VERSION ""

NS_ :

BS_:

BU_: FUSION IVI HMI Meter DataCenter WCM

BO_ 969 ZONE_FR_Version: 48 FUSION
 SG_ ZONE_FR_SW_Var1 : 135|8@0+ (1,0) [0|255] "" IVI
 SG_ ZONE_FR_SW_Country2 : 127|8@0+ (1,0) [0|255] "" IVI
 SG_ ZONE_FR_SW_Country1 : 119|8@0+ (1,0) [0|255] "" IVI
 SG_ ZONE_FR_SW_Patch2 : 111|8@0+ (1,0) [0|255] "" IVI
 SG_ ZONE_FR_SW_Patch1 : 103|8@0+ (1,0) [0|255] "" IVI
 SG_ ZONE_FR_SW_Minor2 : 95|8@0+ (1,0) [0|255] "" IVI
 SG_ ZONE_FR_SW_Minor1 : 87|8@0+ (1,0) [0|255] "" IVI
 SG_ ZONE_FR_SW_Major2 : 79|8@0+ (1,0) [0|255] "" IVI
 SG_ ZONE_FR_SW_Major1 : 71|8@0+ (1,0) [0|255] "" IVI
 SG_ ZONE_FR_SW_Controller2 : 63|8@0+ (1,0) [0|255] "" IVI
 SG_ ZONE_FR_SW_Controller1 : 55|8@0+ (1,0) [0|255] "" IVI
 SG_ ZONE_FR_SW_CarModel3 : 47|8@0+ (1,0) [0|255] "" IVI
 SG_ ZONE_FR_SW_CarModel2 : 39|8@0+ (1,0) [0|255] "" IVI
 SG_ ZONE_FR_SW_CarModel1 : 31|8@0+ (1,0) [0|255] "" IVI
 SG_ ZONE_FR_HW_Ver3 : 23|8@0+ (1,0) [0|255] "" IVI
 SG_ ZONE_FR_HW_Ver2 : 15|8@0+ (1,0) [0|255] "" IVI
 SG_ ZONE_FR_HW_Ver1 : 7|8@0+ (1,0) [0|255] "" IVI
 SG_ ZONE_FR_SW_dash1 : 191|8@0+ (1,0) [0|255] "" IVI
 SG_ ZONE_FR_SW_change1 : 199|8@0+ (1,0) [0|255] "" IVI
 SG_ ZONE_FR_SW_change2 : 207|8@0+ (1,0) [0|255] "" IVI
 SG_ ZONE_FR_SW_dash2 : 215|8@0+ (1,0) [0|255] "" IVI
 SG_ ZONE_FR_SW_SHA1 : 223|8@0+ (1,0) [0|255] "" IVI
 SG_ ZONE_FR_SW_SHA2 : 231|8@0+ (1,0) [0|255] "" IVI
 SG_ ZONE_FR_SW_SHA3 : 239|8@0+ (1,0) [0|255] "" IVI
 SG_ ZONE_FR_SW_SHA4 : 247|8@0+ (1,0) [0|255] "" IVI
 SG_ ZONE_FR_SW_SHA5 : 255|8@0+ (1,0) [0|255] "" IVI
 SG_ ZONE_FR_SW_SHA6 : 263|8@0+ (1,0) [0|255] "" IVI
 SG_ ZONE_FR_SW_SHA7 : 271|8@0+ (1,0) [0|255] "" IVI
 SG_ ZONE_FR_SW_SHA8 : 279|8@0+ (1,0) [0|255] "" IVI
 SG_ ZONE_FR_SW_ECUGen2 : 151|8@0+ (1,0) [0|255] "" IVI
 SG_ ZONE_FR_SW_ECUGen1 : 143|8@0+ (1,0) [0|255] "" IVI
 SG_ ZONE_FR_SW_Var5 : 183|8@0+ (1,0) [0|255] "" IVI
 SG_ ZONE_FR_SW_Var4 : 175|8@0+ (1,0) [0|255] "" IVI
 SG_ ZONE_FR_SW_Var3 : 167|8@0+ (1,0) [0|255] "" IVI
 SG_ ZONE_FR_SW_Var2 : 159|8@0+ (1,0) [0|255] "" IVI

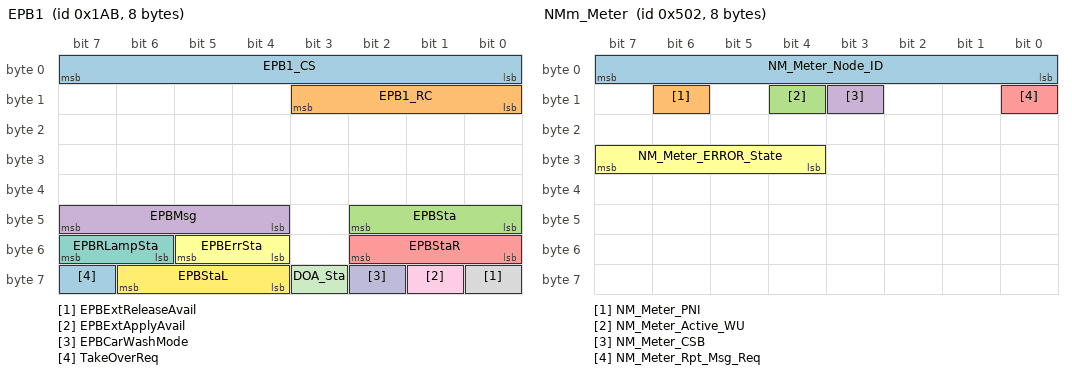
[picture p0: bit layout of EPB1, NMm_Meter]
BO_ 427 EPB1: 8 FUSION
 SG_ EPB1_CS : 7|8@0+ (1,0) [0|255] "" Vector__XXX
 SG_ EPB1_RC : 11|4@0+ (1,0) [0|14] "" Vector__XXX
 SG_ EPBSta : 42|3@0+ (1,0) [0|4] "" IVI
 SG_ EPBMsg : 47|4@0+ (1,0) [0|12] "" IVI
 SG_ EPBStaR : 50|3@0+ (1,0) [0|7] "" IVI
 SG_ EPBErrSta : 53|2@0+ (1,0) [0|2] "" IVI,Meter
 SG_ EPBRLampSta : 55|2@0+ (1,0) [0|2] "" IVI
 SG_ EPBExtReleaseAvail : 56|1@0+ (1,0) [0|1] "" Vector__XXX
 SG_ EPBExtApplyAvail : 57|1@0+ (1,0) [0|1] "" Vector__XXX
 SG_ EPBCarWashMode : 58|1@0+ (1,0) [0|1] "" IVI
 SG_ DOA_Sta : 59|1@0+ (1,0) [0|1] "" IVI
 SG_ EPBStaL : 62|3@0+ (1,0) [0|7] "" IVI
 SG_ TakeOverReq : 63|1@0+ (1,0) [0|1] "" Vector__XXX

BO_ 602 METER1: 24 IVI
 SG_ METER_KPH_Calcu : 15|8@0+ (1,0) [0|254] "km/h" FUSION
 SG_ METER_MPH_Calcu : 23|8@0+ (1,0) [0|160] "mph" FUSION
 SG_ METER_KPH_Real : 31|12@0+ (0.125,0) [0|255.875] "km/h" FUSION
 SG_ METER_MPH_Real : 35|12@0+ (0.077675,0) [0|160.0105] "mph" FUSION
 SG_ Averaged_vehspeed : 49|10@0+ (1,0) [0|300] "km/h" FUSION
 SG_ AVGPwrConsumption : 71|16@0+ (0.1,-999.9) [-999.9|999.9] "Wh/km" FUSION
 SG_ APCforDTE : 87|16@0+ (0.1,-999.9) [-999.9|999.9] "Wh/km" FUSION
 SG_ AvailableTrip : 103|16@0+ (0.1,0) [0|999.9] "KM" FUSION
 SG_ Spd_Crl_Mode : 118|3@0+ (1,0) [0|7] "" FUSION
 SG_ Spd_Crl_Sta : 115|1@0+ (1,0) [0|1] "" FUSION
 SG_ LEDlitWarnReq : 114|1@0+ (1,0) [0|1] "" FUSION
 SG_ Charge : 113|1@0+ (1,0) [0|1] "" FUSION
 SG_ ParkBrake : 112|1@0+ (1,0) [0|1] "" FUSION
 SG_ Trip_B : 127|24@0+ (0.1,0) [0|99999.9] "KM" FUSION
 SG_ Trip_A : 151|24@0+ (0.1,0) [0|99999.9] "KM" FUSION
 SG_ ODOMETER : 175|24@0+ (0.1,0) [0|999999.9] "KM" FUSION

BO_ 1168 IVI1: 20 IVI
 SG_ VehACModReq : 23|3@0+ (1,0) [0|7] "" FUSION
 SG_ FCP_FrEvt_BtnACMaxReq : 20|1@0+ (1,0) [0|1] "" FUSION
 SG_ FCP_FrEvt_BtnACReq : 19|1@0+ (1,0) [0|1] "" FUSION
 SG_ FCP_FrEvt_BtnAutoReq : 18|1@0+ (1,0) [0|1] "" FUSION
 SG_ FCP_MidEvt_BtnAutoReq : 17|1@0+ (1,0) [0|1] "" FUSION
 SG_ FCP_FrEvt_BtnSyncReq : 16|1@0+ (1,0) [0|1] "" FUSION
 SG_ OTA_DL_Req : 31|1@0+ (1,0) [0|1] "" FUSION
 SG_ OTA_SuspendDL_Req : 30|1@0+ (1,0) [0|1] "" FUSION
 SG_ OTA_UpdStart_Req : 29|1@0+ (1,0) [0|1] "" FUSION
 SG_ IVI_OTA_Upd_Sta : 28|2@0+ (1,0) [0|3] "" FUSION
 SG_ OTA_CancelDL_Req : 26|1@0+ (1,0) [0|1] "" FUSION
 SG_ SmartEco_Mode_SW : 25|1@0+ (1,0) [0|1] "" FUSION
 SG_ LINKtoDrive : 24|1@0+ (1,0) [0|1] "" FUSION
 SG_ Upd_Countdown_Skip : 39|1@0+ (1,0) [0|1] "" FUSION
 SG_ Upd_Countdown_Cancel : 38|1@0+ (1,0) [0|1] "" FUSION
 SG_ AmbLightColorSet : 46|7@0+ (1,0) [0|127] "" FUSION
 SG_ Sched_OTA_wake : 47|1@0+ (1,0) [0|1] "" FUSION
 SG_ UserSet : 71|3@0+ (1,0) [0|7] "" FUSION
 SG_ AmbLightBrightnessSet : 54|7@0+ (1,0) [0|127] "" FUSION
 SG_ Sched_Chg_Day_Set : 62|1@0+ (1,0) [0|1] "" FUSION
 SG_ Re_Radio_Sta : 63|1@0+ (1,0) [0|1] "" FUSION
 SG_ Sched_Chg_St_Time_Min : 61|6@0+ (1,0) [0|59] "MINUTE" FUSION
 SG_ A2B_Node_sta : 55|1@0+ (1,0) [0|1] "" FUSION
 SG_ Sched_Chg_St_Time_HR : 68|5@0+ (1,0) [0|23] "HOUR" FUSION
 SG_ IVI_Located_STA : 79|2@0+ (1,0) [0|3] "" FUSION
 SG_ Sched_Chg_End_Time_Min : 77|6@0+ (1,0) [0|59] "MINUTE" FUSION
 SG_ OTA_CompNTFY_Pres : 86|1@0+ (1,0) [0|1] "" FUSION
 SG_ BrkAbn_GoReady_SW : 85|1@0+ (1,0) [0|1] "" FUSION
 SG_ Sched_Chg_End_Time_HR : 84|5@0+ (1,0) [0|23] "HOUR" FUSION
 SG_ IVI_Time_Check : 95|8@0+ (1,0) [0|255] "" FUSION
 SG_ PW_CONTINUE_USE : 103|1@0+ (1,0) [0|1] "" FUSION
 SG_ PW_CLOSE_IMD : 102|1@0+ (1,0) [0|1] "" FUSION
 SG_ IVI_Time_Second : 101|6@0+ (1,0) [0|63] "SECOND" FUSION
 SG_ IVI_Time_Minute : 109|6@0+ (1,0) [0|63] "MINUTE" FUSION
 SG_ IVI_Time_Day : 116|5@0+ (1,0) [0|31] "DAY" FUSION
 SG_ IVI_Time_Hour : 124|5@0+ (1,0) [0|31] "HOUR" FUSION
 SG_ IVI_Time_Month : 131|4@0+ (1,0) [0|12] "MONTH" FUSION
 SG_ IVI_Time_Year : 142|7@0+ (1,2000) [2000|2127] "YEAR" FUSION
 SG_ mFRD_link_Sta : 87|1@0+ (1,0) [0|1] "" FUSION
 SG_ AmbLight_SW : 36|1@0+ (1,0) [0|1] "" FUSION
 SG_ AmbLight_DimInDark_SW : 35|1@0+ (1,0) [0|1] "" FUSION
 SG_ AmbLight_WlcmLight_SW : 34|1@0+ (1,0) [0|1] "" FUSION
 SG_ AmbLigh_LowBatAlert_SW : 33|1@0+ (1,0) [0|1] "" FUSION
 SG_ AmbLigh_SafetyAlert_SW : 32|1@0+ (1,0) [0|1] "" FUSION
 SG_ OpenDrOpenWdo_SW : 37|1@0+ (1,0) [0|1] "" FUSION
 SG_ IVI_LinkKey_Sta : 135|4@0+ (1,0) [0|15] "" FUSION
 SG_ IVI_CreateAccReq_Sta : 127|3@0+ (1,0) [0|7] "" FUSION
 SG_ IVI_DelAccReq_Sta : 119|3@0+ (1,0) [0|7] "" FUSION
 SG_ IVI_LinkAcc_Sta : 146|3@0+ (1,0) [0|7] "" FUSION
 SG_ IVI_LinkAccReq_Sta : 143|1@0+ (1,0) [0|1] "" FUSION
 SG_ IVI_FrTrunk_UnlockReq_Sta : 147|1@0+ (1,0) [0|1] "" FUSION
 SG_ IVI_CLWin_LockDoorSW_Sta : 148|1@0+ (1,0) [0|1] "" FUSION
 SG_ IVI_Lock_SoundSW_Sta : 149|1@0+ (1,0) [0|1] "" FUSION
 SG_ IVI_SWC_VibMode_Sta : 111|2@0+ (1,0) [0|3] "" FUSION
 SG_ IVI_DMS_SW_Sta : 150|1@0+ (1,0) [0|1] "" FUSION
 SG_ IVI_AirRefresh_ByDMS_Sta : 151|1@0+ (1,0) [0|1] "" FUSION
 SG_ IVI_QuickRefresh_Sta : 159|1@0+ (1,0) [0|1] "" FUSION
 SG_ IVI_HMI_Undefined_Sta : 158|3@0+ (1,0) [0|7] "" FUSION
 SG_ IVI_AutoTheme_But_Sta : 154|1@0+ (1,0) [0|1] "" FUSION
 SG_ IVI_NAVI_Foreground_Sta : 155|1@0+ (1,0) [0|1] "" FUSION
 SG_ IVI_sigScreenReq_Sta : 152|1@0+ (1,0) [0|1] "" FUSION
 SG_ IVI_DSEAT_anti_set_Sta : 153|1@0+ (1,0) [0|1] "" FUSION
 SG_ IVI_MirrorFolded_SW_Sta : 7|1@0+ (1,0) [0|1] "" FUSION
 SG_ IVI_WPTC_SW_Sta : 6|1@0+ (1,0) [0|1] "" FUSION
 SG_ IVI_Driving_Lock_SW_Sta : 5|1@0+ (1,0) [0|1] "" FUSION
 SG_ IVI_Stopping_Unlock_SW_Sta : 4|1@0+ (1,0) [0|1] "" FUSION
 SG_ IVI_SilentChrg_Alert_Sta : 3|1@0+ (1,0) [0|1] "" FUSION
 SG_ IVI_WirelessCharge_Cmd : 2|1@0+ (1,0) [0|1] "" FUSION
 SG_ IVI_Theme_Sta : 1|2@0+ (1,0) [0|3] "" FUSION
 SG_ IVI_EPS_Force_Cmd : 15|2@0+ (1,0) [0|3] "" FUSION
 SG_ IVI_DSEAT_StopKeepMove_Sta : 13|2@0+ (1,0) [0|3] "" FUSION
 SG_ IVI_AutoWipHSpdSW_Cmd : 11|1@0+ (1,0) [0|1] "" FUSION
 SG_ IVI_DSEAT_entryfun_set_Sta : 10|1@0+ (1,0) [0|1] "" FUSION

BO_ 1173 IVI2: 64 IVI
 SG_ SOC_V2LLimit : 7|4@0+ (1,0) [0|15] "%" FUSION
 SG_ Perd_V2L : 3|4@0+ (1,0) [0|15] "" FUSION
 SG_ IVI_Req_V2L : 17|2@0+ (1,0) [0|2] "" FUSION
 SG_ IVI_PTG_Open_Height : 14|3@0+ (1,0) [0|7] "" FUSION
 SG_ IVI_CreepSW_Req : 11|1@0+ (1,0) [0|1] "" FUSION
 SG_ FalseNPrevent_SW : 10|1@0+ (1,0) [0|1] "" FUSION
 SG_ Approach_Unlock_SW : 9|1@0+ (1,0) [0|1] "" FUSION
 SG_ Walkaway_Lock_SW : 8|1@0+ (1,0) [0|1] "" FUSION
 SG_ Sched_Chg_limit : 84|5@0+ (2,50) [50|100] "%" FUSION
 SG_ Sched_Chg_Stop : 95|1@0+ (1,0) [0|1] "" FUSION
 SG_ Sched_Chg_butt : 94|1@0+ (1,0) [0|1] "" FUSION
 SG_ Sched_Chg_wake : 93|1@0+ (1,0) [0|1] "" FUSION
 SG_ Sched_Chg_Start : 92|1@0+ (1,0) [0|1] "" FUSION
 SG_ sigFaceReq : 91|1@0+ (1,0) [0|1] "" FUSION
 SG_ sigFootReq : 90|1@0+ (1,0) [0|1] "" FUSION
 SG_ METER_Malfunc_Sta : 89|2@0+ (1,0) [0|2] "" FUSION
 SG_ IVI_Start_Chg_req : 103|1@0+ (1,0) [0|1] "" FUSION
 SG_ L_RRD_ControlCommand : 102|7@0+ (1,0) [0|127] "%" FUSION
 SG_ IVI_Stop_Chg_req : 111|1@0+ (1,0) [0|1] "" FUSION
 SG_ L_RLD_ControlCommand : 110|7@0+ (1,0) [0|127] "%" FUSION
 SG_ IVI_Unlock_Chg_req : 119|1@0+ (1,0) [0|1] "" FUSION
 SG_ L_Pas_ControlCommand : 118|7@0+ (1,0) [0|127] "%" FUSION
 SG_ TPMS_Cali_Butt : 127|1@0+ (1,0) [0|1] "" FUSION
 SG_ L_Drv_ControlCommand : 126|7@0+ (1,0) [0|127] "%" FUSION
 SG_ GPS_LONG : 135|32@0+ (1,0) [0|4.294967295E9] "" FUSION
 SG_ GPS_LAT : 167|32@0+ (1,0) [0|4.294967295E9] "SECOND" FUSION
 SG_ sigDfrstReq : 199|1@0+ (1,0) [0|1] "" FUSION
 SG_ sigHvacFrontReq : 198|1@0+ (1,0) [0|1] "" FUSION
 SG_ sigSetTempZon1Req : 197|6@0+ (0.5,17) [17|32] "Deg^C" FUSION
 SG_ sigHvacReq : 207|1@0+ (1,0) [0|1] "" FUSION
 SG_ sigRecircReq : 206|1@0+ (1,0) [0|1] "" FUSION
 SG_ sigSetTempZon2Req : 205|6@0+ (0.5,17) [17|32] "Deg^C" FUSION
 SG_ sigSetTempZon3Req : 215|6@0+ (0.5,17) [17|32] "Deg^C" FUSION
 SG_ AEB_BUTT : 209|2@0+ (1,0) [0|3] "" FUSION
 SG_ sigAirIntenZon1Req : 223|4@0+ (1,0) [0|15] "" FUSION
 SG_ sigAirIntenZon3Req : 219|4@0+ (1,0) [0|15] "" FUSION
 SG_ sigWindDirZon3Req : 228|3@0+ (1,0) [0|7] "" FUSION
 SG_ BSDMute_BUTT : 225|2@0+ (1,0) [0|3] "" FUSION
 SG_ LDWMute_BUTT : 239|2@0+ (1,0) [0|3] "" FUSION
 SG_ ODAMute_BUTT : 237|2@0+ (1,0) [0|3] "" FUSION
 SG_ LKA_BUTT : 235|2@0+ (1,0) [0|3] "" FUSION
 SG_ FCWMute_BUTT : 233|2@0+ (1,0) [0|3] "" FUSION
 SG_ sigHvacRearReq : 247|1@0+ (1,0) [0|1] "" FUSION
 SG_ IVI_Panel_Act : 246|1@0+ (1,0) [0|1] "" FUSION
 SG_ ESC_SW_Cmd : 245|2@0+ (1,0) [0|3] "" FUSION
 SG_ Distance_unit : 243|1@0+ (1,0) [0|1] "" FUSION
 SG_ Temperature_unit : 242|1@0+ (1,0) [0|1] "" FUSION
 SG_ NAVI_Speed_Limit_A : 241|2@0+ (1,0) [0|3] "" FUSION
 SG_ Time_system : 255|8@0+ (1,0) [0|255] "" FUSION
 SG_ Pressure_unit : 263|8@0+ (1,0) [0|255] "" FUSION
 SG_ TurnSwTimeSet : 271|2@0+ (1,0) [0|3] "" FUSION
 SG_ IVI_Screen : 269|6@0+ (1,0) [0|62] "" FUSION
 SG_ NAVI_Direction_STA : 279|8@0+ (1,0) [0|255] "" FUSION
 SG_ Wifi_Reset : 287|1@0+ (1,0) [0|1] "" FUSION
 SG_ CameraWrn : 286|1@0+ (1,0) [0|1] "" FUSION
 SG_ User_p_upload : 285|1@0+ (1,0) [0|1] "" FUSION
 SG_ IVI_PW_Mode_Req : 284|2@0+ (1,0) [0|3] "" FUSION
 SG_ OFF_AC_MODE : 282|3@0+ (1,0) [0|7] "" FUSION
 SG_ NAVI_Cam_Dist_info : 295|8@0+ (1,0) [0|255] "m" FUSION
 SG_ IVI_Panel_X_Coor : 303|12@0+ (1,0) [0|4095] "" FUSION
 SG_ IVI_Panel_Y_Coor : 307|12@0+ (1,0) [0|4095] "" FUSION
 SG_ Wifi_Sta_IVI_TBOX : 327|4@0+ (1,0) [0|15] "" FUSION
 SG_ NAVI_State : 323|2@0+ (1,0) [0|3] "" FUSION
 SG_ HeadLampSW : 321|2@0+ (1,0) [0|3] "" FUSION
 SG_ User_p_download : 335|1@0+ (1,0) [0|1] "" FUSION
 SG_ MFRD_N_Bright_Req : 334|7@0+ (1,0) [0|100] "%" FUSION
 SG_ RFogLampSW : 343|1@0+ (1,0) [0|1] "" FUSION
 SG_ DSEAT_vent_req : 342|3@0+ (1,0) [0|7] "" FUSION
 SG_ FFogLampSW : 339|1@0+ (1,0) [0|1] "" FUSION
 SG_ PSEAT_vent_req : 338|3@0+ (1,0) [0|7] "" FUSION
 SG_ FS_Off_Sw : 351|2@0+ (1,0) [0|3] "" FUSION
 SG_ SLG_Sw : 349|2@0+ (1,0) [0|3] "" FUSION
 SG_ IVI_PTG_Sta_SW : 347|2@0+ (1,0) [0|3] "" FUSION
 SG_ IVI_PTG_Mode_SW : 345|2@0+ (1,0) [0|3] "" FUSION
 SG_ SetUnlockSingle : 359|1@0+ (1,0) [0|1] "" FUSION
 SG_ FollowMeSW : 358|1@0+ (1,0) [0|1] "" FUSION
 SG_ TPMS_Res_Butt : 357|1@0+ (1,0) [0|1] "" FUSION
 SG_ DSEAT_anti_set : 355|1@0+ (1,0) [0|1] "" FUSION
 SG_ DSEAT_entryfun_set : 354|1@0+ (1,0) [0|1] "" FUSION
 SG_ CAAS_Sw : 353|2@0+ (1,0) [0|3] "" FUSION
 SG_ LVDAMute_BUTT : 367|2@0+ (1,0) [0|3] "" FUSION
 SG_ IVI_Status : 365|1@0+ (1,0) [0|1] "" FUSION
 SG_ IVI_Night_Mode_Sta : 364|1@0+ (1,0) [0|1] "" FUSION
 SG_ IVI_RR_Def_Req : 363|1@0+ (1,0) [0|1] "" FUSION
 SG_ IVI_WI_MAIN_SW : 362|1@0+ (1,0) [0|1] "" FUSION
 SG_ IVI_PTG_USSta_SW : 361|1@0+ (1,0) [0|1] "" FUSION
 SG_ IVI_Mute_Sta : 360|1@0+ (1,0) [0|1] "" FUSION
 SG_ NAVI_Distance_info : 375|24@0+ (1,0) [0|1.6777215E7] "m" FUSION
 SG_ AVM_Err_STA : 399|1@0+ (1,0) [0|1] "" FUSION
 SG_ IVI_Trigger_req : 398|1@0+ (1,0) [0|1] "" FUSION
 SG_ IVI_Pwroff_req : 397|1@0+ (1,0) [0|1] "" FUSION
 SG_ RCTA_BUTT : 396|2@0+ (1,0) [0|3] "" FUSION
 SG_ Hood_Latch_SW : 393|2@0+ (1,0) [0|3] "" FUSION
 SG_ AVM_Parking_mode : 407|4@0+ (1,0) [0|15] "" FUSION
 SG_ SenstivityPosition : 403|4@0+ (1,0) [0|15] "" FUSION
 SG_ NAVI_ForwardLinkLevel : 415|4@0+ (1,0) [0|15] "" FUSION
 SG_ NAVI_Tunnel : 411|12@0+ (1,0) [0|2000] "m" FUSION
 SG_ NAVI_LinkClass : 431|4@0+ (1,0) [0|15] "" FUSION
 SG_ NAVI_Tollgate : 427|12@0+ (1,0) [0|2000] "m" FUSION
 SG_ NAVI_RoadClass : 447|3@0+ (1,0) [0|7] "" FUSION
 SG_ NAVI_SpeedLimit : 444|5@0+ (1,0) [0|31] "km/h" FUSION
 SG_ RoomLampMode : 455|1@0+ (1,0) [0|1] "" FUSION
 SG_ IVI_ISA_OffsetSpd : 451|4@0+ (1,0) [0|14] "" FUSION
 SG_ AC_Chg_Cur_Set : 462|7@0+ (1,5) [5|132] "A" FUSION
 SG_ SOC_ADJ_BUTT : 471|1@0+ (1,0) [0|1] "" FUSION
 SG_ CDL_Unlock_Butt : 470|1@0+ (1,0) [0|1] "" FUSION
 SG_ CDL_Lock_Butt : 469|1@0+ (1,0) [0|1] "" FUSION
 SG_ SOC_Limit_Set : 468|5@0+ (2,50) [50|100] "%" FUSION
 SG_ Roll_Eng_Mode : 478|1@0+ (1,0) [0|1] "" FUSION
 SG_ SLIF_BUTT : 477|2@0+ (1,0) [0|2] "" FUSION
 SG_ TCS_SW_Cmd : 475|2@0+ (1,0) [0|3] "" FUSION
 SG_ Roll_Mode_SW_Cmd : 473|2@0+ (1,0) [0|3] "" FUSION
 SG_ IVI_ActvDmpDisabSW : 503|2@0+ (1,0) [0|3] "" FUSION
 SG_ IVI_CoastDwSW : 501|2@0+ (1,0) [0|3] "" FUSION
 SG_ IVI_PwrLockSW : 499|2@0+ (1,0) [0|3] "" FUSION
 SG_ IVI_LVChrgFuncSW : 497|2@0+ (1,0) [0|3] "" FUSION
 SG_ IVI_AGSCloseSW : 511|2@0+ (1,0) [0|3] "" FUSION
 SG_ AVM_OFF_Rec_Butt : 508|1@0+ (1,0) [0|1] "" FUSION
 SG_ AVM_parking_excute : 507|2@0+ (1,0) [0|3] "" FUSION
 SG_ AVM_parking_cancel : 505|2@0+ (1,0) [0|3] "" FUSION
 SG_ IVI_DSEATHeater_Cmd : 23|3@0+ (1,0) [0|7] "" FUSION
 SG_ IVI_PSEATHeater_Cmd : 20|3@0+ (1,0) [0|7] "" FUSION
 SG_ WlcmLight_Mode : 31|2@0+ (1,0) [0|3] "" FUSION
 SG_ IVI_CfmTo_Rdy : 15|1@0+ (1,0) [0|1] "" FUSION
 SG_ Light_ShowStart_Req : 29|1@0+ (1,0) [0|1] "" FUSION
 SG_ Light_ShowStop_Req : 28|1@0+ (1,0) [0|1] "" FUSION
 SG_ IVI_TrailerCheckReq_Sta : 356|1@0+ (1,0) [0|1] "" FUSION
 SG_ IVI_TrailerModeSW_Sta : 394|1@0+ (1,0) [0|1] "" FUSION
 SG_ IVI_FGSAirInt_Cmd : 87|3@0+ (1,0) [0|7] "" FUSION
 SG_ IVI_FGSCh_Cmd : 231|2@0+ (1,0) [0|3] "" FUSION
 SG_ IVI_IONSW_Cmd : 229|1@0+ (1,0) [0|1] "" FUSION
 SG_ IVI_SWC_ACCMode_Sta : 463|1@0+ (1,0) [0|1] "" FUSION
 SG_ IVI_SWC_LUndefined_Sta : 75|4@0+ (1,0) [0|15] "" FUSION
 SG_ IVI_SWC_RUndefined_Sta : 79|4@0+ (1,0) [0|15] "" FUSION
 SG_ IVI_ACC_Adaptive_Sta : 454|1@0+ (1,0) [0|1] "" FUSION
 SG_ IVI_SLIF_Warning_Sta : 453|2@0+ (1,0) [0|3] "" FUSION
 SG_ IVI_SetTempZon1_Sta : 39|5@0+ (1,0) [0|31] "" FUSION
 SG_ IVI_SetTempZon2_Sta : 47|5@0+ (1,0) [0|31] "" FUSION
 SG_ IVI_AirIntZ3_Cmd : 34|3@0+ (1,0) [0|7] "" FUSION
 SG_ IVI_DSEAT_Slide_Cmd : 25|2@0+ (1,0) [0|3] "" FUSION
 SG_ IVI_DSEAT_Recline_Cmd : 55|2@0+ (1,0) [0|3] "" FUSION
 SG_ IVI_DSEAT_Height_Cmd : 53|2@0+ (1,0) [0|3] "" FUSION
 SG_ IVI_DSEAT_FroEdge_Height_Cmd : 51|2@0+ (1,0) [0|3] "" FUSION
 SG_ IVI_PSEAT_Slide_Cmd : 49|2@0+ (1,0) [0|3] "" FUSION
 SG_ IVI_PSEAT_Recline_Cmd : 41|2@0+ (1,0) [0|3] "" FUSION
 SG_ IVI_ChargePortSW_Sta : 479|1@0+ (1,0) [0|1] "" FUSION
 SG_ IVI_DSEAT_Memory1_Sta : 27|1@0+ (1,0) [0|1] "" FUSION
 SG_ IVI_DSEAT_Memory2_Sta : 26|1@0+ (1,0) [0|1] "" FUSION
 SG_ IVI_DSEAT_Memory_OPTCLS_Sta : 42|1@0+ (1,0) [0|1] "" FUSION
 SG_ DMS_Status : 61|2@0+ (1,0) [0|3] "" FUSION
 SG_ DMS_Warning_Distraction : 59|2@0+ (1,0) [0|3] "" FUSION
 SG_ DMS_Warning_Fatigue : 57|2@0+ (1,0) [0|3] "" FUSION
 SG_ DMS_Warning_Unresponsive : 62|1@0+ (1,0) [0|1] "" FUSION
 SG_ IVI_FWipIntTSet_Cmd : 71|3@0+ (1,0) [0|7] "" FUSION
 SG_ IVI_CarWash_Mode_Cmd : 63|1@0+ (1,0) [0|1] "" FUSION
 SG_ IVI_Backlight_Sta : 509|1@0+ (1,0) [0|1] "" FUSION
 SG_ IVI_GPS_Long_Dir_Sta : 67|2@0+ (1,0) [0|3] "" FUSION
 SG_ IVI_GPS_Lat_Dir_Sta : 65|2@0+ (1,0) [0|3] "" FUSION
 SG_ IVI_IC_Brightness_Sta : 486|7@0+ (1,0) [0|100] "" FUSION
 SG_ IVI_Off_Road_Mode_Sta : 68|1@0+ (1,0) [0|1] "" FUSION
 SG_ IVI_DMS_NoDriverDetected_Sta : 491|2@0+ (1,0) [0|3] "" FUSION
 SG_ IVI_DMS_Faceblocked_Sta : 489|2@0+ (1,0) [0|3] "" FUSION

BO_ 1282 NMm_Meter: 8 Meter
 SG_ NM_Meter_Node_ID : 7|8@0+ (1,0) [0|127] "" FUSION
 SG_ NM_Meter_PNI : 14|1@0+ (1,0) [0|1] "" FUSION
 SG_ NM_Meter_Active_WU : 12|1@0+ (1,0) [0|1] "" FUSION
 SG_ NM_Meter_CSB : 11|1@0+ (1,0) [0|1] "" FUSION
 SG_ NM_Meter_Rpt_Msg_Req : 8|1@0+ (1,0) [0|1] "" FUSION
 SG_ NM_Meter_ERROR_State : 31|4@0+ (1,0) [0|8] "" FUSION

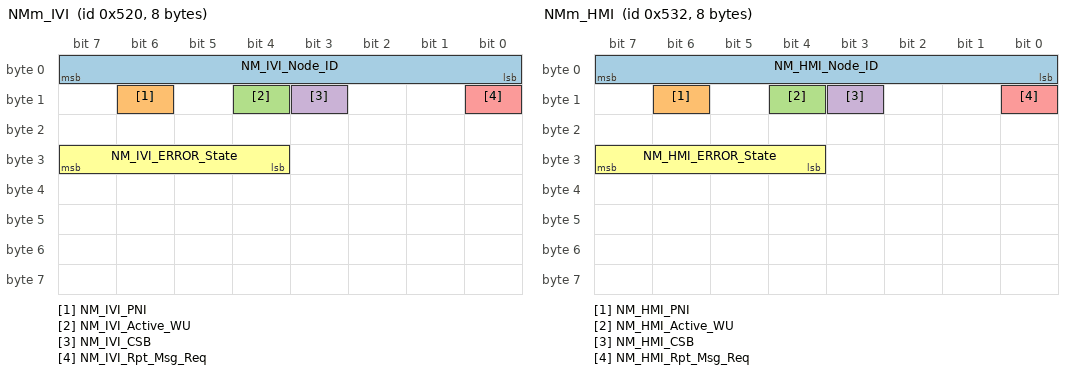
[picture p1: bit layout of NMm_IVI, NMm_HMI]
BO_ 1312 NMm_IVI: 8 IVI
 SG_ NM_IVI_Node_ID : 7|8@0+ (1,0) [0|127] "" FUSION
 SG_ NM_IVI_PNI : 14|1@0+ (1,0) [0|1] "" FUSION
 SG_ NM_IVI_Active_WU : 12|1@0+ (1,0) [0|1] "" FUSION
 SG_ NM_IVI_CSB : 11|1@0+ (1,0) [0|1] "" FUSION
 SG_ NM_IVI_Rpt_Msg_Req : 8|1@0+ (1,0) [0|1] "" FUSION
 SG_ NM_IVI_ERROR_State : 31|4@0+ (1,0) [0|8] "" FUSION

BO_ 1330 NMm_HMI: 8 HMI
 SG_ NM_HMI_Node_ID : 7|8@0+ (1,0) [0|127] "" FUSION
 SG_ NM_HMI_PNI : 14|1@0+ (1,0) [0|1] "" FUSION
 SG_ NM_HMI_Active_WU : 12|1@0+ (1,0) [0|1] "" FUSION
 SG_ NM_HMI_CSB : 11|1@0+ (1,0) [0|1] "" FUSION
 SG_ NM_HMI_Rpt_Msg_Req : 8|1@0+ (1,0) [0|1] "" FUSION
 SG_ NM_HMI_ERROR_State : 31|4@0+ (1,0) [0|8] "" FUSION

BO_ 1538 DiagRespFromMeter: 8 Meter
 SG_ DiagRespFromMeter : 7|64@0+ (1,0) [0|0] "" FUSION

BO_ 1568 DiagRespFromIVI: 8 IVI
 SG_ DiagRespFromIVI : 7|64@0+ (1,0) [0|0] "" FUSION

BO_ 1586 DiagRespFromHMI: 64 HMI
 SG_ DiagRespFromHMI : 7|64@0+ (1,0) [0|0] "" FUSION

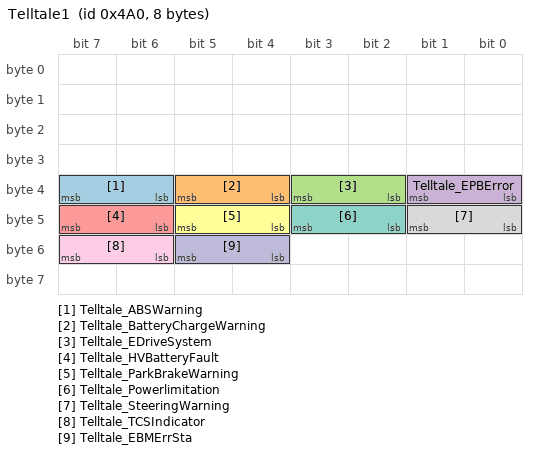
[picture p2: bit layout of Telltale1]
BO_ 1184 Telltale1: 8 Meter
 SG_ Telltale_ABSWarning : 39|2@0+ (1,0) [0|2] "" FUSION
 SG_ Telltale_BatteryChargeWarning : 37|2@0+ (1,0) [0|2] "" FUSION
 SG_ Telltale_EDriveSystem : 35|2@0+ (1,0) [0|2] "" FUSION
 SG_ Telltale_EPBError : 33|2@0+ (1,0) [0|2] "" FUSION
 SG_ Telltale_HVBatteryFault : 47|2@0+ (1,0) [0|2] "" FUSION
 SG_ Telltale_ParkBrakeWarning : 45|2@0+ (1,0) [0|2] "" FUSION
 SG_ Telltale_Powerlimitation : 43|2@0+ (1,0) [0|2] "" FUSION
 SG_ Telltale_SteeringWarning : 41|2@0+ (1,0) [0|2] "" FUSION
 SG_ Telltale_TCSIndicator : 55|2@0+ (1,0) [0|2] "" FUSION
 SG_ Telltale_EBMErrSta : 53|2@0+ (1,0) [0|3] "" FUSION

BO_ 857 GW2_CE100_2: 32 FUSION
 SG_ DSEAT_heater_sta : 66|3@0+ (1,0) [0|4] "" IVI
 SG_ DSEAT_Mode : 82|3@0+ (1,0) [0|7] "" IVI
 SG_ DSEAT_Vent_Sta : 74|3@0+ (1,0) [0|4] "" IVI
 SG_ PSEAT_heater_sta : 70|3@0+ (1,0) [0|4] "" IVI
 SG_ PSEAT_Mode : 86|3@0+ (1,0) [0|7] "" IVI
 SG_ PSEAT_Vent_Sta : 78|3@0+ (1,0) [0|4] "" IVI
 SG_ DSEAT_Anti_Sta : 75|1@0+ (1,0) [0|1] "" IVI
 SG_ DSEAT_EntryFun_Sta : 79|1@0+ (1,0) [0|1] "" IVI
 SG_ DSEAT_Error_Sta : 83|1@0+ (1,0) [0|1] "" IVI
 SG_ PSEAT_Error_Sta : 87|1@0+ (1,0) [0|1] "" IVI
 SG_ PTG_Active_Sta : 90|3@0+ (1,0) [0|7] "" IVI
 SG_ PTG_Sys_Sta : 93|2@0+ (1,0) [0|3] "" IVI
 SG_ PTG_AutoStaus : 95|1@0+ (1,0) [0|1] "" IVI
 SG_ PTG_Exist : 91|1@0+ (1,0) [0|1] "" IVI
 SG_ PTG_Is_Set_Height : 94|1@0+ (1,0) [0|1] "" IVI
 SG_ Rr_TMSpd_Nidec : 167|16@0+ (1,-17000) [-17000|17000] "RPM" IVI
 SG_ Fr_TMSpd_Nidec : 247|16@0+ (1,-17000) [-17000|17000] "RPM" IVI
 SG_ Fr_EDURealTMTq_Nidec : 227|12@0+ (1,-1022) [-1022|1022] "Nm" IVI
 SG_ Fr_MotorAvailTq_Nidec : 211|12@0+ (1,0) [0|1022] "Nm" IVI
 SG_ Rr_EDURealTMTq_Nidec : 147|12@0+ (1,-1022) [-1022|1022] "Nm" IVI
 SG_ Rr_MotorAvailTq_Nidec : 131|12@0+ (1,0) [0|1022] "Nm" IVI
 SG_ Fr_MCUTemp_Nidec : 176|9@0+ (1,-40) [-40|254] "Deg^C" IVI
 SG_ Fr_TMTemp_Nidec : 192|9@0+ (1,-40) [-40|254] "Deg^C" IVI
 SG_ Rr_MCUTemp_Nidec : 96|9@0+ (1,-40) [-40|254] "Deg^C" IVI
 SG_ Rr_TMTemp_Nidec : 112|9@0+ (1,-40) [-40|254] "Deg^C" IVI
 SG_ Fr_MCUTempWarn_Nidec : 231|2@0+ (1,0) [0|3] "" IVI
 SG_ Fr_TMTempWarn_Nidec : 229|2@0+ (1,0) [0|3] "" IVI
 SG_ Rr_MCUTempWarn_Nidec : 151|2@0+ (1,0) [0|3] "" IVI
 SG_ Rr_TMTempWarn_Nidec : 149|2@0+ (1,0) [0|3] "" IVI
 SG_ Fr_EDUDrtSta_Nidec : 193|1@0+ (1,0) [0|1] "" IVI
 SG_ Rr_EDUDrtSta_Nidec : 113|1@0+ (1,0) [0|1] "" IVI
 SG_ L_Drv_Val_Wdw_Opened : 38|7@0+ (1,0) [0|100] "%" IVI
 SG_ L_Pas_Val_Wdw_Opened : 46|7@0+ (1,0) [0|100] "%" IVI
 SG_ L_RLD_Val_Wdw_Opened : 54|7@0+ (1,0) [0|100] "%" IVI
 SG_ L_RRD_Val_Wdw_Opened : 62|7@0+ (1,0) [0|100] "%" IVI
 SG_ FAPWL_01_LIN_Response_Error : 71|1@0+ (1,0) [0|1] "" IVI
 SG_ L_Drv_Motor_Relay_Error : 27|1@0+ (1,0) [0|1] "" IVI
 SG_ L_Drv_Motor_Ripple_Error : 39|1@0+ (1,0) [0|1] "" IVI
 SG_ L_Pas_Motor_Relay_Error : 26|1@0+ (1,0) [0|1] "" IVI
 SG_ L_Pas_Motor_Ripple_Error : 47|1@0+ (1,0) [0|1] "" IVI
 SG_ L_RLD_Motor_Relay_Error : 25|1@0+ (1,0) [0|1] "" IVI
 SG_ L_RLD_Motor_Ripple_Error : 55|1@0+ (1,0) [0|1] "" IVI
 SG_ L_RRD_Motor_Relay_Error : 24|1@0+ (1,0) [0|1] "" IVI
 SG_ L_RRD_Motor_Ripple_Error : 63|1@0+ (1,0) [0|1] "" IVI
 SG_ RAPWL_01_LIN_Response_Error : 67|1@0+ (1,0) [0|1] "" IVI

BO_ 855 GW2_CE100_1: 32 FUSION
 SG_ Rr_TMSpd : 167|16@0+ (1,-18000) [-18000|18000] "RPM" IVI
 SG_ Fr_TMSpd : 247|16@0+ (1,-18000) [-18000|18000] "RPM" IVI
 SG_ Fr_EDURealTMTq : 231|16@0+ (0.1,-1022) [-1022|5531.5] "Nm" IVI
 SG_ Fr_MotorAvailTq : 211|12@0+ (1,0) [0|1022] "Nm" IVI
 SG_ Rr_EDURealTMTq : 151|16@0+ (0.1,-1022) [-1022|5531.5] "Nm" IVI
 SG_ Rr_MotorAvailTq : 131|12@0+ (1,0) [0|1022] "Nm" IVI
 SG_ Fr_MCUTemp : 176|9@0+ (1,-40) [-40|254] "Deg^C" IVI
 SG_ Fr_TMTemp : 192|9@0+ (1,-40) [-40|254] "Deg^C" IVI
 SG_ Rr_MCUTemp : 96|9@0+ (1,-40) [-40|254] "Deg^C" IVI
 SG_ Rr_TMTemp : 112|9@0+ (1,-40) [-40|254] "Deg^C" IVI
 SG_ BD_DSEAT_Mode_Sta : 82|3@0+ (1,0) [0|7] "" IVI
 SG_ BD_DSEAT_Vent_Sta : 74|3@0+ (1,0) [0|4] "" IVI
 SG_ BP_PTG_Active_Sta : 90|3@0+ (1,0) [0|7] "" IVI
 SG_ BP_PSEAT_Mode_Sta : 86|3@0+ (1,0) [0|7] "" IVI
 SG_ BP_PSEAT_Vent_Sta : 78|3@0+ (1,0) [0|4] "" IVI
 SG_ Fr_MCUTempWarn : 215|2@0+ (1,0) [0|3] "" IVI
 SG_ Fr_TMTempWarn : 195|2@0+ (1,0) [0|3] "" IVI
 SG_ Rr_MCUTempWarn : 135|2@0+ (1,0) [0|3] "" IVI
 SG_ Rr_TMTempWarn : 115|2@0+ (1,0) [0|3] "" IVI
 SG_ BP_PTG_Sys_Sta : 93|2@0+ (1,0) [0|3] "" IVI
 SG_ Fr_EDUDrtSta : 193|1@0+ (1,0) [0|1] "" IVI
 SG_ Rr_EDUDrtSta : 113|1@0+ (1,0) [0|1] "" IVI
 SG_ BD_DSEAT_Anti_Sta : 75|1@0+ (1,0) [0|1] "" IVI
 SG_ BD_DSEAT_EntryFun_Sta : 79|1@0+ (1,0) [0|1] "" IVI
 SG_ BD_DSEAT_Error_Sta : 83|1@0+ (1,0) [0|1] "" IVI
 SG_ BP_PTG_Exist_Sta : 91|1@0+ (1,0) [0|1] "" IVI
 SG_ BP_PTG_IsSetHeight_Sta : 94|1@0+ (1,0) [0|1] "" IVI
 SG_ BP_PSEAT_Error_Sta : 87|1@0+ (1,0) [0|1] "" IVI
 SG_ BD_DSEAT_heater_Sta : 66|3@0+ (1,0) [0|4] "" IVI
 SG_ BP_PSEAT_heater_Sta : 70|3@0+ (1,0) [0|4] "" IVI
 SG_ MCU_B_R_LLCTempWarn_Sta : 133|2@0+ (1,0) [0|3] "" IVI
 SG_ MCU_B_F_LLCTempWarn_Sta : 213|2@0+ (1,0) [0|3] "" IVI
 SG_ SWC2_L_DriveMode_Sta : 71|1@0+ (1,0) [0|1] "" IVI
 SG_ SWC2_L_Home_Sta : 67|1@0+ (1,0) [0|1] "" IVI
 SG_ SWC2_R_Customize_Sta : 47|1@0+ (1,0) [0|1] "" IVI
 SG_ SWC2_R_Left_Sta : 23|1@0+ (1,0) [0|1] "" IVI
 SG_ SWC2_R_PageSwitch_Sta : 55|1@0+ (1,0) [0|1] "" IVI
 SG_ SWC2_R_Right_Sta : 22|1@0+ (1,0) [0|1] "" IVI
 SG_ SWC2_R_ScrollDown_Sta : 30|1@0+ (1,0) [0|1] "" IVI
 SG_ SWC2_R_ScrollPress_Sta : 39|1@0+ (1,0) [0|1] "" IVI
 SG_ SWC2_R_ScrollUp_Sta : 31|1@0+ (1,0) [0|1] "" IVI
 SG_ SWC2_R_VR_Sta : 63|1@0+ (1,0) [0|1] "" IVI
 SG_ BP_SEAT_MLVent_Sta : 29|3@0+ (1,0) [0|7] "" IVI
 SG_ BP_SEAT_MRVent_Sta : 26|3@0+ (1,0) [0|7] "" IVI
 SG_ BP_SEAT_LVent_Sta : 21|3@0+ (1,0) [0|7] "" IVI
 SG_ BP_SEAT_RVent_Sta : 18|3@0+ (1,0) [0|7] "" IVI
 SG_ BD_DSEAT_MemSet_Sta : 15|2@0+ (1,0) [0|3] "" IVI
 SG_ BD_DSEAT_StopKeepMove_Sta : 13|2@0+ (1,0) [0|3] "" IVI
 SG_ FDC_BCM_WinLFOpened_Sta : 38|7@0+ (1,0) [0|127] "%" IVI
 SG_ FDC_BCM_WinLROpened_Sta : 54|7@0+ (1,0) [0|127] "%" IVI
 SG_ FDC_BCM_WinRFOpened_Sta : 46|7@0+ (1,0) [0|127] "%" IVI
 SG_ FDC_BCM_WinRROpened_Sta : 62|7@0+ (1,0) [0|127] "%" IVI
 SG_ BD_Door_FHandleClose_Sta : 199|1@0+ (1,0) [0|1] "" IVI
 SG_ BD_Door_RHandleClose_Sta : 198|1@0+ (1,0) [0|1] "" IVI
 SG_ BP_Door_FHandleClose_Sta : 197|1@0+ (1,0) [0|1] "" IVI
 SG_ BP_Door_RHandleClose_Sta : 196|1@0+ (1,0) [0|1] "" IVI

BO_ 552 zGW_LINFr1: 32 FUSION
 SG_ AGS_Actual_Position : 7|8@0+ (1,0) [0|240] "" IVI
 SG_ AGS_Low_Voltage_Error : 15|1@0+ (1,0) [0|1] "" Vector__XXX
 SG_ AGS_Temperature_Error : 14|1@0+ (1,0) [0|1] "" Vector__XXX
 SG_ AGS_Sensor_Error : 13|1@0+ (1,0) [0|1] "" Vector__XXX
 SG_ AGS_Electrical_Error : 12|1@0+ (1,0) [0|1] "" Vector__XXX
 SG_ AGS_Calibration_Indicated : 11|1@0+ (1,0) [0|1] "" Vector__XXX
 SG_ AGS_Calibration_Active : 10|1@0+ (1,0) [0|1] "" Vector__XXX
 SG_ AGS_Actuator_Fault : 8|1@0+ (1,0) [0|1] "" Vector__XXX
 SG_ AGS_Actuator_Blocked : 9|1@0+ (1,0) [0|1] "" Vector__XXX
 SG_ AGS_LINResponse_Error : 23|1@0+ (1,0) [0|1] "" Vector__XXX
 SG_ ION_IONErr_Sta : 81|2@0+ (1,0) [0|3] "" IVI
 SG_ ION_IONRespErr_Sta : 83|1@0+ (1,0) [0|1] "" IVI
 SG_ ION_ION_Sta : 82|1@0+ (1,0) [0|1] "" IVI
 SG_ FGS_LifeHole3_Sta : 64|9@0+ (1,0) [0|360] "hr" IVI
 SG_ FGS_LifeHole2_Sta : 48|9@0+ (1,0) [0|360] "hr" IVI
 SG_ FGS_LifeHole1_Sta : 32|9@0+ (1,0) [0|360] "hr" IVI
 SG_ FGS_Channel3TypeRsp_Sta : 71|4@0+ (1,0) [0|15] "" IVI
 SG_ FGS_Channel2TypeRsp_Sta : 55|4@0+ (1,0) [0|15] "" IVI
 SG_ FGS_Channel1TypeRsp_Sta : 39|4@0+ (1,0) [0|15] "" IVI
 SG_ FGS_BlowerErr_Sta : 33|1@0+ (1,0) [0|1] "" IVI
 SG_ FGS_IntenRsp_Sta : 19|4@0+ (1,0) [0|15] "" IVI
 SG_ FGS_MotorErr_Sta : 49|1@0+ (1,0) [0|1] "" IVI
 SG_ FGS_TypRsp_Sta : 22|3@0+ (1,0) [0|7] "" IVI
 SG_ FGS_LINResponseErr_Sta : 87|1@0+ (1,0) [0|1] "" IVI
 SG_ FGS_StsRsp_Sta : 86|1@0+ (1,0) [0|1] "" IVI
 SG_ FGS_Channel_Type_Sta : 31|6@0+ (1,0) [0|63] "" IVI
 SG_ FGS_Channel_Index_Sta : 25|2@0+ (1,0) [0|3] "" IVI

BO_ 1169 HMI1: 8 HMI
 SG_ HMI_ACBtn_Cmd : 23|1@0+ (1,0) [0|1] "" FUSION
 SG_ HMI_ACAutoBtn_Cmd : 22|1@0+ (1,0) [0|1] "" FUSION
 SG_ HMI_ACRecycleBtn_Cmd : 21|1@0+ (1,0) [0|1] "" FUSION
 SG_ HMI_ACFrDefogBtn_Cmd : 20|1@0+ (1,0) [0|1] "" FUSION
 SG_ HMI_ZLSetTP_Cmd : 19|1@0+ (1,0) [0|1] "" FUSION
 SG_ HMI_ZLSetTM_Cmd : 18|1@0+ (1,0) [0|1] "" FUSION
 SG_ HMI_ZRSetTP_Cmd : 17|1@0+ (1,0) [0|1] "" FUSION
 SG_ HMI_ZRSetTM_Cmd : 16|1@0+ (1,0) [0|1] "" FUSION
 SG_ HMI_ACWindDirP_Cmd : 31|1@0+ (1,0) [0|1] "" FUSION
 SG_ HMI_ACWindDirM_Cmd : 30|1@0+ (1,0) [0|1] "" FUSION
 SG_ HMI_ACAirIntP_Cmd : 29|1@0+ (1,0) [0|1] "" FUSION
 SG_ HMI_ACAirIntM_Cmd : 28|1@0+ (1,0) [0|1] "" FUSION
 SG_ HMI_BCMPostDefogBtn_Cmd : 27|1@0+ (1,0) [0|1] "" FUSION
 SG_ HMI_AutoInterLight_Cmd : 26|1@0+ (1,0) [0|1] "" FUSION
 SG_ HMI_PSEAT_LevelDown_Cmd : 32|1@0+ (1,0) [0|1] "" FUSION
 SG_ HMI_PSEAT_LevelUp_Cmd : 33|1@0+ (1,0) [0|1] "" FUSION
 SG_ HMI_DSEAT_LevelDown_Cmd : 34|1@0+ (1,0) [0|1] "" FUSION
 SG_ HMI_DSEAT_LevelUp_Cmd : 35|1@0+ (1,0) [0|1] "" FUSION
 SG_ HMI_Function6_LevelDown_Cmd : 47|1@0+ (1,0) [0|1] "" FUSION
 SG_ HMI_Function5_LevelDown_Cmd : 46|1@0+ (1,0) [0|1] "" FUSION
 SG_ HMI_Function4_LevelDown_Cmd : 45|1@0+ (1,0) [0|1] "" FUSION
 SG_ HMI_Function3_LevelDown_Cmd : 44|1@0+ (1,0) [0|1] "" FUSION
 SG_ HMI_Function2_LevelDown_Cmd : 43|1@0+ (1,0) [0|1] "" FUSION
 SG_ HMI_Function1_LevelDown_Cmd : 42|1@0+ (1,0) [0|1] "" FUSION
 SG_ HMI_Function6_LevelUp_Cmd : 55|1@0+ (1,0) [0|1] "" FUSION
 SG_ HMI_Function5_LevelUp_Cmd : 54|1@0+ (1,0) [0|1] "" FUSION
 SG_ HMI_Function4_LevelUp_Cmd : 53|1@0+ (1,0) [0|1] "" FUSION
 SG_ HMI_Function3_LevelUp_Cmd : 52|1@0+ (1,0) [0|1] "" FUSION
 SG_ HMI_Function2_LevelUp_Cmd : 51|1@0+ (1,0) [0|1] "" FUSION
 SG_ HMI_Function1_LevelUp_Cmd : 50|1@0+ (1,0) [0|1] "" FUSION

BO_ 1175 IVI3: 32 IVI
 SG_ IVI_CLBlower_Y_Sta : 38|7@0+ (1,0) [0|127] "%" FUSION
 SG_ IVI_CLBlower_Z_Sta : 46|7@0+ (1,0) [0|127] "%" FUSION
 SG_ IVI_CRBlower_Y_Sta : 54|7@0+ (1,0) [0|127] "%" FUSION
 SG_ IVI_CRBlower_Z_Sta : 62|7@0+ (1,0) [0|127] "%" FUSION
 SG_ IVI_LBlower_Y_Sta : 6|7@0+ (1,0) [0|127] "%" FUSION
 SG_ IVI_LBlower_Z_Sta : 14|7@0+ (1,0) [0|127] "%" FUSION
 SG_ IVI_RBlower_Y_Sta : 22|7@0+ (1,0) [0|127] "%" FUSION
 SG_ IVI_RBlower_Z_Sta : 30|7@0+ (1,0) [0|127] "%" FUSION
 SG_ IVI_LSEATvent_Cmd : 101|3@0+ (1,0) [0|7] "" FUSION
 SG_ IVI_MLSEATvent_Cmd : 93|3@0+ (1,0) [0|7] "" FUSION
 SG_ IVI_MRSEATvent_Cmd : 90|3@0+ (1,0) [0|7] "" FUSION
 SG_ IVI_RSEATvent_Cmd : 98|3@0+ (1,0) [0|7] "" FUSION
 SG_ IVI_LBlower_Mode_Sta : 71|2@0+ (1,0) [0|3] "" FUSION
 SG_ IVI_MLFootLift_Cmd : 75|2@0+ (1,0) [0|3] "" FUSION
 SG_ IVI_MLRecliner_Cmd : 79|2@0+ (1,0) [0|3] "" FUSION
 SG_ IVI_MLSeatLift_Cmd : 73|2@0+ (1,0) [0|3] "" FUSION
 SG_ IVI_MLSlider_Cmd : 77|2@0+ (1,0) [0|3] "" FUSION
 SG_ IVI_MRFootLift_Cmd : 83|2@0+ (1,0) [0|3] "" FUSION
 SG_ IVI_MRRecliner_Cmd : 87|2@0+ (1,0) [0|3] "" FUSION
 SG_ IVI_MRSeatLift_Cmd : 81|2@0+ (1,0) [0|3] "" FUSION
 SG_ IVI_MRSlider_Cmd : 85|2@0+ (1,0) [0|3] "" FUSION
 SG_ IVI_RBlower_Mode_Sta : 69|2@0+ (1,0) [0|3] "" FUSION
 SG_ IVI_MLFMost_Cmd : 31|1@0+ (1,0) [0|1] "" FUSION
 SG_ IVI_MLNapMode_Cmd : 23|1@0+ (1,0) [0|1] "" FUSION
 SG_ IVI_MLRestore_Cmd : 15|1@0+ (1,0) [0|1] "" FUSION
 SG_ IVI_MLSldRestore_Cmd : 7|1@0+ (1,0) [0|1] "" FUSION
 SG_ IVI_MLZeroGravity_Cmd : 39|1@0+ (1,0) [0|1] "" FUSION
 SG_ IVI_MRFMost_Cmd : 94|1@0+ (1,0) [0|1] "" FUSION
 SG_ IVI_MRNapMode_Cmd : 63|1@0+ (1,0) [0|1] "" FUSION
 SG_ IVI_MRRestore_Cmd : 55|1@0+ (1,0) [0|1] "" FUSION
 SG_ IVI_MRSldRestore_Cmd : 47|1@0+ (1,0) [0|1] "" FUSION
 SG_ IVI_MRZeroGravity_Cmd : 95|1@0+ (1,0) [0|1] "" FUSION
 SG_ IVI_HMI_CustmiKEY_Sta : 67|4@0+ (1,0) [0|15] "" FUSION
 SG_ IVI_HMI_CustmiFun_Sta : 111|4@0+ (1,0) [0|15] "" FUSION
 SG_ IVI_SOS_Call_Sta : 103|2@0+ (1,0) [0|3] "" FUSION
 SG_ IVI_XWDMode_Cmd : 107|2@0+ (1,0) [0|3] "" FUSION
 SG_ IVI_RollMod_atCarWash_Sta : 105|1@0+ (1,0) [0|1] "" FUSION
 SG_ IVI_SnowMode_Cmd : 104|1@0+ (1,0) [0|1] "" FUSION
 SG_ IVI_UserTakeOver_APS_Sta : 119|1@0+ (1,0) [0|1] "" FUSION
 SG_ IVI_Zon1WindDirSWReq_Sta : 118|1@0+ (1,0) [0|1] "" FUSION
 SG_ IVI_PSDManualPower_Sta : 117|1@0+ (1,0) [0|1] "" FUSION
 SG_ IVI_RightPSDOpenClose_Cmd : 116|1@0+ (1,0) [0|1] "" FUSION
 SG_ IVI_LeftPSDOpenClose_Cmd : 115|1@0+ (1,0) [0|1] "" FUSION

BO_ 1687 DiagPhysReqToWCM: 64 FUSION
 SG_ DiagPhysReqToWCM : 7|64@0+ (1,0) [0|0] "" WCM

BO_ 1559 DiagRespFromWCM: 64 WCM
 SG_ DiagRespFromWCM : 7|64@0+ (1,0) [0|0] "" FUSION

BO_ 2015 DiagFuncReqOBD: 8 FUSION
 SG_ DiagFuncReqOBD : 7|64@0+ (1,0) [0|0] "" Vector__XXX

CM_ BO_ 857 "Nidec MCU/APM ECU/SEAT ECU/PTG ECU";
CM_ BO_ 855 "Bosch MCU/Zone APM/Zone SEAT/Zone PTG/SWC gen2";
CM_ BO_ 552 "Routing from LIN_FR1";
CM_ SG_ 969 ZONE_FR_SW_Var1 "software version car model variation 1";
CM_ SG_ 969 ZONE_FR_SW_Country2 "software version country of target market character 2";
CM_ SG_ 969 ZONE_FR_SW_Country1 "software version country of target market character 1";
CM_ SG_ 969 ZONE_FR_SW_Patch2 "software version patch character 2";
CM_ SG_ 969 ZONE_FR_SW_Patch1 "software version patch character 1";
CM_ SG_ 969 ZONE_FR_SW_Minor2 "software version minor character 2";
CM_ SG_ 969 ZONE_FR_SW_Minor1 "software version minor character 1";
CM_ SG_ 969 ZONE_FR_SW_Major2 "software version major character 2";
CM_ SG_ 969 ZONE_FR_SW_Major1 "software version major character 1";
CM_ SG_ 969 ZONE_FR_SW_Controller2 "software version controller character 2";
CM_ SG_ 969 ZONE_FR_SW_Controller1 "software version controller character 1";
CM_ SG_ 969 ZONE_FR_SW_CarModel3 "software version car model character 3";
CM_ SG_ 969 ZONE_FR_SW_CarModel2 "software version car model character 2";
CM_ SG_ 969 ZONE_FR_SW_CarModel1 "software version car model character 1";
CM_ SG_ 969 ZONE_FR_HW_Ver3 "ZONE_FR hardware version character 3";
CM_ SG_ 969 ZONE_FR_HW_Ver2 "ZONE_FR hardware version character 2";
CM_ SG_ 969 ZONE_FR_HW_Ver1 "ZONE_FR hardware version character 1";
CM_ SG_ 969 ZONE_FR_SW_dash1 "software version dash character 1";
CM_ SG_ 969 ZONE_FR_SW_change1 "software version number of change 1";
CM_ SG_ 969 ZONE_FR_SW_change2 "software version number of change 2";
CM_ SG_ 969 ZONE_FR_SW_dash2 "software version dash character 2";
CM_ SG_ 969 ZONE_FR_SW_SHA1 "software version SHA character 1";
CM_ SG_ 969 ZONE_FR_SW_SHA2 "software version SHA character 2";
CM_ SG_ 969 ZONE_FR_SW_SHA3 "software version SHA character 3";
CM_ SG_ 969 ZONE_FR_SW_SHA4 "software version SHA character 4";
CM_ SG_ 969 ZONE_FR_SW_SHA5 "software version SHA character 5";
CM_ SG_ 969 ZONE_FR_SW_SHA6 "software version SHA character 6";
CM_ SG_ 969 ZONE_FR_SW_SHA7 "software version SHA character 7";
CM_ SG_ 969 ZONE_FR_SW_SHA8 "software version SHA character 8";
CM_ SG_ 969 ZONE_FR_SW_ECUGen2 "ECU generation 2";
CM_ SG_ 969 ZONE_FR_SW_ECUGen1 "ECU generation 1";
CM_ SG_ 969 ZONE_FR_SW_Var5 "software version car model variation 5";
CM_ SG_ 969 ZONE_FR_SW_Var4 "software version car model variation 4";
CM_ SG_ 969 ZONE_FR_SW_Var3 "software version car model variation 3";
CM_ SG_ 969 ZONE_FR_SW_Var2 "software version car model variation 2";
CM_ SG_ 427 EPB1_CS "Checksum of EPB1(AUTOSAR E2E profile 1)

Polynomial 0x1D (x^8+x^4+x^3+x^2+1) Both start value and XOR value are 0x00.";
CM_ SG_ 427 EPB1_RC "EPB1 4-bit rolling counter
It starts counting from 0, ends at 14 and returns to zero (0~14).";
CM_ SG_ 427 EPBSta "Electric Parking Brake Status";
CM_ SG_ 427 EPBMsg "EPB Message";
CM_ SG_ 427 EPBStaR "Electric Parking Brake Status Right";
CM_ SG_ 427 EPBErrSta "EPB Error Status";
CM_ SG_ 427 EPBRLampSta "EPB Red Lamp Status";
CM_ SG_ 427 EPBExtReleaseAvail "EPB External Release Availability";
CM_ SG_ 427 EPBExtApplyAvail "EPB External Control Availability";
CM_ SG_ 427 EPBCarWashMode "EPB Car Wash Mode";
CM_ SG_ 427 DOA_Sta "Door Open Apply Status";
CM_ SG_ 427 EPBStaL "Electric Parking Brake Status Left";
CM_ SG_ 427 TakeOverReq "Backup EPB Take Over Request";
CM_ SG_ 602 METER_KPH_Calcu "METER Calculated Speed(KPH)";
CM_ SG_ 602 METER_MPH_Calcu "METER Calculated Speed(MPH)";
CM_ SG_ 602 METER_KPH_Real "METER Real Speed(KPH)";
CM_ SG_ 602 METER_MPH_Real "METER Real Speed(MPH)";
CM_ SG_ 602 Averaged_vehspeed "Averaged_vehspeed";
CM_ SG_ 602 AVGPwrConsumption "average power consumption";
CM_ SG_ 602 AvailableTrip "Distance to Empty";
CM_ SG_ 602 Spd_Crl_Mode "Speed Control Function Mode";
CM_ SG_ 602 Spd_Crl_Sta "Speed Control Function Status";
CM_ SG_ 602 LEDlitWarnReq "LED lit Warning Request";
CM_ SG_ 602 Charge "Charge";
CM_ SG_ 602 ParkBrake "Park Brake";
CM_ SG_ 602 Trip_B "TripB";
CM_ SG_ 602 Trip_A "TripA";
CM_ SG_ 602 ODOMETER "Odometer";
CM_ SG_ 1168 VehACModReq "Vehicle Air Conition mode
0x2~0x5:Reserved
0x2~0x5:Reserved";
CM_ SG_ 1168 FCP_FrEvt_BtnACMaxReq "AC Max Button Press max cooling";
CM_ SG_ 1168 FCP_FrEvt_BtnACReq "AC Max Button Press max cooling";
CM_ SG_ 1168 FCP_FrEvt_BtnAutoReq "Front Auto Button Press";
CM_ SG_ 1168 FCP_MidEvt_BtnAutoReq "Middle Auto Button Press";
CM_ SG_ 1168 FCP_FrEvt_BtnSyncReq "Sync Button Press";
CM_ SG_ 1168 OTA_DL_Req "OTA Download Request";
CM_ SG_ 1168 OTA_SuspendDL_Req "OTA Suspend Download Request";
CM_ SG_ 1168 OTA_UpdStart_Req "OTA Update Start Request";
CM_ SG_ 1168 IVI_OTA_Upd_Sta "IVI OTA Update Status";
CM_ SG_ 1168 OTA_CancelDL_Req "OTA Cancel Download Request";
CM_ SG_ 1168 SmartEco_Mode_SW "Smart ECO Mode Switch";
CM_ SG_ 1168 LINKtoDrive "LINK to Drive";
CM_ SG_ 1168 Upd_Countdown_Skip "Update Countdown Skip";
CM_ SG_ 1168 Upd_Countdown_Cancel "Update Countdown Cancel";
CM_ SG_ 1168 AmbLightColorSet "AmbLight Color Set";
CM_ SG_ 1168 Sched_OTA_wake "Scheduled OTA wake up";
CM_ SG_ 1168 UserSet "UserSet";
CM_ SG_ 1168 AmbLightBrightnessSet "Ambient Light Brightness Set";
CM_ SG_ 1168 Sched_Chg_Day_Set "Scheduled Charging Daily setting";
CM_ SG_ 1168 Re_Radio_Sta "Re-active Radio Status";
CM_ SG_ 1168 Sched_Chg_St_Time_Min "Scheduled Charging Start Time Minute Setting";
CM_ SG_ 1168 A2B_Node_sta "A2B node status";
CM_ SG_ 1168 Sched_Chg_St_Time_HR "Scheduled Charging Start Time Hour Setting";
CM_ SG_ 1168 IVI_Located_STA "IVI_GPS Satellite Located status";
CM_ SG_ 1168 Sched_Chg_End_Time_Min "Scheduled Charging End Time Minute Setting";
CM_ SG_ 1168 OTA_CompNTFY_Pres "OTA Complete notify presented";
CM_ SG_ 1168 BrkAbn_GoReady_SW "Brake Abnormal Go Ready";
CM_ SG_ 1168 Sched_Chg_End_Time_HR "Scheduled Charging End Time Hour Setting";
CM_ SG_ 1168 IVI_Time_Check "IVI_GPS Satellite Time_Check Sum";
CM_ SG_ 1168 PW_CONTINUE_USE "Power Continue Use";
CM_ SG_ 1168 PW_CLOSE_IMD "Power Close Immediately";
CM_ SG_ 1168 IVI_Time_Second "IVI_GPS Satellite Time_Second";
CM_ SG_ 1168 IVI_Time_Minute "IVI_GPS Satellite Time_Minute";
CM_ SG_ 1168 IVI_Time_Day "IVI_GPS Satellite Time_Day";
CM_ SG_ 1168 IVI_Time_Hour "IVI_GPS Satellite Time_Hour";
CM_ SG_ 1168 IVI_Time_Month "IVI_GPS Satellite Time_Month";
CM_ SG_ 1168 IVI_Time_Year "IVI_GPS Satellite Time_Year";
CM_ SG_ 1168 mFRD_link_Sta "Meter FRD Link status";
CM_ SG_ 1168 AmbLight_SW "AmbLight Switch";
CM_ SG_ 1168 AmbLight_DimInDark_SW "AmbLight Dimmed In Dark Switch";
CM_ SG_ 1168 AmbLight_WlcmLight_SW "AmbLight Welcome light Switch";
CM_ SG_ 1168 AmbLigh_LowBatAlert_SW "AmbLight Low battery alert Switch";
CM_ SG_ 1168 AmbLigh_SafetyAlert_SW "AmbLight Safety alert Switch";
CM_ SG_ 1168 OpenDrOpenWdo_SW "Open Door Link Open Window Switch";
CM_ SG_ 1168 IVI_LinkKey_Sta "Target key of link key function";
CM_ SG_ 1168 IVI_CreateAccReq_Sta "IVI Create account request";
CM_ SG_ 1168 IVI_DelAccReq_Sta "IVI Delete account request";
CM_ SG_ 1168 IVI_LinkAcc_Sta "Target user of link key function (0x6 is default user, is not linkable)";
CM_ SG_ 1168 IVI_LinkAccReq_Sta "IVI link target key to target user request";
CM_ SG_ 1168 IVI_FrTrunk_UnlockReq_Sta "IVI Front Trunk Unlock Request";
CM_ SG_ 1168 IVI_CLWin_LockDoorSW_Sta "Close window when lock door";
CM_ SG_ 1168 IVI_Lock_SoundSW_Sta "IVI_Lock_SoundSW_Sta";
CM_ SG_ 1168 IVI_SWC_VibMode_Sta "IVI Steering Wheel  Vibration Mode";
CM_ SG_ 1168 IVI_DMS_SW_Sta "IVI Driver Monitoring System Switch";
CM_ SG_ 1168 IVI_AirRefresh_ByDMS_Sta "IVI Air Refresh Detect by DMS switch";
CM_ SG_ 1168 IVI_QuickRefresh_Sta "IVI Quick Refresh Switch";
CM_ SG_ 1168 IVI_HMI_Undefined_Sta "IVI HMI Undefined button Mode ";
CM_ SG_ 1168 IVI_AutoTheme_But_Sta "IVI Auto Light/Dark Theme Button Status";
CM_ SG_ 1168 IVI_NAVI_Foreground_Sta "IVI Navigation Foreground Status";
CM_ SG_ 1168 IVI_sigScreenReq_Sta "IVI SCREEN BLOWER REQUEST ";
CM_ SG_ 1168 IVI_DSEAT_anti_set_Sta "Driver Seat Antitheft on/off request";
CM_ SG_ 1168 IVI_MirrorFolded_SW_Sta "IVI Outside Mirror Folded Switch";
CM_ SG_ 1168 IVI_WPTC_SW_Sta "IVI Water PTC Switch";
CM_ SG_ 1168 IVI_Driving_Lock_SW_Sta "Lock when driving switch";
CM_ SG_ 1168 IVI_Stopping_Unlock_SW_Sta "Unlock when stopping switch";
CM_ SG_ 1168 IVI_SilentChrg_Alert_Sta "IVI Silent Charge Alert Popup Status";
CM_ SG_ 1168 IVI_WirelessCharge_Cmd "IVI_WirelessCharge_Cmd";
CM_ SG_ 1168 IVI_Theme_Sta "IVI_Theme_Sta";
CM_ SG_ 1168 IVI_EPS_Force_Cmd "IVI_EPS_Force_Cmd";
CM_ SG_ 1168 IVI_DSEAT_StopKeepMove_Sta "IVI_DSEAT_StopKeepMove_Sta";
CM_ SG_ 1168 IVI_AutoWipHSpdSW_Cmd "IVI_AutoWipHSpdSW_Cmd";
CM_ SG_ 1168 IVI_DSEAT_entryfun_set_Sta "IVI_DSEAT_entryfun_set_Sta";
CM_ SG_ 1173 SOC_V2LLimit "SOC V2LLimitation";
CM_ SG_ 1173 Perd_V2L "V2L Period Setting";
CM_ SG_ 1173 IVI_Req_V2L "Driver trigs V2L function via IVI";
CM_ SG_ 1173 IVI_PTG_Open_Height "IVI 'PTG Open Height' Menu Status";
CM_ SG_ 1173 IVI_CreepSW_Req "IVI Creep On/Off Switch Request";
CM_ SG_ 1173 FalseNPrevent_SW "Prevent FALSE turn GEAR into N";
CM_ SG_ 1173 Approach_Unlock_SW "Unlock when approaching Switch";
CM_ SG_ 1173 Walkaway_Lock_SW "Lock when walking away";
CM_ SG_ 1173 Sched_Chg_limit "Scheduled Charging charging limit";
CM_ SG_ 1173 Sched_Chg_Stop "Scheduled Charging stop";
CM_ SG_ 1173 Sched_Chg_butt "Scheduled Charging Button";
CM_ SG_ 1173 Sched_Chg_wake "Scheduled Charging wake up";
CM_ SG_ 1173 Sched_Chg_Start "Scheduled Charging Start";
CM_ SG_ 1173 sigFaceReq "FACE BLOWER REQUEST";
CM_ SG_ 1173 sigFootReq "FOOT BLOWER REQUEST";
CM_ SG_ 1173 METER_Malfunc_Sta "Meter Malfunction Status";
CM_ SG_ 1173 IVI_Start_Chg_req "IVI Start Charging Request";
CM_ SG_ 1173 L_RRD_ControlCommand "Rear Right  window control command";
CM_ SG_ 1173 IVI_Stop_Chg_req "IVI Stop Charging Request";
CM_ SG_ 1173 L_RLD_ControlCommand "Rear Left window control command";
CM_ SG_ 1173 IVI_Unlock_Chg_req "IVI unlock Charging port Request";
CM_ SG_ 1173 L_Pas_ControlCommand "Passenger window control command";
CM_ SG_ 1173 TPMS_Cali_Butt "TPMS tire calibrate button";
CM_ SG_ 1173 L_Drv_ControlCommand "Driver window control command";
CM_ SG_ 1173 GPS_LONG "GPS Location_Longitude";
CM_ SG_ 1173 GPS_LAT "GPS Location_Latitude";
CM_ SG_ 1173 sigDfrstReq "Defrost request for the HVAC (ON / AUTO)";
CM_ SG_ 1173 sigHvacFrontReq "Request for operation for the front HVAC (ON / OFF)";
CM_ SG_ 1173 sigSetTempZon1Req "Temperature setpoint  for HVAC Zone 1";
CM_ SG_ 1173 sigHvacReq "Request for operation for the HVAC (ON / OFF)";
CM_ SG_ 1173 sigRecircReq "Recirculation request for the HVAC (ON / AUTO)";
CM_ SG_ 1173 sigSetTempZon2Req "Temperature setpoint  for HVAC Zone 2";
CM_ SG_ 1173 sigSetTempZon3Req "Temperature setpoint  for HVAC Zone 3";
CM_ SG_ 1173 AEB_BUTT "AEB  ON/OFF Buttom";
CM_ SG_ 1173 sigAirIntenZon1Req "Request to HVAC FAN Level/Air Intensirty: 0-Max or Auto for zone 1
0xb~0xE:Reserved
0xb~0xE:Reserved
0xb~0xE:Reserved";
CM_ SG_ 1173 sigAirIntenZon3Req "Request to HVAC FAN Level/Air Intensirty: 0-Max or Auto for zone 3
0xb~0xE:Reserved
0xb~0xE:Reserved
0xb~0xE:Reserved";
CM_ SG_ 1173 sigWindDirZon3Req "Request to HVAC Wind Direction Zone 3. 
Feed, Body and/or Auto";
CM_ SG_ 1173 BSDMute_BUTT "BSD Mute Buttom";
CM_ SG_ 1173 LDWMute_BUTT "LDW Mute Buttom";
CM_ SG_ 1173 ODAMute_BUTT "ODA Mute Buttom";
CM_ SG_ 1173 LKA_BUTT "LKA  ON/OFF Buttom";
CM_ SG_ 1173 FCWMute_BUTT "FCW Mute Buttom";
CM_ SG_ 1173 sigHvacRearReq "Request for operation for the rear HVAC (ON / OFF)";
CM_ SG_ 1173 IVI_Panel_Act "IVI Touch Panel Active";
CM_ SG_ 1173 ESC_SW_Cmd "ESC ON/OFF Buttom";
CM_ SG_ 1173 Distance_unit "Distance unit";
CM_ SG_ 1173 Temperature_unit "Temperature unit";
CM_ SG_ 1173 NAVI_Speed_Limit_A "NAVI Speed Limitation Applicable";
CM_ SG_ 1173 Time_system "Time system";
CM_ SG_ 1173 Pressure_unit "Pressure unit";
CM_ SG_ 1173 TurnSwTimeSet "turning switch flash time set";
CM_ SG_ 1173 IVI_Screen "IVI Screen
0x1d~0x3E:undefined";
CM_ SG_ 1173 NAVI_Direction_STA "NAVI Direction Status";
CM_ SG_ 1173 Wifi_Reset "Wifi Reset between VIG and OBU";
CM_ SG_ 1173 CameraWrn "Speed cameras Warming";
CM_ SG_ 1173 User_p_upload "User profile upload";
CM_ SG_ 1173 IVI_PW_Mode_Req "IVI Power Mode require";
CM_ SG_ 1173 OFF_AC_MODE "OFF AC MODE";
CM_ SG_ 1173 NAVI_Cam_Dist_info "Navigation speed camera distance information";
CM_ SG_ 1173 IVI_Panel_X_Coor "IVI Touch Panel X coordinate";
CM_ SG_ 1173 IVI_Panel_Y_Coor "IVI Touch Panel Y coordinate";
CM_ SG_ 1173 Wifi_Sta_IVI_TBOX "Wifi signal status between IVI and TBOX";
CM_ SG_ 1173 NAVI_State "Information for Navigation Status";
CM_ SG_ 1173 HeadLampSW "Head Lamp Switch";
CM_ SG_ 1173 User_p_download "User profile download";
CM_ SG_ 1173 MFRD_N_Bright_Req "MFRD night Brightness setting";
CM_ SG_ 1173 RFogLampSW "Rear Fog Lamp Switch";
CM_ SG_ 1173 DSEAT_vent_req "Driver Seat ventilate request";
CM_ SG_ 1173 FFogLampSW "Front Fog Lamp Switch";
CM_ SG_ 1173 PSEAT_vent_req "Passenger Seat Ventilate request
0= No Request,
1= Vent1,
2= Vent2,
3= Vent3,
4= Off";
CM_ SG_ 1173 FS_Off_Sw "F_USS Switch Status";
CM_ SG_ 1173 SLG_Sw "Smart liftgate Switch Status";
CM_ SG_ 1173 IVI_PTG_Sta_SW "Power Tail Gate Open and Close Switch";
CM_ SG_ 1173 IVI_PTG_Mode_SW "Power Tail Gate Manual and Automatic mode Switch";
CM_ SG_ 1173 SetUnlockSingle "Single Set Unlock DOOR SETTING";
CM_ SG_ 1173 FollowMeSW "Follow Me Home SW";
CM_ SG_ 1173 TPMS_Res_Butt "TPMS_Reset_button";
CM_ SG_ 1173 DSEAT_anti_set "Driver Seat Antitheft on/off request";
CM_ SG_ 1173 DSEAT_entryfun_set "Driver Seat Entry on/off request";
CM_ SG_ 1173 CAAS_Sw "Collision Avoidance Assistance System Switch Status";
CM_ SG_ 1173 LVDAMute_BUTT "LDW Mute Buttom";
CM_ SG_ 1173 IVI_Status "IVI Status";
CM_ SG_ 1173 IVI_Night_Mode_Sta "IVI Night Mode Status";
CM_ SG_ 1173 IVI_RR_Def_Req "IVI Rear Deffogger Status";
CM_ SG_ 1173 IVI_WI_MAIN_SW "IVI Wiper Maintance_Switch";
CM_ SG_ 1173 IVI_PTG_USSta_SW "Power Tail Gate Ultrasonic Switch";
CM_ SG_ 1173 IVI_Mute_Sta "IVI Mute status";
CM_ SG_ 1173 NAVI_Distance_info "NAVI Distance Information";
CM_ SG_ 1173 AVM_Err_STA "AVM Error Status";
CM_ SG_ 1173 IVI_Trigger_req "IVI Trigger VCU to Ready request";
CM_ SG_ 1173 IVI_Pwroff_req "IVI Power off request";
CM_ SG_ 1173 RCTA_BUTT "RCTA ON/OFF Button";
CM_ SG_ 1173 Hood_Latch_SW "Hood Latch Switch";
CM_ SG_ 1173 AVM_Parking_mode "AVM_Parking Mode";
CM_ SG_ 1173 SenstivityPosition "wiper Senstivity Position";
CM_ SG_ 1173 NAVI_ForwardLinkLevel "Information for Forward Link Level in Freeway (Change information shall be informed 500m ahead)";
CM_ SG_ 1173 NAVI_Tunnel "Information for Tunnel exist (Exist information shall be informed 500m ahead)";
CM_ SG_ 1173 NAVI_LinkClass "Information for Link Class Value of Segment";
CM_ SG_ 1173 NAVI_Tollgate "Information for Tollgate exist (Exist information shall be informed 500m ahead)";
CM_ SG_ 1173 NAVI_RoadClass "Information for Road Class";
CM_ SG_ 1173 NAVI_SpeedLimit "Information for Current Link Speed Limit expressed as km/h or mph";
CM_ SG_ 1173 RoomLampMode "Room lampt on/off connected with car door open/close";
CM_ SG_ 1173 IVI_ISA_OffsetSpd "IVI ISA Offset speed";
CM_ SG_ 1173 AC_Chg_Cur_Set "AC Charging Current Setting";
CM_ SG_ 1173 SOC_ADJ_BUTT "SOC Charging Limitation Adjust Button";
CM_ SG_ 1173 CDL_Unlock_Butt "Central Door Lock_UNLOCK_Button";
CM_ SG_ 1173 CDL_Lock_Butt "Central Door Lock_LOCK_Button";
CM_ SG_ 1173 SOC_Limit_Set "SOC Charging Limitation Setting";
CM_ SG_ 1173 Roll_Eng_Mode "Roll Engine Mode";
CM_ SG_ 1173 SLIF_BUTT "SLIF  ON/OFF Buttom";
CM_ SG_ 1173 TCS_SW_Cmd "TCS Switch command";
CM_ SG_ 1173 Roll_Mode_SW_Cmd "Roll Mode Switch command";
CM_ SG_ 1173 IVI_ActvDmpDisabSW "IVI Active Damping Disable Switch";
CM_ SG_ 1173 IVI_CoastDwSW "IVI Coastdown switch";
CM_ SG_ 1173 IVI_PwrLockSW "IVI Power State Lock Switch";
CM_ SG_ 1173 IVI_LVChrgFuncSW "IVI LV Charging function switch";
CM_ SG_ 1173 IVI_AGSCloseSW "IVI AGS close switch";
CM_ SG_ 1173 AVM_OFF_Rec_Butt "AVM KEYOFF Recording Button";
CM_ SG_ 1173 AVM_parking_excute "confirm and start to auto parking";
CM_ SG_ 1173 AVM_parking_cancel "auto parking cancel";
CM_ SG_ 1173 IVI_DSEATHeater_Cmd "IVI Driver seat heater request";
CM_ SG_ 1173 IVI_PSEATHeater_Cmd "IVI Passenger seat heater request";
CM_ SG_ 1173 WlcmLight_Mode "Welcome Light Mode";
CM_ SG_ 1173 IVI_CfmTo_Rdy "IVI Confirm to Ready";
CM_ SG_ 1173 Light_ShowStart_Req "Light Show Start Request";
CM_ SG_ 1173 Light_ShowStop_Req "Light Show Stop Request";
CM_ SG_ 1173 IVI_TrailerCheckReq_Sta "Trailer Check request";
CM_ SG_ 1173 IVI_TrailerModeSW_Sta "Trailer Mode Switch";
CM_ SG_ 1173 IVI_FGSAirInt_Cmd "IVI_FGSAirInt_Cmd";
CM_ SG_ 1173 IVI_FGSCh_Cmd "IVI_FGSCh_Cmd";
CM_ SG_ 1173 IVI_IONSW_Cmd "IVI_IONSW_Cmd";
CM_ SG_ 1173 IVI_SWC_ACCMode_Sta "IVI Steering Wheel ACC Mode";
CM_ SG_ 1173 IVI_SWC_LUndefined_Sta "IVI Steering Wheel Left Undefined button Mode";
CM_ SG_ 1173 IVI_SWC_RUndefined_Sta "IVI Steering Wheel Right Undefined button Mode ";
CM_ SG_ 1173 IVI_ACC_Adaptive_Sta "IVI ACC Adaptive Mode";
CM_ SG_ 1173 IVI_SLIF_Warning_Sta "IVI SLIF Warning Status";
CM_ SG_ 1173 IVI_SetTempZon1_Sta "IVI Temperature setpoint? for HVAC Zone 1 ";
CM_ SG_ 1173 IVI_SetTempZon2_Sta "IVI Temperature setpoint? for HVAC Zone 2";
CM_ SG_ 1173 IVI_AirIntZ3_Cmd "IVI AiR intetion Zone 3 Command";
CM_ SG_ 1173 IVI_DSEAT_Slide_Cmd "IVI Driver Seat Slide Adjustment";
CM_ SG_ 1173 IVI_DSEAT_Recline_Cmd "IVI Driver Seat Recline Adjustment";
CM_ SG_ 1173 IVI_DSEAT_Height_Cmd "IVI Driver Seat Height Adjustment";
CM_ SG_ 1173 IVI_DSEAT_FroEdge_Height_Cmd "IVI Driver Seat Front Edge Height Adjustment";
CM_ SG_ 1173 IVI_PSEAT_Slide_Cmd "IVI Passenger Seat Slide Adjustment";
CM_ SG_ 1173 IVI_PSEAT_Recline_Cmd "IVI Passenger Seat Recline Adjustment";
CM_ SG_ 1173 IVI_ChargePortSW_Sta "IVI Charge Port Switch";
CM_ SG_ 1173 IVI_DSEAT_Memory1_Sta "IVI Driver Seat Memory 1 Button";
CM_ SG_ 1173 IVI_DSEAT_Memory2_Sta "IVI Driver Seat Memory 2 Button";
CM_ SG_ 1173 IVI_DSEAT_Memory_OPTCLS_Sta "IVI Driver Seat Memory Options Closed ";
CM_ SG_ 1173 DMS_Status "DMS Status";
CM_ SG_ 1173 DMS_Warning_Distraction "DMS Warning Distraction";
CM_ SG_ 1173 DMS_Warning_Fatigue "DMS Warning Fatigue";
CM_ SG_ 1173 DMS_Warning_Unresponsive "DMS Warning Unresponsive";
CM_ SG_ 1173 IVI_FWipIntTSet_Cmd "IVI Front Wiper Interval Time Set";
CM_ SG_ 1173 IVI_CarWash_Mode_Cmd "IVI Car wash mode  Status";
CM_ SG_ 1173 IVI_Backlight_Sta "IVI_Backlight_Sta to Bridge IC";
CM_ SG_ 1173 IVI_GPS_Long_Dir_Sta "IVI_GPS_Long_Dir_Sta";
CM_ SG_ 1173 IVI_GPS_Lat_Dir_Sta "IVI_GPS_Lat_Dir_Sta";
CM_ SG_ 1173 IVI_IC_Brightness_Sta "sync brightness of the Instrument Cluster and Bridge IC";
CM_ SG_ 1173 IVI_Off_Road_Mode_Sta "Off Road Mode Switch";
CM_ SG_ 1173 IVI_DMS_NoDriverDetected_Sta "DMS Warning NoDriverDetected";
CM_ SG_ 1173 IVI_DMS_Faceblocked_Sta "DMS Warning Face blocked";
CM_ SG_ 1282 NM_Meter_Node_ID "Source Node Identifier";
CM_ SG_ 1282 NM_Meter_PNI "Partial Network Information Bit (PNI)";
CM_ SG_ 1282 NM_Meter_Active_WU "Active Wakeup Bit";
CM_ SG_ 1282 NM_Meter_CSB "NM Coordinator Sleep Bit";
CM_ SG_ 1282 NM_Meter_Rpt_Msg_Req "Repeat Message Request";
CM_ SG_ 1282 NM_Meter_ERROR_State "Defined Error states of the CAN Controller";
CM_ SG_ 1312 NM_IVI_Node_ID "Source Node Identifier";
CM_ SG_ 1312 NM_IVI_PNI "Partial Network Information Bit (PNI)";
CM_ SG_ 1312 NM_IVI_Active_WU "Active Wakeup Bit";
CM_ SG_ 1312 NM_IVI_CSB "NM Coordinator Sleep Bit";
CM_ SG_ 1312 NM_IVI_Rpt_Msg_Req "Repeat Message Request";
CM_ SG_ 1312 NM_IVI_ERROR_State "Defined Error states of the CAN Controller";
CM_ SG_ 1330 NM_HMI_Node_ID "Source Node Identifier";
CM_ SG_ 1330 NM_HMI_PNI "Partial Network Information Bit (PNI)";
CM_ SG_ 1330 NM_HMI_Active_WU "Active Wakeup Bit";
CM_ SG_ 1330 NM_HMI_CSB "NM Coordinator Sleep Bit";
CM_ SG_ 1330 NM_HMI_Rpt_Msg_Req "Repeat Message Request";
CM_ SG_ 1330 NM_HMI_ERROR_State "Defined Error states of the CAN Controller";
CM_ SG_ 1538 DiagRespFromMeter "Diagnostic Response from Meter";
CM_ SG_ 1568 DiagRespFromIVI "Diagnostic Response from IVI";
CM_ SG_ 1586 DiagRespFromHMI "Diagnostic Response from HMI";
CM_ SG_ 1184 Telltale_ABSWarning "Telltale  ABS Warning";
CM_ SG_ 1184 Telltale_BatteryChargeWarning "Telltale Battery Charge Warning";
CM_ SG_ 1184 Telltale_EDriveSystem "Telltale EDrive System";
CM_ SG_ 1184 Telltale_EPBError "Telltale EPB Error Status";
CM_ SG_ 1184 Telltale_HVBatteryFault "Telltale HV Battery Fault";
CM_ SG_ 1184 Telltale_ParkBrakeWarning "Telltale Park Brake Warning";
CM_ SG_ 1184 Telltale_Powerlimitation "Telltale Power limitation";
CM_ SG_ 1184 Telltale_SteeringWarning "Telltale Steering Warning";
CM_ SG_ 1184 Telltale_TCSIndicator "Telltale TCS Indicator";
CM_ SG_ 1184 Telltale_EBMErrSta "Telltale EBM Error Status";
CM_ SG_ 857 DSEAT_heater_sta "Driver seat heater status";
CM_ SG_ 857 DSEAT_Mode "Driver Seat Mode
0=manual, 1=power, 2=power & heater, 
3=power & ventilate, 
4=power & heater & ventilate, 
5=manual & heater, 
6=manual & ventilate, 
7=manual & heater & ventilate";
CM_ SG_ 857 DSEAT_Vent_Sta "Driver Seat Ventilate Staus";
CM_ SG_ 857 PSEAT_heater_sta "Passenger seat heater status";
CM_ SG_ 857 PSEAT_Mode "Passenger Seat Mode";
CM_ SG_ 857 PSEAT_Vent_Sta "Passenger Seat Ventilate Staus";
CM_ SG_ 857 DSEAT_Anti_Sta "Driver Seat Antitheft Status";
CM_ SG_ 857 DSEAT_EntryFun_Sta "Driver Seat Entry Function Status";
CM_ SG_ 857 DSEAT_Error_Sta "Driver Seat Error Status";
CM_ SG_ 857 PSEAT_Error_Sta "Passenger Seat Error Status";
CM_ SG_ 857 PTG_Active_Sta "PTG Function Activation State";
CM_ SG_ 857 PTG_Sys_Sta "PTG System Status";
CM_ SG_ 857 PTG_AutoStaus "Power Tail Gate Auto Status";
CM_ SG_ 857 PTG_Exist "PTG Existence";
CM_ SG_ 857 PTG_Is_Set_Height "PTG 'Set Open Height' Action Listener";
CM_ SG_ 857 Rr_TMSpd_Nidec "Rear TM speed from Nidec";
CM_ SG_ 857 Fr_TMSpd_Nidec "Front TM speed from Nidec";
CM_ SG_ 857 Fr_EDURealTMTq_Nidec "Front EDU Real Torque from TM from Nidec";
CM_ SG_ 857 Fr_MotorAvailTq_Nidec "Front Motor Torque Available from Nidec";
CM_ SG_ 857 Rr_EDURealTMTq_Nidec "Rear EDU Real Torque from TM from Nidec";
CM_ SG_ 857 Rr_MotorAvailTq_Nidec "Rear Motor Torque Available from Nidec";
CM_ SG_ 857 Fr_MCUTemp_Nidec "Front MCU Temperature from Nidec";
CM_ SG_ 857 Fr_TMTemp_Nidec "Front TM Temperature from Nidec";
CM_ SG_ 857 Rr_MCUTemp_Nidec "Rear MCU Temperature from Nidec";
CM_ SG_ 857 Rr_TMTemp_Nidec "Rear TM Temperature from Nidec";
CM_ SG_ 857 Fr_MCUTempWarn_Nidec "Front MCU Temperature Warning from Nidec";
CM_ SG_ 857 Fr_TMTempWarn_Nidec "Front TM Temperature Warning from Nidec";
CM_ SG_ 857 Rr_MCUTempWarn_Nidec "Rear MCU Temperature Warning from Nidec";
CM_ SG_ 857 Rr_TMTempWarn_Nidec "Rear TM Temperature Warning from Nidec";
CM_ SG_ 857 Fr_EDUDrtSta_Nidec "Front EDU Torque Derating Status from Nidec";
CM_ SG_ 857 Rr_EDUDrtSta_Nidec "Rear EDU Torque Derating Status from Nidec";
CM_ SG_ 857 L_Drv_Val_Wdw_Opened "Window Opened Value";
CM_ SG_ 857 L_Pas_Val_Wdw_Opened "Window Opened Value";
CM_ SG_ 857 L_RLD_Val_Wdw_Opened "Window Opened Value";
CM_ SG_ 857 L_RRD_Val_Wdw_Opened "Window Opened Value";
CM_ SG_ 857 FAPWL_01_LIN_Response_Error "LIN Communication ERROR";
CM_ SG_ 857 L_Drv_Motor_Relay_Error "Motor relay Error";
CM_ SG_ 857 L_Drv_Motor_Ripple_Error "Motor ripple Error";
CM_ SG_ 857 L_Pas_Motor_Relay_Error "Motor relay Error";
CM_ SG_ 857 L_Pas_Motor_Ripple_Error "Motor ripple Error";
CM_ SG_ 857 L_RLD_Motor_Relay_Error "Motor relay Error";
CM_ SG_ 857 L_RLD_Motor_Ripple_Error "Motor ripple Error";
CM_ SG_ 857 L_RRD_Motor_Relay_Error "Motor relay Error";
CM_ SG_ 857 L_RRD_Motor_Ripple_Error "Motor ripple Error";
CM_ SG_ 857 RAPWL_01_LIN_Response_Error "LIN Communication ERROR";
CM_ SG_ 855 Rr_TMSpd "Rear TM speed";
CM_ SG_ 855 Fr_TMSpd "Front TM speed";
CM_ SG_ 855 Fr_EDURealTMTq "Front EDU Real Torque from TM";
CM_ SG_ 855 Fr_MotorAvailTq "Front Motor Torque Available";
CM_ SG_ 855 Rr_EDURealTMTq "Rear EDU Real Torque from TM";
CM_ SG_ 855 Rr_MotorAvailTq "Rear Motor Torque Available";
CM_ SG_ 855 Fr_MCUTemp "Front MCU Temperature";
CM_ SG_ 855 Fr_TMTemp "Front TM Temperature";
CM_ SG_ 855 Rr_MCUTemp "Rear MCU Temperature";
CM_ SG_ 855 Rr_TMTemp "Rear TM Temperature";
CM_ SG_ 855 BD_DSEAT_Mode_Sta "BodyZone_DR SEAT Driver Seat Mode";
CM_ SG_ 855 BD_DSEAT_Vent_Sta "BodyZone_DR SEAT Driver Seat Ventilate Staus";
CM_ SG_ 855 BP_PTG_Active_Sta "BodyZone_PS PTG Function Activation State";
CM_ SG_ 855 BP_PSEAT_Mode_Sta "BodyZone_PS SEAT Passenger Seat Mode";
CM_ SG_ 855 BP_PSEAT_Vent_Sta "BodyZone_PS SEAT Passenger Seat Ventilate Staus";
CM_ SG_ 855 Fr_MCUTempWarn "Front MCU Temperature Warning";
CM_ SG_ 855 Fr_TMTempWarn "Front TM Temperature Warning";
CM_ SG_ 855 Rr_MCUTempWarn "Rear MCU Temperature Warning";
CM_ SG_ 855 Rr_TMTempWarn "Rear TM Temperature Warning";
CM_ SG_ 855 BP_PTG_Sys_Sta "BodyZone_PS PTG System Status";
CM_ SG_ 855 Fr_EDUDrtSta "Front EDU Torque Derating Status";
CM_ SG_ 855 Rr_EDUDrtSta "Rear EDU Torque Derating Status";
CM_ SG_ 855 BD_DSEAT_Anti_Sta "BodyZone_DR SEAT Driver Seat Antitheft Status";
CM_ SG_ 855 BD_DSEAT_EntryFun_Sta "BodyZone_DR SEAT Driver Seat Entry Function Status";
CM_ SG_ 855 BD_DSEAT_Error_Sta "BodyZone_DR SEAT Driver Seat Error Status";
CM_ SG_ 855 BP_PTG_Exist_Sta "BodyZone_PS PTG Existence";
CM_ SG_ 855 BP_PTG_IsSetHeight_Sta "BodyZone_PS PTG 'Set Open Height' Action Listener";
CM_ SG_ 855 BP_PSEAT_Error_Sta "BodyZone_PS SEAT Passenger Seat Error Status";
CM_ SG_ 855 BD_DSEAT_heater_Sta "BodyZone_DR SEAT Driver seat heater status";
CM_ SG_ 855 BP_PSEAT_heater_Sta "BodyZone_PS SEAT Passenger seat heater status";
CM_ SG_ 855 MCU_B_R_LLCTempWarn_Sta "Rear LLC temperature Warning";
CM_ SG_ 855 MCU_B_F_LLCTempWarn_Sta "Front LLC temperature Warning";
CM_ SG_ 855 SWC2_L_DriveMode_Sta "L Drive Mode Status SWC gen2";
CM_ SG_ 855 SWC2_L_Home_Sta "L Home Status SWC gen2";
CM_ SG_ 855 SWC2_R_Customize_Sta "R Customize Status SWC gen2";
CM_ SG_ 855 SWC2_R_Left_Sta "R Left Status SWC gen2";
CM_ SG_ 855 SWC2_R_PageSwitch_Sta "R PageSwitch Status SWC gen2";
CM_ SG_ 855 SWC2_R_Right_Sta "R Right Status SWC gen2";
CM_ SG_ 855 SWC2_R_ScrollDown_Sta "R Scroll Down Status SWC gen2";
CM_ SG_ 855 SWC2_R_ScrollPress_Sta "R Scroll Press Status SWC gen2";
CM_ SG_ 855 SWC2_R_ScrollUp_Sta "R Scroll Up Status SWC gen2";
CM_ SG_ 855 SWC2_R_VR_Sta "R VR Status SWC gen2";
CM_ SG_ 855 BP_SEAT_MLVent_Sta "BodyZone_PS SEAT ML Fan Status to IVI";
CM_ SG_ 855 BP_SEAT_MRVent_Sta "BodyZone_PS SEAT MR Fan Status to IVI";
CM_ SG_ 855 BP_SEAT_LVent_Sta "BodyZone_PS SEAT L Fan Status to IVI";
CM_ SG_ 855 BP_SEAT_RVent_Sta "BodyZone_PS SEAT R Fan Status to IVI";
CM_ SG_ 855 BD_DSEAT_MemSet_Sta "BodyZone_DR Driver Seat Memory seat Status";
CM_ SG_ 855 BD_DSEAT_StopKeepMove_Sta "BD_DSEAT_StopKeepMove_Sta";
CM_ SG_ 855 FDC_BCM_WinLFOpened_Sta "FDC_BCM Driver window opening";
CM_ SG_ 855 FDC_BCM_WinLROpened_Sta "FDC_BCM APM Left rear window opening";
CM_ SG_ 855 FDC_BCM_WinRFOpened_Sta "FDC_BCM APM Passenger window opening";
CM_ SG_ 855 FDC_BCM_WinRROpened_Sta "FDC_BCM APM Right rear window opening";
CM_ SG_ 855 BD_Door_FHandleClose_Sta "Bodyzone_DR Driver side Front Door Handle Close Status";
CM_ SG_ 855 BD_Door_RHandleClose_Sta "Bodyzone_DR Driver side Rear Door Handle Close Status";
CM_ SG_ 855 BP_Door_FHandleClose_Sta "Bodyzone_PS Passenger side Front Door Handle Close Status";
CM_ SG_ 855 BP_Door_RHandleClose_Sta "Bodyzone_PS Passenger side Rear Door Handle Close Status";
CM_ SG_ 552 AGS_Actual_Position "Position feedback from the actuator";
CM_ SG_ 552 AGS_Low_Voltage_Error "Feedback for over/under voltage error";
CM_ SG_ 552 AGS_Temperature_Error "Feedback for overtemprature error";
CM_ SG_ 552 AGS_Sensor_Error "Feedback of Shutter position sensor fault";
CM_ SG_ 552 AGS_Electrical_Error "Feedback of electrical error";
CM_ SG_ 552 AGS_Calibration_Indicated "Feedback of Shutter calibration indicated";
CM_ SG_ 552 AGS_Calibration_Active "Feedback of  Shutter calibration active";
CM_ SG_ 552 AGS_Actuator_Fault "Feedback of Shutter actuator fault";
CM_ SG_ 552 AGS_Actuator_Blocked "Feedback of Shutter blocked";
CM_ SG_ 552 AGS_LINResponse_Error "Feedback of Response error bit";
CM_ SG_ 552 ION_IONErr_Sta "ION_IONErr_Sta";
CM_ SG_ 552 ION_IONRespErr_Sta "ION_IONRespErr_Sta";
CM_ SG_ 552 ION_ION_Sta "ION_ION_Sta";
CM_ SG_ 552 FGS_LifeHole3_Sta "Channel 3 air fragrance  available time.";
CM_ SG_ 552 FGS_LifeHole2_Sta "Channel 2 air fragrance  available time.";
CM_ SG_ 552 FGS_LifeHole1_Sta "Channel 1 air fragrance  available time.";
CM_ SG_ 552 FGS_Channel3TypeRsp_Sta "The signal indicates the type of channel 3";
CM_ SG_ 552 FGS_Channel2TypeRsp_Sta "The signal indicates the type of channel 2";
CM_ SG_ 552 FGS_Channel1TypeRsp_Sta "The signal indicates the type of channel 1";
CM_ SG_ 552 FGS_BlowerErr_Sta "This signal indicates Blower failure";
CM_ SG_ 552 FGS_IntenRsp_Sta "The signal indicates the wind content level of FGS";
CM_ SG_ 552 FGS_MotorErr_Sta "This signal indicates Motor failure";
CM_ SG_ 552 FGS_TypRsp_Sta "The signal indicates the channel of FG";
CM_ SG_ 552 FGS_LINResponseErr_Sta "This signal indicates if FG is in LIN error status or not.
If theLIN slave detects the response error,LIN Error signal should be set";
CM_ SG_ 552 FGS_StsRsp_Sta "The signal indicate FG working status";
CM_ SG_ 552 FGS_Channel_Type_Sta "The signal indicates the type of channel";
CM_ SG_ 552 FGS_Channel_Index_Sta "The signal indicates the index channel of FGS";
CM_ SG_ 1169 HMI_ACBtn_Cmd "AC Button Command";
CM_ SG_ 1169 HMI_ACAutoBtn_Cmd "AC Auto Button Command";
CM_ SG_ 1169 HMI_ACRecycleBtn_Cmd "AC cycle Button Command";
CM_ SG_ 1169 HMI_ACFrDefogBtn_Cmd "AC Front defog Button Command";
CM_ SG_ 1169 HMI_ZLSetTP_Cmd "ZL(Left) Temp Button Increase Command";
CM_ SG_ 1169 HMI_ZLSetTM_Cmd "ZL(Left) Temp Button decrease Command";
CM_ SG_ 1169 HMI_ZRSetTP_Cmd "ZR(Right) Temp Button Increase Command";
CM_ SG_ 1169 HMI_ZRSetTM_Cmd "ZR(Right) Temp Button Decrease Command";
CM_ SG_ 1169 HMI_ACWindDirP_Cmd "AC Wind Direction Button Increase Command";
CM_ SG_ 1169 HMI_ACWindDirM_Cmd "AC Wind Direction Button Decrease Command";
CM_ SG_ 1169 HMI_ACAirIntP_Cmd "AC Air volume Button Increase Command";
CM_ SG_ 1169 HMI_ACAirIntM_Cmd "AC Air volume Button Decrease Command";
CM_ SG_ 1169 HMI_BCMPostDefogBtn_Cmd "BCM Post defog Button Command";
CM_ SG_ 1169 HMI_AutoInterLight_Cmd "Automatic interior lights Button Command";
CM_ SG_ 1169 HMI_PSEAT_LevelDown_Cmd "Passenger Seat Level Down Cmd";
CM_ SG_ 1169 HMI_PSEAT_LevelUp_Cmd "Passenger Seat Level Up Cmd";
CM_ SG_ 1169 HMI_DSEAT_LevelDown_Cmd "Driver Seat Level Down Cmd";
CM_ SG_ 1169 HMI_DSEAT_LevelUp_Cmd "Driver Seat Level Up Cmd";
CM_ SG_ 1169 HMI_Function6_LevelDown_Cmd "HMI Function 6 Button Decrease Command";
CM_ SG_ 1169 HMI_Function5_LevelDown_Cmd "HMI Function 5 Button Decrease Command";
CM_ SG_ 1169 HMI_Function4_LevelDown_Cmd "HMI Function 4 Button Decrease Command";
CM_ SG_ 1169 HMI_Function3_LevelDown_Cmd "HMI Function 3 Button Decrease Command";
CM_ SG_ 1169 HMI_Function2_LevelDown_Cmd "HMI Function 2 Button Decrease Command";
CM_ SG_ 1169 HMI_Function1_LevelDown_Cmd "HMI Function 1 Button Decrease Command";
CM_ SG_ 1169 HMI_Function6_LevelUp_Cmd "HMI Function 6 Button Increase Command";
CM_ SG_ 1169 HMI_Function5_LevelUp_Cmd "HMI Function 5 Button Increase Command";
CM_ SG_ 1169 HMI_Function4_LevelUp_Cmd "HMI Function 4 Button Increase Command";
CM_ SG_ 1169 HMI_Function3_LevelUp_Cmd "HMI Function 3 Button Increase Command";
CM_ SG_ 1169 HMI_Function2_LevelUp_Cmd "HMI Function 2 Button Increase Command";
CM_ SG_ 1169 HMI_Function1_LevelUp_Cmd "HMI Function 1 Button Increase Command";
CM_ SG_ 1175 IVI_CLBlower_Y_Sta "IVI Center Left Blower Y axis Status";
CM_ SG_ 1175 IVI_CLBlower_Z_Sta "IVI Center Left Blower Z axis Status";
CM_ SG_ 1175 IVI_CRBlower_Y_Sta "IVI Center Right Blower Y axis Status";
CM_ SG_ 1175 IVI_CRBlower_Z_Sta "IVI Center Right Blower Z axis Status";
CM_ SG_ 1175 IVI_LBlower_Y_Sta "IVI Left Blower Y axis Status";
CM_ SG_ 1175 IVI_LBlower_Z_Sta "IVI Left Blower Z axis Status";
CM_ SG_ 1175 IVI_RBlower_Y_Sta "IVI Right Blower Y axis Status";
CM_ SG_ 1175 IVI_RBlower_Z_Sta "IVI Right Blower Z axis Status";
CM_ SG_ 1175 IVI_LSEATvent_Cmd "IVI FL SEAT Vent command";
CM_ SG_ 1175 IVI_MLSEATvent_Cmd "IVI ML SEAT Vent command";
CM_ SG_ 1175 IVI_MRSEATvent_Cmd "IVI MR SEAT Vent command";
CM_ SG_ 1175 IVI_RSEATvent_Cmd "IVI FR SEAT Vent command";
CM_ SG_ 1175 IVI_LBlower_Mode_Sta "IVI Left Blower Mode Switch";
CM_ SG_ 1175 IVI_MLFootLift_Cmd "IVI ML Foot Lift command";
CM_ SG_ 1175 IVI_MLRecliner_Cmd "IVI ML SEAT Recliner command";
CM_ SG_ 1175 IVI_MLSeatLift_Cmd "IVI ML SEAT Lift command";
CM_ SG_ 1175 IVI_MLSlider_Cmd "IVI ML SEAT Slider command";
CM_ SG_ 1175 IVI_MRFootLift_Cmd "IVI MR Foot Lift command";
CM_ SG_ 1175 IVI_MRRecliner_Cmd "IVI MR SEAT Recliner command";
CM_ SG_ 1175 IVI_MRSeatLift_Cmd "IVI MR SEAT Lift command";
CM_ SG_ 1175 IVI_MRSlider_Cmd "IVI MR SEAT Slider command";
CM_ SG_ 1175 IVI_RBlower_Mode_Sta "IVI Right Blower Mode Switch";
CM_ SG_ 1175 IVI_MLFMost_Cmd "IVI ML SEAT Forward to Most command";
CM_ SG_ 1175 IVI_MLNapMode_Cmd "IVI ML SEAT Nap Mode command";
CM_ SG_ 1175 IVI_MLRestore_Cmd "IVI ML SEAT Restore command";
CM_ SG_ 1175 IVI_MLSldRestore_Cmd "IVI ML SEAT Slider Restore command";
CM_ SG_ 1175 IVI_MLZeroGravity_Cmd "IVI ML Zero Gravity command";
CM_ SG_ 1175 IVI_MRFMost_Cmd "IVI MR SEAT Forward to Most command";
CM_ SG_ 1175 IVI_MRNapMode_Cmd "IVI MR SEAT Nap Mode command";
CM_ SG_ 1175 IVI_MRRestore_Cmd "IVI MR SEAT Restore command";
CM_ SG_ 1175 IVI_MRSldRestore_Cmd "IVI MR SEAT Slider Restore command";
CM_ SG_ 1175 IVI_MRZeroGravity_Cmd "IVI MR Zero Gravity command";
CM_ SG_ 1175 IVI_HMI_CustmiKEY_Sta "IVI_HMI_CustmiKEY_Sta";
CM_ SG_ 1175 IVI_HMI_CustmiFun_Sta "IVI_HMI_CustmiFun_Sta";
CM_ SG_ 1175 IVI_SOS_Call_Sta "IVI_SOS_Call_Sta";
CM_ SG_ 1175 IVI_XWDMode_Cmd "Driving Wheel Mode Switch";
CM_ SG_ 1175 IVI_RollMod_atCarWash_Sta "IVI_RollMod_atCarWash_Sta";
CM_ SG_ 1175 IVI_SnowMode_Cmd "Snow  Mode Switch";
CM_ SG_ 1175 IVI_UserTakeOver_APS_Sta "IVI_UserTakeOver_APS_Sta";
CM_ SG_ 1175 IVI_Zon1WindDirSWReq_Sta "IVI_Zon1WindDirSWReq_Sta";
CM_ SG_ 1175 IVI_PSDManualPower_Sta "IVI_PSDManualPower_Sta";
CM_ SG_ 1175 IVI_RightPSDOpenClose_Cmd "IVI_RightPSDOpenClose_Cmd";
CM_ SG_ 1175 IVI_LeftPSDOpenClose_Cmd "IVI_LeftPSDOpenClose_Cmd";
CM_ SG_ 1687 DiagPhysReqToWCM "Diagnostic Physical Request to WCM";
CM_ SG_ 1559 DiagRespFromWCM "Diagnostic Response from WCM";
CM_ SG_ 2015 DiagFuncReqOBD "Diagnostic Functional Request from OBD Tester";
BA_DEF_ BO_ "GenMsgSendType" ENUM "Cycle","NoMsgSendType","IfActive","Event","CA","CE";
BA_DEF_ BO_ "GenMsgNrOfRepetition" INT 0 0;
BA_DEF_ BO_ "GenMsgILSupport" ENUM "No","Yes";
BA_DEF_ BO_ "GenMsgCycleTime" INT 0 0;
BA_DEF_ BO_ "DiagResponse" ENUM "No","Yes";
BA_DEF_ BO_ "DiagRequest" ENUM "No","Yes";
BA_DEF_ BO_ "NmMessage" ENUM "No","Yes";
BA_DEF_ BO_ "VFrameFormat" ENUM "StandardCAN","ExtendedCAN","reserved","reserved","reserved","reserved","reserved","reserved","reserved","reserved","reserved","reserved","reserved","reserved","StandardCAN_FD","ExtendedCAN_FD";
BA_DEF_ BO_ "DataID" STRING ;
BA_DEF_ BO_ "DoIPLogicalAddress" STRING ;
BA_DEF_ BO_ "CANFD_BRS" ENUM "0","1";
BA_DEF_ BO_ "GenMsgRequestable" INT 0 1;
BA_DEF_ SG_ "GenSigInvalidValue" HEX 0 0;
BA_DEF_ SG_ "GenSigStartValue" HEX 0 0;
BA_DEF_ SG_ "GenSigInactiveValue" HEX 0 0;
BA_DEF_ SG_ "GenSigRoutingTimeoutValue_String" STRING ;
BA_DEF_ SG_ "DataCenterDataType" STRING ;
BA_DEF_ SG_ "GenSigRoutingTimeoutValue" HEX 0 0;
BA_DEF_ SG_ "GenSigSendType" ENUM "Cycle","OnWrite","OnWriteWithRepetition","OnChange","OnChangeWithRepetition","IfActive","IfActiveWithRepetition","NoSigSendType","vector_leerstring";
BA_DEF_ SG_ "SigType" ENUM "Default","Range","RangeSigned","ASCII","Discrete","Control","ReferencePGN","DTC","StringDelimiter","StringLength","StringLengthControl","MessageCounter","MessageChecksum";
BA_DEF_ SG_ "GenSigILSupport" ENUM "No","Yes";
BA_DEF_DEF_ "GenMsgSendType" "Cycle";
BA_DEF_DEF_ "GenMsgNrOfRepetition" 0;
BA_DEF_DEF_ "GenMsgILSupport" "Yes";
BA_DEF_DEF_ "GenMsgCycleTime" 100;
BA_DEF_DEF_ "DiagResponse" "No";
BA_DEF_DEF_ "DiagRequest" "No";
BA_DEF_DEF_ "NmMessage" "No";
BA_DEF_DEF_ "VFrameFormat" "StandardCAN";
BA_DEF_DEF_ "DataID" "";
BA_DEF_DEF_ "DoIPLogicalAddress" "";
BA_DEF_DEF_ "CANFD_BRS" "1";
BA_DEF_DEF_ "GenMsgRequestable" 1;
BA_DEF_DEF_ "GenSigInvalidValue" 0;
BA_DEF_DEF_ "GenSigStartValue" 0;
BA_DEF_DEF_ "GenSigInactiveValue" 0;
BA_DEF_DEF_ "GenSigRoutingTimeoutValue_String" "";
BA_DEF_DEF_ "DataCenterDataType" "";
BA_DEF_DEF_ "GenSigRoutingTimeoutValue" 0;
BA_DEF_DEF_ "GenSigSendType" "Cycle";
BA_DEF_DEF_ "SigType" "Default";
BA_DEF_DEF_ "GenSigILSupport" "Yes";
BA_ "GenMsgCycleTime" BO_ 969 5000;
BA_ "VFrameFormat" BO_ 969 14;
BA_ "GenMsgCycleTime" BO_ 427 40;
BA_ "DataID" BO_ 427 "0x7A2B";
BA_ "VFrameFormat" BO_ 427 14;
BA_ "GenMsgNrOfRepetition" BO_ 602 1;
BA_ "GenMsgSendType" BO_ 602 5;
BA_ "VFrameFormat" BO_ 602 14;
BA_ "GenMsgNrOfRepetition" BO_ 1168 1;
BA_ "GenMsgCycleTime" BO_ 1168 500;
BA_ "GenMsgSendType" BO_ 1168 5;
BA_ "VFrameFormat" BO_ 1168 14;
BA_ "GenMsgNrOfRepetition" BO_ 1173 1;
BA_ "GenMsgCycleTime" BO_ 1173 200;
BA_ "GenMsgSendType" BO_ 1173 5;
BA_ "VFrameFormat" BO_ 1173 14;
BA_ "GenMsgCycleTime" BO_ 1282 0;
BA_ "NmMessage" BO_ 1282 1;
BA_ "GenMsgSendType" BO_ 1282 3;
BA_ "GenMsgCycleTime" BO_ 1312 0;
BA_ "NmMessage" BO_ 1312 1;
BA_ "GenMsgSendType" BO_ 1312 3;
BA_ "GenMsgCycleTime" BO_ 1330 0;
BA_ "NmMessage" BO_ 1330 1;
BA_ "GenMsgSendType" BO_ 1330 3;
BA_ "GenMsgCycleTime" BO_ 1538 0;
BA_ "DiagResponse" BO_ 1538 1;
BA_ "GenMsgSendType" BO_ 1538 3;
BA_ "VFrameFormat" BO_ 1538 14;
BA_ "DoIPLogicalAddress" BO_ 1538 "0x0682";
BA_ "GenMsgCycleTime" BO_ 1568 0;
BA_ "DiagResponse" BO_ 1568 1;
BA_ "GenMsgSendType" BO_ 1568 3;
BA_ "VFrameFormat" BO_ 1568 14;
BA_ "DoIPLogicalAddress" BO_ 1568 "0x06A0";
BA_ "GenMsgCycleTime" BO_ 1586 0;
BA_ "DiagResponse" BO_ 1586 1;
BA_ "GenMsgSendType" BO_ 1586 3;
BA_ "VFrameFormat" BO_ 1586 14;
BA_ "DoIPLogicalAddress" BO_ 1586 "0x06B2";
BA_ "GenMsgNrOfRepetition" BO_ 1184 1;
BA_ "GenMsgCycleTime" BO_ 1184 200;
BA_ "GenMsgSendType" BO_ 1184 5;
BA_ "VFrameFormat" BO_ 1184 14;
BA_ "GenMsgNrOfRepetition" BO_ 857 1;
BA_ "GenMsgSendType" BO_ 857 5;
BA_ "VFrameFormat" BO_ 857 14;
BA_ "GenMsgNrOfRepetition" BO_ 855 1;
BA_ "GenMsgSendType" BO_ 855 5;
BA_ "VFrameFormat" BO_ 855 14;
BA_ "VFrameFormat" BO_ 552 14;
BA_ "GenMsgNrOfRepetition" BO_ 1169 1;
BA_ "GenMsgCycleTime" BO_ 1169 200;
BA_ "GenMsgSendType" BO_ 1169 5;
BA_ "VFrameFormat" BO_ 1169 14;
BA_ "GenMsgNrOfRepetition" BO_ 1175 1;
BA_ "GenMsgCycleTime" BO_ 1175 500;
BA_ "GenMsgSendType" BO_ 1175 5;
BA_ "VFrameFormat" BO_ 1175 14;
BA_ "GenMsgCycleTime" BO_ 1687 0;
BA_ "DiagRequest" BO_ 1687 1;
BA_ "GenMsgSendType" BO_ 1687 3;
BA_ "VFrameFormat" BO_ 1687 14;
BA_ "DoIPLogicalAddress" BO_ 1687 "0x0697";
BA_ "GenMsgCycleTime" BO_ 1559 0;
BA_ "DiagResponse" BO_ 1559 1;
BA_ "GenMsgSendType" BO_ 1559 3;
BA_ "VFrameFormat" BO_ 1559 14;
BA_ "DoIPLogicalAddress" BO_ 1559 "0x0697";
BA_ "GenMsgCycleTime" BO_ 2015 0;
BA_ "DiagRequest" BO_ 2015 1;
BA_ "GenMsgSendType" BO_ 2015 3;
BA_ "VFrameFormat" BO_ 2015 14;
BA_ "DoIPLogicalAddress" BO_ 2015 "0xE000 ";
BA_ "GenSigInvalidValue" SG_ 427 EPBStaR 7;
BA_ "DataCenterDataType" SG_ 427 EPBErrSta "Varchar(20)";
BA_ "GenSigInvalidValue" SG_ 427 EPBStaL 7;
BA_ "GenSigInvalidValue" SG_ 602 METER_KPH_Calcu 255;
BA_ "GenSigRoutingTimeoutValue_String" SG_ 602 METER_KPH_Calcu "0xFF";
BA_ "GenSigRoutingTimeoutValue" SG_ 602 METER_KPH_Calcu 255;
BA_ "GenSigInvalidValue" SG_ 602 METER_MPH_Calcu 255;
BA_ "GenSigRoutingTimeoutValue_String" SG_ 602 METER_MPH_Calcu "0xFF";
BA_ "GenSigRoutingTimeoutValue" SG_ 602 METER_MPH_Calcu 255;
BA_ "GenSigInvalidValue" SG_ 602 METER_KPH_Real 4095;
BA_ "GenSigInvalidValue" SG_ 602 METER_MPH_Real 4095;
BA_ "GenSigInvalidValue" SG_ 602 Averaged_vehspeed 1023;
BA_ "GenSigInvalidValue" SG_ 602 AVGPwrConsumption 65535;
BA_ "GenSigStartValue" SG_ 602 AVGPwrConsumption 9999;
BA_ "GenSigInvalidValue" SG_ 602 APCforDTE 65535;
BA_ "GenSigStartValue" SG_ 602 APCforDTE 9999;
BA_ "GenSigInvalidValue" SG_ 602 AvailableTrip 65535;
BA_ "GenSigInvalidValue" SG_ 602 Spd_Crl_Mode 5;
BA_ "GenSigRoutingTimeoutValue_String" SG_ 602 Spd_Crl_Mode "0x5";
BA_ "GenSigRoutingTimeoutValue" SG_ 602 Spd_Crl_Mode 5;
BA_ "GenSigSendType" SG_ 602 LEDlitWarnReq 3;
BA_ "GenSigSendType" SG_ 602 Charge 3;
BA_ "GenSigSendType" SG_ 602 ParkBrake 3;
BA_ "GenSigSendType" SG_ 602 Trip_B 3;
BA_ "DataCenterDataType" SG_ 602 Trip_B "Varchar(10)";
BA_ "GenSigSendType" SG_ 602 Trip_A 3;
BA_ "DataCenterDataType" SG_ 602 Trip_A "Varchar(10)";
BA_ "GenSigSendType" SG_ 602 ODOMETER 3;
BA_ "DataCenterDataType" SG_ 602 ODOMETER "Varchar(10)";
BA_ "GenSigInvalidValue" SG_ 1168 VehACModReq 7;
BA_ "GenSigRoutingTimeoutValue_String" SG_ 1168 VehACModReq "0x7";
BA_ "GenSigRoutingTimeoutValue" SG_ 1168 VehACModReq 7;
BA_ "GenSigSendType" SG_ 1168 VehACModReq 3;
BA_ "GenSigSendType" SG_ 1168 FCP_FrEvt_BtnACMaxReq 3;
BA_ "GenSigSendType" SG_ 1168 FCP_FrEvt_BtnACReq 3;
BA_ "DataCenterDataType" SG_ 1168 FCP_FrEvt_BtnACReq "Varchar(10)";
BA_ "GenSigSendType" SG_ 1168 FCP_FrEvt_BtnAutoReq 3;
BA_ "GenSigSendType" SG_ 1168 FCP_MidEvt_BtnAutoReq 3;
BA_ "GenSigSendType" SG_ 1168 FCP_FrEvt_BtnSyncReq 3;
BA_ "GenSigSendType" SG_ 1168 OTA_DL_Req 3;
BA_ "GenSigSendType" SG_ 1168 OTA_SuspendDL_Req 3;
BA_ "GenSigSendType" SG_ 1168 OTA_UpdStart_Req 3;
BA_ "GenSigSendType" SG_ 1168 IVI_OTA_Upd_Sta 3;
BA_ "GenSigSendType" SG_ 1168 OTA_CancelDL_Req 3;
BA_ "GenSigSendType" SG_ 1168 SmartEco_Mode_SW 3;
BA_ "GenSigSendType" SG_ 1168 LINKtoDrive 3;
BA_ "GenSigSendType" SG_ 1168 Upd_Countdown_Skip 3;
BA_ "GenSigSendType" SG_ 1168 Upd_Countdown_Cancel 3;
BA_ "GenSigInvalidValue" SG_ 1168 AmbLightColorSet 127;
BA_ "GenSigStartValue" SG_ 1168 AmbLightColorSet 64;
BA_ "GenSigRoutingTimeoutValue_String" SG_ 1168 AmbLightColorSet "0x7F";
BA_ "GenSigInactiveValue" SG_ 1168 AmbLightColorSet 64;
BA_ "GenSigRoutingTimeoutValue" SG_ 1168 AmbLightColorSet 127;
BA_ "GenSigSendType" SG_ 1168 AmbLightColorSet 3;
BA_ "GenSigSendType" SG_ 1168 Sched_OTA_wake 3;
BA_ "GenSigSendType" SG_ 1168 UserSet 3;
BA_ "GenSigInvalidValue" SG_ 1168 AmbLightBrightnessSet 127;
BA_ "GenSigStartValue" SG_ 1168 AmbLightBrightnessSet 101;
BA_ "GenSigRoutingTimeoutValue_String" SG_ 1168 AmbLightBrightnessSet "0x7F";
BA_ "GenSigInactiveValue" SG_ 1168 AmbLightBrightnessSet 101;
BA_ "GenSigRoutingTimeoutValue" SG_ 1168 AmbLightBrightnessSet 127;
BA_ "GenSigSendType" SG_ 1168 AmbLightBrightnessSet 3;
BA_ "GenSigSendType" SG_ 1168 Sched_Chg_Day_Set 3;
BA_ "GenSigSendType" SG_ 1168 Re_Radio_Sta 3;
BA_ "GenSigSendType" SG_ 1168 Sched_Chg_St_Time_Min 3;
BA_ "GenSigSendType" SG_ 1168 A2B_Node_sta 3;
BA_ "GenSigInvalidValue" SG_ 1168 Sched_Chg_St_Time_HR 31;
BA_ "GenSigSendType" SG_ 1168 Sched_Chg_St_Time_HR 3;
BA_ "GenSigInvalidValue" SG_ 1168 IVI_Located_STA 3;
BA_ "GenSigStartValue" SG_ 1168 IVI_Located_STA 3;
BA_ "GenSigRoutingTimeoutValue_String" SG_ 1168 IVI_Located_STA "0x3";
BA_ "GenSigInactiveValue" SG_ 1168 IVI_Located_STA 3;
BA_ "GenSigRoutingTimeoutValue" SG_ 1168 IVI_Located_STA 3;
BA_ "GenSigSendType" SG_ 1168 IVI_Located_STA 3;
BA_ "DataCenterDataType" SG_ 1168 IVI_Located_STA "Varchar(10)";
BA_ "GenSigSendType" SG_ 1168 Sched_Chg_End_Time_Min 3;
BA_ "GenSigSendType" SG_ 1168 OTA_CompNTFY_Pres 3;
BA_ "GenSigSendType" SG_ 1168 BrkAbn_GoReady_SW 3;
BA_ "GenSigInvalidValue" SG_ 1168 Sched_Chg_End_Time_HR 31;
BA_ "GenSigSendType" SG_ 1168 Sched_Chg_End_Time_HR 3;
BA_ "GenSigSendType" SG_ 1168 PW_CONTINUE_USE 3;
BA_ "GenSigSendType" SG_ 1168 PW_CLOSE_IMD 3;
BA_ "GenSigSendType" SG_ 1168 mFRD_link_Sta 3;
BA_ "GenSigSendType" SG_ 1168 AmbLight_SW 3;
BA_ "GenSigSendType" SG_ 1168 AmbLight_DimInDark_SW 3;
BA_ "GenSigSendType" SG_ 1168 AmbLight_WlcmLight_SW 3;
BA_ "GenSigSendType" SG_ 1168 AmbLigh_LowBatAlert_SW 3;
BA_ "GenSigSendType" SG_ 1168 AmbLigh_SafetyAlert_SW 3;
BA_ "GenSigSendType" SG_ 1168 OpenDrOpenWdo_SW 3;
BA_ "GenSigSendType" SG_ 1168 IVI_LinkKey_Sta 3;
BA_ "GenSigSendType" SG_ 1168 IVI_CreateAccReq_Sta 3;
BA_ "GenSigSendType" SG_ 1168 IVI_DelAccReq_Sta 3;
BA_ "GenSigSendType" SG_ 1168 IVI_LinkAcc_Sta 3;
BA_ "GenSigSendType" SG_ 1168 IVI_LinkAccReq_Sta 3;
BA_ "GenSigSendType" SG_ 1168 IVI_FrTrunk_UnlockReq_Sta 3;
BA_ "GenSigSendType" SG_ 1168 IVI_CLWin_LockDoorSW_Sta 3;
BA_ "GenSigSendType" SG_ 1168 IVI_Lock_SoundSW_Sta 3;
BA_ "GenSigSendType" SG_ 1168 IVI_SWC_VibMode_Sta 3;
BA_ "GenSigSendType" SG_ 1168 IVI_DMS_SW_Sta 3;
BA_ "GenSigSendType" SG_ 1168 IVI_AirRefresh_ByDMS_Sta 3;
BA_ "GenSigSendType" SG_ 1168 IVI_QuickRefresh_Sta 3;
BA_ "GenSigRoutingTimeoutValue_String" SG_ 1168 IVI_HMI_Undefined_Sta "0x0";
BA_ "GenSigSendType" SG_ 1168 IVI_HMI_Undefined_Sta 3;
BA_ "GenSigRoutingTimeoutValue_String" SG_ 1168 IVI_AutoTheme_But_Sta "0x0";
BA_ "GenSigSendType" SG_ 1168 IVI_AutoTheme_But_Sta 3;
BA_ "GenSigRoutingTimeoutValue_String" SG_ 1168 IVI_NAVI_Foreground_Sta "0x0";
BA_ "GenSigSendType" SG_ 1168 IVI_NAVI_Foreground_Sta 3;
BA_ "GenSigRoutingTimeoutValue_String" SG_ 1168 IVI_sigScreenReq_Sta "0x0";
BA_ "GenSigSendType" SG_ 1168 IVI_sigScreenReq_Sta 3;
BA_ "GenSigRoutingTimeoutValue_String" SG_ 1168 IVI_DSEAT_anti_set_Sta "0x0";
BA_ "GenSigSendType" SG_ 1168 IVI_DSEAT_anti_set_Sta 3;
BA_ "GenSigRoutingTimeoutValue_String" SG_ 1168 IVI_MirrorFolded_SW_Sta "0x0";
BA_ "GenSigSendType" SG_ 1168 IVI_MirrorFolded_SW_Sta 3;
BA_ "GenSigRoutingTimeoutValue_String" SG_ 1168 IVI_WPTC_SW_Sta "0x0";
BA_ "GenSigSendType" SG_ 1168 IVI_WPTC_SW_Sta 3;
BA_ "GenSigRoutingTimeoutValue_String" SG_ 1168 IVI_Driving_Lock_SW_Sta "0x0";
BA_ "GenSigSendType" SG_ 1168 IVI_Driving_Lock_SW_Sta 3;
BA_ "GenSigRoutingTimeoutValue_String" SG_ 1168 IVI_Stopping_Unlock_SW_Sta "0x0";
BA_ "GenSigSendType" SG_ 1168 IVI_Stopping_Unlock_SW_Sta 3;
BA_ "GenSigRoutingTimeoutValue_String" SG_ 1168 IVI_SilentChrg_Alert_Sta "0x0";
BA_ "GenSigSendType" SG_ 1168 IVI_SilentChrg_Alert_Sta 3;
BA_ "DataCenterDataType" SG_ 1168 IVI_SilentChrg_Alert_Sta "varchar(20)";
BA_ "GenSigRoutingTimeoutValue_String" SG_ 1168 IVI_WirelessCharge_Cmd "0x0";
BA_ "GenSigSendType" SG_ 1168 IVI_WirelessCharge_Cmd 3;
BA_ "GenSigRoutingTimeoutValue_String" SG_ 1168 IVI_Theme_Sta "0x0";
BA_ "GenSigSendType" SG_ 1168 IVI_Theme_Sta 3;
BA_ "GenSigRoutingTimeoutValue_String" SG_ 1168 IVI_EPS_Force_Cmd "0x0";
BA_ "GenSigSendType" SG_ 1168 IVI_EPS_Force_Cmd 3;
BA_ "GenSigInvalidValue" SG_ 1168 IVI_DSEAT_StopKeepMove_Sta 3;
BA_ "GenSigRoutingTimeoutValue_String" SG_ 1168 IVI_DSEAT_StopKeepMove_Sta "0x0";
BA_ "GenSigSendType" SG_ 1168 IVI_DSEAT_StopKeepMove_Sta 3;
BA_ "GenSigRoutingTimeoutValue_String" SG_ 1168 IVI_AutoWipHSpdSW_Cmd "0x0";
BA_ "GenSigSendType" SG_ 1168 IVI_AutoWipHSpdSW_Cmd 3;
BA_ "GenSigRoutingTimeoutValue_String" SG_ 1168 IVI_DSEAT_entryfun_set_Sta "0x0";
BA_ "GenSigSendType" SG_ 1168 IVI_DSEAT_entryfun_set_Sta 3;
BA_ "GenSigInvalidValue" SG_ 1173 SOC_V2LLimit 15;
BA_ "GenSigRoutingTimeoutValue_String" SG_ 1173 SOC_V2LLimit "0xF";
BA_ "GenSigRoutingTimeoutValue" SG_ 1173 SOC_V2LLimit 15;
BA_ "GenSigSendType" SG_ 1173 Perd_V2L 3;
BA_ "GenSigSendType" SG_ 1173 IVI_Req_V2L 3;
BA_ "GenSigInvalidValue" SG_ 1173 IVI_PTG_Open_Height 7;
BA_ "GenSigStartValue" SG_ 1173 IVI_PTG_Open_Height 5;
BA_ "GenSigRoutingTimeoutValue_String" SG_ 1173 IVI_PTG_Open_Height "0x7";
BA_ "GenSigInactiveValue" SG_ 1173 IVI_PTG_Open_Height 5;
BA_ "GenSigRoutingTimeoutValue" SG_ 1173 IVI_PTG_Open_Height 7;
BA_ "GenSigSendType" SG_ 1173 IVI_PTG_Open_Height 3;
BA_ "GenSigSendType" SG_ 1173 IVI_CreepSW_Req 3;
BA_ "GenSigStartValue" SG_ 1173 FalseNPrevent_SW 1;
BA_ "GenSigSendType" SG_ 1173 FalseNPrevent_SW 3;
BA_ "GenSigRoutingTimeoutValue_String" SG_ 1173 Approach_Unlock_SW "0x0";
BA_ "GenSigSendType" SG_ 1173 Approach_Unlock_SW 3;
BA_ "GenSigRoutingTimeoutValue_String" SG_ 1173 Walkaway_Lock_SW "0x0";
BA_ "GenSigSendType" SG_ 1173 Walkaway_Lock_SW 3;
BA_ "GenSigInvalidValue" SG_ 1173 Sched_Chg_limit 31;
BA_ "GenSigStartValue" SG_ 1173 Sched_Chg_limit 25;
BA_ "GenSigRoutingTimeoutValue_String" SG_ 1173 Sched_Chg_limit "0x1F";
BA_ "GenSigRoutingTimeoutValue" SG_ 1173 Sched_Chg_limit 31;
BA_ "GenSigSendType" SG_ 1173 Sched_Chg_Stop 3;
BA_ "GenSigSendType" SG_ 1173 Sched_Chg_butt 3;
BA_ "GenSigSendType" SG_ 1173 Sched_Chg_wake 3;
BA_ "GenSigSendType" SG_ 1173 Sched_Chg_Start 3;
BA_ "GenSigSendType" SG_ 1173 sigFaceReq 3;
BA_ "GenSigSendType" SG_ 1173 sigFootReq 3;
BA_ "GenSigInvalidValue" SG_ 1173 METER_Malfunc_Sta 3;
BA_ "GenSigSendType" SG_ 1173 METER_Malfunc_Sta 3;
BA_ "DataCenterDataType" SG_ 1173 METER_Malfunc_Sta "Varchar(20)";
BA_ "GenSigSendType" SG_ 1173 IVI_Start_Chg_req 3;
BA_ "GenSigInvalidValue" SG_ 1173 L_RRD_ControlCommand 127;
BA_ "GenSigStartValue" SG_ 1173 L_RRD_ControlCommand 127;
BA_ "GenSigRoutingTimeoutValue_String" SG_ 1173 L_RRD_ControlCommand "0x7F";
BA_ "GenSigInactiveValue" SG_ 1173 L_RRD_ControlCommand 127;
BA_ "GenSigRoutingTimeoutValue" SG_ 1173 L_RRD_ControlCommand 127;
BA_ "GenSigSendType" SG_ 1173 IVI_Stop_Chg_req 3;
BA_ "GenSigInvalidValue" SG_ 1173 L_RLD_ControlCommand 127;
BA_ "GenSigStartValue" SG_ 1173 L_RLD_ControlCommand 127;
BA_ "GenSigRoutingTimeoutValue_String" SG_ 1173 L_RLD_ControlCommand "0x7F";
BA_ "GenSigInactiveValue" SG_ 1173 L_RLD_ControlCommand 127;
BA_ "GenSigRoutingTimeoutValue" SG_ 1173 L_RLD_ControlCommand 127;
BA_ "GenSigSendType" SG_ 1173 IVI_Unlock_Chg_req 3;
BA_ "DataCenterDataType" SG_ 1173 IVI_Unlock_Chg_req "Varchar(10)";
BA_ "GenSigInvalidValue" SG_ 1173 L_Pas_ControlCommand 127;
BA_ "GenSigStartValue" SG_ 1173 L_Pas_ControlCommand 127;
BA_ "GenSigRoutingTimeoutValue_String" SG_ 1173 L_Pas_ControlCommand "0x7F";
BA_ "GenSigInactiveValue" SG_ 1173 L_Pas_ControlCommand 127;
BA_ "GenSigRoutingTimeoutValue" SG_ 1173 L_Pas_ControlCommand 127;
BA_ "GenSigSendType" SG_ 1173 TPMS_Cali_Butt 3;
BA_ "GenSigInvalidValue" SG_ 1173 L_Drv_ControlCommand 127;
BA_ "GenSigStartValue" SG_ 1173 L_Drv_ControlCommand 127;
BA_ "GenSigRoutingTimeoutValue_String" SG_ 1173 L_Drv_ControlCommand "0x7F";
BA_ "GenSigInactiveValue" SG_ 1173 L_Drv_ControlCommand 127;
BA_ "GenSigRoutingTimeoutValue" SG_ 1173 L_Drv_ControlCommand 127;
BA_ "GenSigSendType" SG_ 1173 GPS_LONG 3;
BA_ "DataCenterDataType" SG_ 1173 GPS_LONG "Decimal";
BA_ "GenSigSendType" SG_ 1173 GPS_LAT 3;
BA_ "DataCenterDataType" SG_ 1173 GPS_LAT "Decimal";
BA_ "GenSigSendType" SG_ 1173 sigDfrstReq 3;
BA_ "GenSigSendType" SG_ 1173 sigHvacFrontReq 3;
BA_ "GenSigInvalidValue" SG_ 1173 sigSetTempZon1Req 31;
BA_ "GenSigStartValue" SG_ 1173 sigSetTempZon1Req 31;
BA_ "GenSigRoutingTimeoutValue_String" SG_ 1173 sigSetTempZon1Req "0x1F";
BA_ "GenSigInactiveValue" SG_ 1173 sigSetTempZon1Req 31;
BA_ "GenSigRoutingTimeoutValue" SG_ 1173 sigSetTempZon1Req 31;
BA_ "GenSigSendType" SG_ 1173 sigSetTempZon1Req 3;
BA_ "DataCenterDataType" SG_ 1173 sigSetTempZon1Req "Decimal";
BA_ "GenSigSendType" SG_ 1173 sigHvacReq 3;
BA_ "GenSigSendType" SG_ 1173 sigRecircReq 3;
BA_ "GenSigInvalidValue" SG_ 1173 sigSetTempZon2Req 31;
BA_ "GenSigStartValue" SG_ 1173 sigSetTempZon2Req 31;
BA_ "GenSigRoutingTimeoutValue_String" SG_ 1173 sigSetTempZon2Req "0x1F";
BA_ "GenSigInactiveValue" SG_ 1173 sigSetTempZon2Req 31;
BA_ "GenSigRoutingTimeoutValue" SG_ 1173 sigSetTempZon2Req 31;
BA_ "GenSigSendType" SG_ 1173 sigSetTempZon2Req 3;
BA_ "DataCenterDataType" SG_ 1173 sigSetTempZon2Req "Varchar(10)";
BA_ "GenSigSendType" SG_ 1173 sigSetTempZon3Req 3;
BA_ "GenSigInvalidValue" SG_ 1173 AEB_BUTT 2;
BA_ "GenSigRoutingTimeoutValue_String" SG_ 1173 AEB_BUTT "0x2";
BA_ "GenSigRoutingTimeoutValue" SG_ 1173 AEB_BUTT 2;
BA_ "GenSigSendType" SG_ 1173 AEB_BUTT 3;
BA_ "GenSigInvalidValue" SG_ 1173 sigAirIntenZon1Req 15;
BA_ "GenSigRoutingTimeoutValue_String" SG_ 1173 sigAirIntenZon1Req "0xF";
BA_ "GenSigRoutingTimeoutValue" SG_ 1173 sigAirIntenZon1Req 15;
BA_ "GenSigSendType" SG_ 1173 sigAirIntenZon1Req 3;
BA_ "GenSigInvalidValue" SG_ 1173 sigAirIntenZon3Req 15;
BA_ "GenSigRoutingTimeoutValue_String" SG_ 1173 sigAirIntenZon3Req "0xF";
BA_ "GenSigRoutingTimeoutValue" SG_ 1173 sigAirIntenZon3Req 15;
BA_ "GenSigSendType" SG_ 1173 sigAirIntenZon3Req 3;
BA_ "DataCenterDataType" SG_ 1173 sigAirIntenZon3Req "Varchar(30)";
BA_ "GenSigInvalidValue" SG_ 1173 sigWindDirZon3Req 7;
BA_ "GenSigStartValue" SG_ 1173 sigWindDirZon3Req 7;
BA_ "GenSigRoutingTimeoutValue_String" SG_ 1173 sigWindDirZon3Req "0x7";
BA_ "GenSigInactiveValue" SG_ 1173 sigWindDirZon3Req 7;
BA_ "GenSigRoutingTimeoutValue" SG_ 1173 sigWindDirZon3Req 7;
BA_ "GenSigSendType" SG_ 1173 sigWindDirZon3Req 3;
BA_ "GenSigInvalidValue" SG_ 1173 BSDMute_BUTT 2;
BA_ "GenSigRoutingTimeoutValue_String" SG_ 1173 BSDMute_BUTT "0x2";
BA_ "GenSigRoutingTimeoutValue" SG_ 1173 BSDMute_BUTT 2;
BA_ "GenSigSendType" SG_ 1173 BSDMute_BUTT 3;
BA_ "GenSigInvalidValue" SG_ 1173 LDWMute_BUTT 2;
BA_ "GenSigRoutingTimeoutValue_String" SG_ 1173 LDWMute_BUTT "0x2";
BA_ "GenSigRoutingTimeoutValue" SG_ 1173 LDWMute_BUTT 2;
BA_ "GenSigSendType" SG_ 1173 LDWMute_BUTT 3;
BA_ "GenSigInvalidValue" SG_ 1173 ODAMute_BUTT 2;
BA_ "GenSigRoutingTimeoutValue_String" SG_ 1173 ODAMute_BUTT "0x2";
BA_ "GenSigRoutingTimeoutValue" SG_ 1173 ODAMute_BUTT 2;
BA_ "GenSigSendType" SG_ 1173 ODAMute_BUTT 3;
BA_ "GenSigInvalidValue" SG_ 1173 LKA_BUTT 2;
BA_ "GenSigRoutingTimeoutValue_String" SG_ 1173 LKA_BUTT "0x2";
BA_ "GenSigRoutingTimeoutValue" SG_ 1173 LKA_BUTT 2;
BA_ "GenSigSendType" SG_ 1173 LKA_BUTT 3;
BA_ "GenSigInvalidValue" SG_ 1173 FCWMute_BUTT 2;
BA_ "GenSigRoutingTimeoutValue_String" SG_ 1173 FCWMute_BUTT "0x2";
BA_ "GenSigRoutingTimeoutValue" SG_ 1173 FCWMute_BUTT 2;
BA_ "GenSigSendType" SG_ 1173 FCWMute_BUTT 3;
BA_ "GenSigSendType" SG_ 1173 sigHvacRearReq 3;
BA_ "GenSigSendType" SG_ 1173 IVI_Panel_Act 3;
BA_ "GenSigInvalidValue" SG_ 1173 ESC_SW_Cmd 3;
BA_ "GenSigRoutingTimeoutValue_String" SG_ 1173 ESC_SW_Cmd "0x3";
BA_ "GenSigRoutingTimeoutValue" SG_ 1173 ESC_SW_Cmd 3;
BA_ "GenSigSendType" SG_ 1173 ESC_SW_Cmd 3;
BA_ "GenSigSendType" SG_ 1173 Distance_unit 3;
BA_ "GenSigSendType" SG_ 1173 Temperature_unit 3;
BA_ "GenSigInvalidValue" SG_ 1173 NAVI_Speed_Limit_A 3;
BA_ "GenSigRoutingTimeoutValue_String" SG_ 1173 NAVI_Speed_Limit_A "0x3";
BA_ "GenSigRoutingTimeoutValue" SG_ 1173 NAVI_Speed_Limit_A 3;
BA_ "GenSigSendType" SG_ 1173 NAVI_Speed_Limit_A 3;
BA_ "GenSigSendType" SG_ 1173 Time_system 3;
BA_ "GenSigRoutingTimeoutValue_String" SG_ 1173 TurnSwTimeSet "0x3";
BA_ "GenSigRoutingTimeoutValue" SG_ 1173 TurnSwTimeSet 3;
BA_ "GenSigSendType" SG_ 1173 TurnSwTimeSet 3;
BA_ "GenSigInvalidValue" SG_ 1173 IVI_Screen 63;
BA_ "GenSigRoutingTimeoutValue_String" SG_ 1173 IVI_Screen "0x3F";
BA_ "GenSigRoutingTimeoutValue" SG_ 1173 IVI_Screen 63;
BA_ "GenSigSendType" SG_ 1173 IVI_Screen 3;
BA_ "GenSigSendType" SG_ 1173 Wifi_Reset 3;
BA_ "GenSigSendType" SG_ 1173 CameraWrn 3;
BA_ "GenSigSendType" SG_ 1173 User_p_upload 3;
BA_ "GenSigRoutingTimeoutValue_String" SG_ 1173 IVI_PW_Mode_Req "0x3";
BA_ "GenSigRoutingTimeoutValue" SG_ 1173 IVI_PW_Mode_Req 3;
BA_ "GenSigSendType" SG_ 1173 IVI_PW_Mode_Req 3;
BA_ "GenSigInvalidValue" SG_ 1173 OFF_AC_MODE 7;
BA_ "GenSigRoutingTimeoutValue_String" SG_ 1173 OFF_AC_MODE "0x7";
BA_ "GenSigInactiveValue" SG_ 1173 OFF_AC_MODE 7;
BA_ "GenSigRoutingTimeoutValue" SG_ 1173 OFF_AC_MODE 7;
BA_ "GenSigSendType" SG_ 1173 OFF_AC_MODE 3;
BA_ "GenSigInvalidValue" SG_ 1173 NAVI_Cam_Dist_info 255;
BA_ "GenSigRoutingTimeoutValue_String" SG_ 1173 NAVI_Cam_Dist_info "0xFF";
BA_ "GenSigRoutingTimeoutValue" SG_ 1173 NAVI_Cam_Dist_info 255;
BA_ "GenSigRoutingTimeoutValue_String" SG_ 1173 Wifi_Sta_IVI_TBOX "0x0";
BA_ "GenSigSendType" SG_ 1173 Wifi_Sta_IVI_TBOX 3;
BA_ "GenSigSendType" SG_ 1173 NAVI_State 3;
BA_ "GenSigRoutingTimeoutValue_String" SG_ 1173 HeadLampSW "0x0";
BA_ "GenSigSendType" SG_ 1173 HeadLampSW 3;
BA_ "GenSigSendType" SG_ 1173 User_p_download 3;
BA_ "GenSigInvalidValue" SG_ 1173 MFRD_N_Bright_Req 127;
BA_ "GenSigRoutingTimeoutValue_String" SG_ 1173 MFRD_N_Bright_Req "0x7F";
BA_ "GenSigRoutingTimeoutValue" SG_ 1173 MFRD_N_Bright_Req 127;
BA_ "GenSigSendType" SG_ 1173 MFRD_N_Bright_Req 3;
BA_ "GenSigSendType" SG_ 1173 RFogLampSW 3;
BA_ "GenSigRoutingTimeoutValue_String" SG_ 1173 DSEAT_vent_req "0x0";
BA_ "GenSigSendType" SG_ 1173 DSEAT_vent_req 3;
BA_ "GenSigSendType" SG_ 1173 FFogLampSW 3;
BA_ "GenSigSendType" SG_ 1173 PSEAT_vent_req 3;
BA_ "GenSigInvalidValue" SG_ 1173 FS_Off_Sw 2;
BA_ "GenSigRoutingTimeoutValue_String" SG_ 1173 FS_Off_Sw "0x2";
BA_ "GenSigRoutingTimeoutValue" SG_ 1173 FS_Off_Sw 2;
BA_ "GenSigSendType" SG_ 1173 FS_Off_Sw 3;
BA_ "GenSigInvalidValue" SG_ 1173 SLG_Sw 2;
BA_ "GenSigRoutingTimeoutValue_String" SG_ 1173 SLG_Sw "0x2";
BA_ "GenSigRoutingTimeoutValue" SG_ 1173 SLG_Sw 2;
BA_ "GenSigSendType" SG_ 1173 SLG_Sw 3;
BA_ "GenSigInvalidValue" SG_ 1173 IVI_PTG_Sta_SW 2;
BA_ "GenSigRoutingTimeoutValue_String" SG_ 1173 IVI_PTG_Sta_SW "0x2";
BA_ "GenSigRoutingTimeoutValue" SG_ 1173 IVI_PTG_Sta_SW 2;
BA_ "GenSigSendType" SG_ 1173 IVI_PTG_Sta_SW 3;
BA_ "GenSigInvalidValue" SG_ 1173 IVI_PTG_Mode_SW 2;
BA_ "GenSigRoutingTimeoutValue_String" SG_ 1173 IVI_PTG_Mode_SW "0x2";
BA_ "GenSigRoutingTimeoutValue" SG_ 1173 IVI_PTG_Mode_SW 2;
BA_ "GenSigSendType" SG_ 1173 IVI_PTG_Mode_SW 3;
BA_ "GenSigSendType" SG_ 1173 SetUnlockSingle 3;
BA_ "GenSigSendType" SG_ 1173 FollowMeSW 3;
BA_ "GenSigSendType" SG_ 1173 TPMS_Res_Butt 3;
BA_ "DataCenterDataType" SG_ 1173 TPMS_Res_Butt "varchar(10)";
BA_ "GenSigRoutingTimeoutValue_String" SG_ 1173 DSEAT_anti_set "0x0";
BA_ "GenSigSendType" SG_ 1173 DSEAT_anti_set 3;
BA_ "GenSigRoutingTimeoutValue_String" SG_ 1173 DSEAT_entryfun_set "0x0";
BA_ "GenSigSendType" SG_ 1173 DSEAT_entryfun_set 3;
BA_ "GenSigInvalidValue" SG_ 1173 CAAS_Sw 2;
BA_ "GenSigRoutingTimeoutValue_String" SG_ 1173 CAAS_Sw "0x2";
BA_ "GenSigRoutingTimeoutValue" SG_ 1173 CAAS_Sw 2;
BA_ "GenSigSendType" SG_ 1173 CAAS_Sw 3;
BA_ "GenSigInvalidValue" SG_ 1173 LVDAMute_BUTT 2;
BA_ "GenSigRoutingTimeoutValue_String" SG_ 1173 LVDAMute_BUTT "0x2";
BA_ "GenSigRoutingTimeoutValue" SG_ 1173 LVDAMute_BUTT 2;
BA_ "GenSigSendType" SG_ 1173 LVDAMute_BUTT 3;
BA_ "GenSigSendType" SG_ 1173 IVI_Status 3;
BA_ "GenSigSendType" SG_ 1173 IVI_Night_Mode_Sta 3;
BA_ "GenSigSendType" SG_ 1173 IVI_RR_Def_Req 3;
BA_ "GenSigSendType" SG_ 1173 IVI_WI_MAIN_SW 3;
BA_ "GenSigSendType" SG_ 1173 IVI_PTG_USSta_SW 3;
BA_ "GenSigSendType" SG_ 1173 IVI_Mute_Sta 3;
BA_ "GenSigSendType" SG_ 1173 AVM_Err_STA 3;
BA_ "GenSigSendType" SG_ 1173 IVI_Trigger_req 3;
BA_ "GenSigSendType" SG_ 1173 IVI_Pwroff_req 3;
BA_ "GenSigInvalidValue" SG_ 1173 RCTA_BUTT 2;
BA_ "GenSigRoutingTimeoutValue_String" SG_ 1173 RCTA_BUTT "0x2";
BA_ "GenSigRoutingTimeoutValue" SG_ 1173 RCTA_BUTT 2;
BA_ "GenSigSendType" SG_ 1173 RCTA_BUTT 3;
BA_ "GenSigInvalidValue" SG_ 1173 Hood_Latch_SW 2;
BA_ "GenSigRoutingTimeoutValue_String" SG_ 1173 Hood_Latch_SW "0x2";
BA_ "GenSigRoutingTimeoutValue" SG_ 1173 Hood_Latch_SW 2;
BA_ "GenSigSendType" SG_ 1173 Hood_Latch_SW 3;
BA_ "GenSigSendType" SG_ 1173 AVM_Parking_mode 3;
BA_ "GenSigSendType" SG_ 1173 SenstivityPosition 3;
BA_ "GenSigSendType" SG_ 1173 NAVI_ForwardLinkLevel 3;
BA_ "GenSigSendType" SG_ 1173 NAVI_LinkClass 3;
BA_ "GenSigSendType" SG_ 1173 NAVI_RoadClass 3;
BA_ "GenSigSendType" SG_ 1173 RoomLampMode 3;
BA_ "GenSigInvalidValue" SG_ 1173 IVI_ISA_OffsetSpd 15;
BA_ "GenSigStartValue" SG_ 1173 IVI_ISA_OffsetSpd 15;
BA_ "GenSigRoutingTimeoutValue_String" SG_ 1173 IVI_ISA_OffsetSpd "0xF";
BA_ "GenSigInactiveValue" SG_ 1173 IVI_ISA_OffsetSpd 15;
BA_ "GenSigRoutingTimeoutValue" SG_ 1173 IVI_ISA_OffsetSpd 15;
BA_ "GenSigSendType" SG_ 1173 IVI_ISA_OffsetSpd 3;
BA_ "GenSigStartValue" SG_ 1173 AC_Chg_Cur_Set 127;
BA_ "GenSigRoutingTimeoutValue_String" SG_ 1173 AC_Chg_Cur_Set "0x7F";
BA_ "GenSigRoutingTimeoutValue" SG_ 1173 AC_Chg_Cur_Set 127;
BA_ "GenSigSendType" SG_ 1173 AC_Chg_Cur_Set 3;
BA_ "DataCenterDataType" SG_ 1173 AC_Chg_Cur_Set "Decimal";
BA_ "GenSigSendType" SG_ 1173 SOC_ADJ_BUTT 3;
BA_ "GenSigSendType" SG_ 1173 CDL_Unlock_Butt 3;
BA_ "GenSigSendType" SG_ 1173 CDL_Lock_Butt 3;
BA_ "GenSigInvalidValue" SG_ 1173 SOC_Limit_Set 31;
BA_ "GenSigStartValue" SG_ 1173 SOC_Limit_Set 25;
BA_ "GenSigRoutingTimeoutValue_String" SG_ 1173 SOC_Limit_Set "0x1F";
BA_ "GenSigRoutingTimeoutValue" SG_ 1173 SOC_Limit_Set 31;
BA_ "DataCenterDataType" SG_ 1173 SOC_Limit_Set "Varchar(10)";
BA_ "GenSigSendType" SG_ 1173 Roll_Eng_Mode 3;
BA_ "GenSigInvalidValue" SG_ 1173 SLIF_BUTT 2;
BA_ "GenSigRoutingTimeoutValue_String" SG_ 1173 SLIF_BUTT "0x2";
BA_ "GenSigRoutingTimeoutValue" SG_ 1173 SLIF_BUTT 2;
BA_ "GenSigSendType" SG_ 1173 SLIF_BUTT 3;
BA_ "GenSigInvalidValue" SG_ 1173 TCS_SW_Cmd 3;
BA_ "GenSigRoutingTimeoutValue_String" SG_ 1173 TCS_SW_Cmd "0x3";
BA_ "GenSigRoutingTimeoutValue" SG_ 1173 TCS_SW_Cmd 3;
BA_ "GenSigSendType" SG_ 1173 TCS_SW_Cmd 3;
BA_ "GenSigInvalidValue" SG_ 1173 Roll_Mode_SW_Cmd 3;
BA_ "GenSigRoutingTimeoutValue_String" SG_ 1173 Roll_Mode_SW_Cmd "0x3";
BA_ "GenSigRoutingTimeoutValue" SG_ 1173 Roll_Mode_SW_Cmd 3;
BA_ "GenSigSendType" SG_ 1173 Roll_Mode_SW_Cmd 3;
BA_ "GenSigInvalidValue" SG_ 1173 IVI_ActvDmpDisabSW 2;
BA_ "GenSigRoutingTimeoutValue_String" SG_ 1173 IVI_ActvDmpDisabSW "0x2";
BA_ "GenSigRoutingTimeoutValue" SG_ 1173 IVI_ActvDmpDisabSW 2;
BA_ "GenSigSendType" SG_ 1173 IVI_ActvDmpDisabSW 3;
BA_ "GenSigInvalidValue" SG_ 1173 IVI_CoastDwSW 2;
BA_ "GenSigRoutingTimeoutValue_String" SG_ 1173 IVI_CoastDwSW "0x2";
BA_ "GenSigRoutingTimeoutValue" SG_ 1173 IVI_CoastDwSW 2;
BA_ "GenSigSendType" SG_ 1173 IVI_CoastDwSW 3;
BA_ "GenSigInvalidValue" SG_ 1173 IVI_PwrLockSW 2;
BA_ "GenSigRoutingTimeoutValue_String" SG_ 1173 IVI_PwrLockSW "0x2";
BA_ "GenSigRoutingTimeoutValue" SG_ 1173 IVI_PwrLockSW 2;
BA_ "GenSigSendType" SG_ 1173 IVI_PwrLockSW 3;
BA_ "GenSigInvalidValue" SG_ 1173 IVI_LVChrgFuncSW 2;
BA_ "GenSigRoutingTimeoutValue_String" SG_ 1173 IVI_LVChrgFuncSW "0x2";
BA_ "GenSigRoutingTimeoutValue" SG_ 1173 IVI_LVChrgFuncSW 2;
BA_ "GenSigSendType" SG_ 1173 IVI_LVChrgFuncSW 3;
BA_ "GenSigInvalidValue" SG_ 1173 IVI_AGSCloseSW 2;
BA_ "GenSigRoutingTimeoutValue_String" SG_ 1173 IVI_AGSCloseSW "0x2";
BA_ "GenSigRoutingTimeoutValue" SG_ 1173 IVI_AGSCloseSW 2;
BA_ "GenSigSendType" SG_ 1173 IVI_AGSCloseSW 3;
BA_ "GenSigSendType" SG_ 1173 AVM_OFF_Rec_Butt 3;
BA_ "GenSigInvalidValue" SG_ 1173 AVM_parking_excute 2;
BA_ "GenSigRoutingTimeoutValue_String" SG_ 1173 AVM_parking_excute "0x2";
BA_ "GenSigRoutingTimeoutValue" SG_ 1173 AVM_parking_excute 2;
BA_ "GenSigSendType" SG_ 1173 AVM_parking_excute 3;
BA_ "GenSigInvalidValue" SG_ 1173 AVM_parking_cancel 2;
BA_ "GenSigRoutingTimeoutValue_String" SG_ 1173 AVM_parking_cancel "0x2";
BA_ "GenSigRoutingTimeoutValue" SG_ 1173 AVM_parking_cancel 2;
BA_ "GenSigSendType" SG_ 1173 AVM_parking_cancel 3;
BA_ "GenSigRoutingTimeoutValue_String" SG_ 1173 IVI_DSEATHeater_Cmd "0x0";
BA_ "GenSigSendType" SG_ 1173 IVI_DSEATHeater_Cmd 3;
BA_ "GenSigRoutingTimeoutValue_String" SG_ 1173 IVI_PSEATHeater_Cmd "0x0";
BA_ "GenSigSendType" SG_ 1173 IVI_PSEATHeater_Cmd 3;
BA_ "GenSigSendType" SG_ 1173 WlcmLight_Mode 3;
BA_ "GenSigSendType" SG_ 1173 IVI_CfmTo_Rdy 3;
BA_ "GenSigSendType" SG_ 1173 Light_ShowStart_Req 3;
BA_ "GenSigSendType" SG_ 1173 Light_ShowStop_Req 3;
BA_ "GenSigSendType" SG_ 1173 IVI_TrailerCheckReq_Sta 3;
BA_ "GenSigSendType" SG_ 1173 IVI_TrailerModeSW_Sta 3;
BA_ "GenSigRoutingTimeoutValue_String" SG_ 1173 IVI_FGSAirInt_Cmd "0x7";
BA_ "GenSigRoutingTimeoutValue" SG_ 1173 IVI_FGSAirInt_Cmd 7;
BA_ "GenSigSendType" SG_ 1173 IVI_FGSAirInt_Cmd 3;
BA_ "GenSigSendType" SG_ 1173 IVI_FGSCh_Cmd 3;
BA_ "GenSigSendType" SG_ 1173 IVI_IONSW_Cmd 3;
BA_ "GenSigSendType" SG_ 1173 IVI_SWC_ACCMode_Sta 3;
BA_ "GenSigSendType" SG_ 1173 IVI_SWC_LUndefined_Sta 3;
BA_ "GenSigSendType" SG_ 1173 IVI_SWC_RUndefined_Sta 3;
BA_ "GenSigSendType" SG_ 1173 IVI_ACC_Adaptive_Sta 3;
BA_ "GenSigInvalidValue" SG_ 1173 IVI_SLIF_Warning_Sta 3;
BA_ "GenSigStartValue" SG_ 1173 IVI_SLIF_Warning_Sta 3;
BA_ "GenSigRoutingTimeoutValue_String" SG_ 1173 IVI_SLIF_Warning_Sta "0x3";
BA_ "GenSigInactiveValue" SG_ 1173 IVI_SLIF_Warning_Sta 3;
BA_ "GenSigRoutingTimeoutValue" SG_ 1173 IVI_SLIF_Warning_Sta 3;
BA_ "GenSigSendType" SG_ 1173 IVI_SLIF_Warning_Sta 3;
BA_ "GenSigInvalidValue" SG_ 1173 IVI_SetTempZon1_Sta 31;
BA_ "GenSigStartValue" SG_ 1173 IVI_SetTempZon1_Sta 31;
BA_ "GenSigRoutingTimeoutValue_String" SG_ 1173 IVI_SetTempZon1_Sta "0x1F";
BA_ "GenSigInactiveValue" SG_ 1173 IVI_SetTempZon1_Sta 31;
BA_ "GenSigRoutingTimeoutValue" SG_ 1173 IVI_SetTempZon1_Sta 31;
BA_ "GenSigSendType" SG_ 1173 IVI_SetTempZon1_Sta 3;
BA_ "GenSigInvalidValue" SG_ 1173 IVI_SetTempZon2_Sta 31;
BA_ "GenSigStartValue" SG_ 1173 IVI_SetTempZon2_Sta 31;
BA_ "GenSigRoutingTimeoutValue_String" SG_ 1173 IVI_SetTempZon2_Sta "0x1F";
BA_ "GenSigInactiveValue" SG_ 1173 IVI_SetTempZon2_Sta 31;
BA_ "GenSigRoutingTimeoutValue" SG_ 1173 IVI_SetTempZon2_Sta 31;
BA_ "GenSigSendType" SG_ 1173 IVI_SetTempZon2_Sta 3;
BA_ "GenSigRoutingTimeoutValue_String" SG_ 1173 IVI_AirIntZ3_Cmd "0x0";
BA_ "GenSigSendType" SG_ 1173 IVI_AirIntZ3_Cmd 3;
BA_ "GenSigInvalidValue" SG_ 1173 IVI_DSEAT_Slide_Cmd 3;
BA_ "GenSigRoutingTimeoutValue_String" SG_ 1173 IVI_DSEAT_Slide_Cmd "0x3";
BA_ "GenSigRoutingTimeoutValue" SG_ 1173 IVI_DSEAT_Slide_Cmd 3;
BA_ "GenSigSendType" SG_ 1173 IVI_DSEAT_Slide_Cmd 3;
BA_ "GenSigInvalidValue" SG_ 1173 IVI_DSEAT_Recline_Cmd 3;
BA_ "GenSigRoutingTimeoutValue_String" SG_ 1173 IVI_DSEAT_Recline_Cmd "0x3";
BA_ "GenSigRoutingTimeoutValue" SG_ 1173 IVI_DSEAT_Recline_Cmd 3;
BA_ "GenSigSendType" SG_ 1173 IVI_DSEAT_Recline_Cmd 3;
BA_ "GenSigInvalidValue" SG_ 1173 IVI_DSEAT_Height_Cmd 3;
BA_ "GenSigRoutingTimeoutValue_String" SG_ 1173 IVI_DSEAT_Height_Cmd "0x3";
BA_ "GenSigRoutingTimeoutValue" SG_ 1173 IVI_DSEAT_Height_Cmd 3;
BA_ "GenSigSendType" SG_ 1173 IVI_DSEAT_Height_Cmd 3;
BA_ "GenSigInvalidValue" SG_ 1173 IVI_DSEAT_FroEdge_Height_Cmd 3;
BA_ "GenSigRoutingTimeoutValue_String" SG_ 1173 IVI_DSEAT_FroEdge_Height_Cmd "0x3";
BA_ "GenSigRoutingTimeoutValue" SG_ 1173 IVI_DSEAT_FroEdge_Height_Cmd 3;
BA_ "GenSigSendType" SG_ 1173 IVI_DSEAT_FroEdge_Height_Cmd 3;
BA_ "GenSigInvalidValue" SG_ 1173 IVI_PSEAT_Slide_Cmd 3;
BA_ "GenSigRoutingTimeoutValue_String" SG_ 1173 IVI_PSEAT_Slide_Cmd "0x3";
BA_ "GenSigRoutingTimeoutValue" SG_ 1173 IVI_PSEAT_Slide_Cmd 3;
BA_ "GenSigSendType" SG_ 1173 IVI_PSEAT_Slide_Cmd 3;
BA_ "GenSigInvalidValue" SG_ 1173 IVI_PSEAT_Recline_Cmd 3;
BA_ "GenSigRoutingTimeoutValue_String" SG_ 1173 IVI_PSEAT_Recline_Cmd "0x3";
BA_ "GenSigRoutingTimeoutValue" SG_ 1173 IVI_PSEAT_Recline_Cmd 3;
BA_ "GenSigSendType" SG_ 1173 IVI_PSEAT_Recline_Cmd 3;
BA_ "GenSigRoutingTimeoutValue_String" SG_ 1173 IVI_ChargePortSW_Sta "0x0";
BA_ "GenSigSendType" SG_ 1173 IVI_ChargePortSW_Sta 3;
BA_ "GenSigRoutingTimeoutValue_String" SG_ 1173 IVI_DSEAT_Memory1_Sta "0x0";
BA_ "GenSigSendType" SG_ 1173 IVI_DSEAT_Memory1_Sta 3;
BA_ "GenSigRoutingTimeoutValue_String" SG_ 1173 IVI_DSEAT_Memory2_Sta "0x0";
BA_ "GenSigSendType" SG_ 1173 IVI_DSEAT_Memory2_Sta 3;
BA_ "GenSigRoutingTimeoutValue_String" SG_ 1173 IVI_DSEAT_Memory_OPTCLS_Sta "0x0";
BA_ "GenSigSendType" SG_ 1173 IVI_DSEAT_Memory_OPTCLS_Sta 3;
BA_ "GenSigRoutingTimeoutValue_String" SG_ 1173 DMS_Status "0x0";
BA_ "GenSigRoutingTimeoutValue_String" SG_ 1173 DMS_Warning_Distraction "0x0";
BA_ "GenSigRoutingTimeoutValue_String" SG_ 1173 DMS_Warning_Fatigue "0x0";
BA_ "GenSigRoutingTimeoutValue_String" SG_ 1173 DMS_Warning_Unresponsive "0x0";
BA_ "GenSigRoutingTimeoutValue_String" SG_ 1173 IVI_FWipIntTSet_Cmd "0x0";
BA_ "GenSigSendType" SG_ 1173 IVI_FWipIntTSet_Cmd 3;
BA_ "GenSigRoutingTimeoutValue_String" SG_ 1173 IVI_CarWash_Mode_Cmd "0x0";
BA_ "GenSigSendType" SG_ 1173 IVI_CarWash_Mode_Cmd 3;
BA_ "GenSigRoutingTimeoutValue_String" SG_ 1173 IVI_Backlight_Sta "0x0";
BA_ "GenSigSendType" SG_ 1173 IVI_Backlight_Sta 3;
BA_ "GenSigInvalidValue" SG_ 1173 IVI_GPS_Long_Dir_Sta 3;
BA_ "GenSigStartValue" SG_ 1173 IVI_GPS_Long_Dir_Sta 3;
BA_ "GenSigRoutingTimeoutValue_String" SG_ 1173 IVI_GPS_Long_Dir_Sta "0x3";
BA_ "GenSigInactiveValue" SG_ 1173 IVI_GPS_Long_Dir_Sta 3;
BA_ "GenSigRoutingTimeoutValue" SG_ 1173 IVI_GPS_Long_Dir_Sta 3;
BA_ "GenSigInvalidValue" SG_ 1173 IVI_GPS_Lat_Dir_Sta 3;
BA_ "GenSigStartValue" SG_ 1173 IVI_GPS_Lat_Dir_Sta 3;
BA_ "GenSigRoutingTimeoutValue_String" SG_ 1173 IVI_GPS_Lat_Dir_Sta "0x3";
BA_ "GenSigInactiveValue" SG_ 1173 IVI_GPS_Lat_Dir_Sta 3;
BA_ "GenSigRoutingTimeoutValue" SG_ 1173 IVI_GPS_Lat_Dir_Sta 3;
BA_ "GenSigInvalidValue" SG_ 1173 IVI_IC_Brightness_Sta 127;
BA_ "GenSigStartValue" SG_ 1173 IVI_IC_Brightness_Sta 127;
BA_ "GenSigRoutingTimeoutValue_String" SG_ 1173 IVI_IC_Brightness_Sta "0x7F";
BA_ "GenSigInactiveValue" SG_ 1173 IVI_IC_Brightness_Sta 127;
BA_ "GenSigRoutingTimeoutValue" SG_ 1173 IVI_IC_Brightness_Sta 127;
BA_ "GenSigSendType" SG_ 1173 IVI_IC_Brightness_Sta 3;
BA_ "GenSigRoutingTimeoutValue_String" SG_ 1173 IVI_Off_Road_Mode_Sta "0x0";
BA_ "GenSigRoutingTimeoutValue_String" SG_ 1173 IVI_DMS_NoDriverDetected_Sta "0x0";
BA_ "GenSigSendType" SG_ 1173 IVI_DMS_NoDriverDetected_Sta 3;
BA_ "GenSigSendType" SG_ 1173 IVI_DMS_Faceblocked_Sta 3;
BA_ "GenSigSendType" SG_ 1282 NM_Meter_Node_ID 7;
BA_ "GenSigSendType" SG_ 1282 NM_Meter_PNI 7;
BA_ "GenSigSendType" SG_ 1282 NM_Meter_Active_WU 7;
BA_ "GenSigSendType" SG_ 1282 NM_Meter_CSB 7;
BA_ "GenSigSendType" SG_ 1282 NM_Meter_Rpt_Msg_Req 7;
BA_ "GenSigSendType" SG_ 1282 NM_Meter_ERROR_State 7;
BA_ "GenSigSendType" SG_ 1312 NM_IVI_Node_ID 7;
BA_ "GenSigSendType" SG_ 1312 NM_IVI_PNI 7;
BA_ "GenSigSendType" SG_ 1312 NM_IVI_Active_WU 7;
BA_ "GenSigSendType" SG_ 1312 NM_IVI_CSB 7;
BA_ "GenSigSendType" SG_ 1312 NM_IVI_Rpt_Msg_Req 7;
BA_ "GenSigSendType" SG_ 1312 NM_IVI_ERROR_State 7;
BA_ "GenSigSendType" SG_ 1330 NM_HMI_Node_ID 7;
BA_ "GenSigSendType" SG_ 1330 NM_HMI_PNI 7;
BA_ "GenSigSendType" SG_ 1330 NM_HMI_Active_WU 7;
BA_ "GenSigSendType" SG_ 1330 NM_HMI_CSB 7;
BA_ "GenSigSendType" SG_ 1330 NM_HMI_Rpt_Msg_Req 7;
BA_ "GenSigSendType" SG_ 1330 NM_HMI_ERROR_State 7;
BA_ "GenSigSendType" SG_ 1538 DiagRespFromMeter 3;
BA_ "GenSigSendType" SG_ 1568 DiagRespFromIVI 3;
BA_ "GenSigSendType" SG_ 1586 DiagRespFromHMI 3;
BA_ "GenSigInvalidValue" SG_ 1184 Telltale_ABSWarning 3;
BA_ "GenSigSendType" SG_ 1184 Telltale_ABSWarning 3;
BA_ "GenSigInvalidValue" SG_ 1184 Telltale_BatteryChargeWarning 3;
BA_ "GenSigSendType" SG_ 1184 Telltale_BatteryChargeWarning 3;
BA_ "GenSigInvalidValue" SG_ 1184 Telltale_EDriveSystem 3;
BA_ "GenSigSendType" SG_ 1184 Telltale_EDriveSystem 3;
BA_ "GenSigInvalidValue" SG_ 1184 Telltale_EPBError 3;
BA_ "GenSigSendType" SG_ 1184 Telltale_EPBError 3;
BA_ "GenSigInvalidValue" SG_ 1184 Telltale_HVBatteryFault 3;
BA_ "GenSigSendType" SG_ 1184 Telltale_HVBatteryFault 3;
BA_ "GenSigInvalidValue" SG_ 1184 Telltale_ParkBrakeWarning 3;
BA_ "GenSigSendType" SG_ 1184 Telltale_ParkBrakeWarning 3;
BA_ "GenSigInvalidValue" SG_ 1184 Telltale_Powerlimitation 3;
BA_ "GenSigSendType" SG_ 1184 Telltale_Powerlimitation 3;
BA_ "GenSigInvalidValue" SG_ 1184 Telltale_SteeringWarning 3;
BA_ "GenSigSendType" SG_ 1184 Telltale_SteeringWarning 3;
BA_ "GenSigInvalidValue" SG_ 1184 Telltale_TCSIndicator 3;
BA_ "GenSigSendType" SG_ 1184 Telltale_TCSIndicator 3;
BA_ "GenSigSendType" SG_ 1184 Telltale_EBMErrSta 3;
BA_ "GenSigSendType" SG_ 857 DSEAT_heater_sta 3;
BA_ "GenSigSendType" SG_ 857 DSEAT_Mode 3;
BA_ "GenSigSendType" SG_ 857 DSEAT_Vent_Sta 3;
BA_ "GenSigSendType" SG_ 857 PSEAT_heater_sta 3;
BA_ "GenSigSendType" SG_ 857 PSEAT_Mode 3;
BA_ "GenSigSendType" SG_ 857 PSEAT_Vent_Sta 3;
BA_ "GenSigSendType" SG_ 857 DSEAT_Anti_Sta 3;
BA_ "GenSigSendType" SG_ 857 DSEAT_EntryFun_Sta 3;
BA_ "GenSigSendType" SG_ 857 DSEAT_Error_Sta 3;
BA_ "DataCenterDataType" SG_ 857 DSEAT_Error_Sta "Varchar(30)";
BA_ "GenSigSendType" SG_ 857 PSEAT_Error_Sta 3;
BA_ "GenSigSendType" SG_ 857 PTG_Active_Sta 3;
BA_ "DataCenterDataType" SG_ 857 PTG_Active_Sta "Varchar(20)";
BA_ "GenSigInvalidValue" SG_ 857 PTG_Sys_Sta 3;
BA_ "GenSigStartValue" SG_ 857 PTG_Sys_Sta 3;
BA_ "GenSigRoutingTimeoutValue_String" SG_ 857 PTG_Sys_Sta "0x3";
BA_ "GenSigInactiveValue" SG_ 857 PTG_Sys_Sta 3;
BA_ "GenSigRoutingTimeoutValue" SG_ 857 PTG_Sys_Sta 3;
BA_ "GenSigSendType" SG_ 857 PTG_Sys_Sta 3;
BA_ "DataCenterDataType" SG_ 857 PTG_Sys_Sta "Varchar(20)";
BA_ "GenSigSendType" SG_ 857 PTG_AutoStaus 3;
BA_ "GenSigSendType" SG_ 857 PTG_Exist 3;
BA_ "DataCenterDataType" SG_ 857 PTG_Exist "Varchar(10)";
BA_ "GenSigSendType" SG_ 857 PTG_Is_Set_Height 3;
BA_ "GenSigInvalidValue" SG_ 857 Rr_TMSpd_Nidec 65535;
BA_ "GenSigStartValue" SG_ 857 Rr_TMSpd_Nidec 17000;
BA_ "GenSigRoutingTimeoutValue_String" SG_ 857 Rr_TMSpd_Nidec "0xFFFF";
BA_ "GenSigInactiveValue" SG_ 857 Rr_TMSpd_Nidec 65535;
BA_ "GenSigRoutingTimeoutValue" SG_ 857 Rr_TMSpd_Nidec 65535;
BA_ "DataCenterDataType" SG_ 857 Rr_TMSpd_Nidec "INT(5)";
BA_ "GenSigInvalidValue" SG_ 857 Fr_TMSpd_Nidec 65535;
BA_ "GenSigStartValue" SG_ 857 Fr_TMSpd_Nidec 17000;
BA_ "GenSigRoutingTimeoutValue_String" SG_ 857 Fr_TMSpd_Nidec "0xFFFF";
BA_ "GenSigInactiveValue" SG_ 857 Fr_TMSpd_Nidec 65535;
BA_ "GenSigRoutingTimeoutValue" SG_ 857 Fr_TMSpd_Nidec 65535;
BA_ "GenSigInvalidValue" SG_ 857 Fr_EDURealTMTq_Nidec 4095;
BA_ "GenSigRoutingTimeoutValue_String" SG_ 857 Fr_EDURealTMTq_Nidec "0xFFF";
BA_ "GenSigInactiveValue" SG_ 857 Fr_EDURealTMTq_Nidec 4095;
BA_ "GenSigRoutingTimeoutValue" SG_ 857 Fr_EDURealTMTq_Nidec 4095;
BA_ "GenSigInvalidValue" SG_ 857 Fr_MotorAvailTq_Nidec 4095;
BA_ "GenSigRoutingTimeoutValue_String" SG_ 857 Fr_MotorAvailTq_Nidec "0xFFF";
BA_ "GenSigInactiveValue" SG_ 857 Fr_MotorAvailTq_Nidec 4095;
BA_ "GenSigRoutingTimeoutValue" SG_ 857 Fr_MotorAvailTq_Nidec 4095;
BA_ "GenSigInvalidValue" SG_ 857 Rr_EDURealTMTq_Nidec 4095;
BA_ "GenSigStartValue" SG_ 857 Rr_EDURealTMTq_Nidec 1022;
BA_ "GenSigRoutingTimeoutValue_String" SG_ 857 Rr_EDURealTMTq_Nidec "0xFFF";
BA_ "GenSigInactiveValue" SG_ 857 Rr_EDURealTMTq_Nidec 4095;
BA_ "GenSigRoutingTimeoutValue" SG_ 857 Rr_EDURealTMTq_Nidec 4095;
BA_ "DataCenterDataType" SG_ 857 Rr_EDURealTMTq_Nidec "INT(4)";
BA_ "GenSigInvalidValue" SG_ 857 Rr_MotorAvailTq_Nidec 4095;
BA_ "GenSigRoutingTimeoutValue_String" SG_ 857 Rr_MotorAvailTq_Nidec "0xFFF";
BA_ "GenSigInactiveValue" SG_ 857 Rr_MotorAvailTq_Nidec 4095;
BA_ "GenSigRoutingTimeoutValue" SG_ 857 Rr_MotorAvailTq_Nidec 4095;
BA_ "GenSigInvalidValue" SG_ 857 Fr_MCUTemp_Nidec 511;
BA_ "GenSigRoutingTimeoutValue_String" SG_ 857 Fr_MCUTemp_Nidec "0x1FF";
BA_ "GenSigInactiveValue" SG_ 857 Fr_MCUTemp_Nidec 511;
BA_ "GenSigRoutingTimeoutValue" SG_ 857 Fr_MCUTemp_Nidec 511;
BA_ "GenSigInvalidValue" SG_ 857 Fr_TMTemp_Nidec 511;
BA_ "GenSigRoutingTimeoutValue_String" SG_ 857 Fr_TMTemp_Nidec "0x1FF";
BA_ "GenSigInactiveValue" SG_ 857 Fr_TMTemp_Nidec 511;
BA_ "GenSigRoutingTimeoutValue" SG_ 857 Fr_TMTemp_Nidec 511;
BA_ "GenSigInvalidValue" SG_ 857 Rr_MCUTemp_Nidec 511;
BA_ "GenSigRoutingTimeoutValue_String" SG_ 857 Rr_MCUTemp_Nidec "0x1FF";
BA_ "GenSigInactiveValue" SG_ 857 Rr_MCUTemp_Nidec 511;
BA_ "GenSigRoutingTimeoutValue" SG_ 857 Rr_MCUTemp_Nidec 511;
BA_ "GenSigInvalidValue" SG_ 857 Rr_TMTemp_Nidec 511;
BA_ "GenSigRoutingTimeoutValue_String" SG_ 857 Rr_TMTemp_Nidec "0x1FF";
BA_ "GenSigInactiveValue" SG_ 857 Rr_TMTemp_Nidec 511;
BA_ "GenSigRoutingTimeoutValue" SG_ 857 Rr_TMTemp_Nidec 511;
BA_ "GenSigInvalidValue" SG_ 857 Fr_MCUTempWarn_Nidec 3;
BA_ "GenSigStartValue" SG_ 857 Fr_MCUTempWarn_Nidec 3;
BA_ "GenSigRoutingTimeoutValue_String" SG_ 857 Fr_MCUTempWarn_Nidec "0x3";
BA_ "GenSigInactiveValue" SG_ 857 Fr_MCUTempWarn_Nidec 3;
BA_ "GenSigRoutingTimeoutValue" SG_ 857 Fr_MCUTempWarn_Nidec 3;
BA_ "GenSigInvalidValue" SG_ 857 Fr_TMTempWarn_Nidec 3;
BA_ "GenSigStartValue" SG_ 857 Fr_TMTempWarn_Nidec 3;
BA_ "GenSigRoutingTimeoutValue_String" SG_ 857 Fr_TMTempWarn_Nidec "0x3";
BA_ "GenSigInactiveValue" SG_ 857 Fr_TMTempWarn_Nidec 3;
BA_ "GenSigRoutingTimeoutValue" SG_ 857 Fr_TMTempWarn_Nidec 3;
BA_ "GenSigInvalidValue" SG_ 857 Rr_MCUTempWarn_Nidec 3;
BA_ "GenSigStartValue" SG_ 857 Rr_MCUTempWarn_Nidec 3;
BA_ "GenSigRoutingTimeoutValue_String" SG_ 857 Rr_MCUTempWarn_Nidec "0x3";
BA_ "GenSigInactiveValue" SG_ 857 Rr_MCUTempWarn_Nidec 3;
BA_ "GenSigRoutingTimeoutValue" SG_ 857 Rr_MCUTempWarn_Nidec 3;
BA_ "DataCenterDataType" SG_ 857 Rr_MCUTempWarn_Nidec "Varchar(10)";
BA_ "GenSigInvalidValue" SG_ 857 Rr_TMTempWarn_Nidec 3;
BA_ "GenSigStartValue" SG_ 857 Rr_TMTempWarn_Nidec 3;
BA_ "GenSigRoutingTimeoutValue_String" SG_ 857 Rr_TMTempWarn_Nidec "0x3";
BA_ "GenSigInactiveValue" SG_ 857 Rr_TMTempWarn_Nidec 3;
BA_ "GenSigRoutingTimeoutValue" SG_ 857 Rr_TMTempWarn_Nidec 3;
BA_ "DataCenterDataType" SG_ 857 Rr_TMTempWarn_Nidec "Varchar(10)";
BA_ "GenSigInvalidValue" SG_ 857 L_Drv_Val_Wdw_Opened 127;
BA_ "GenSigStartValue" SG_ 857 L_Drv_Val_Wdw_Opened 127;
BA_ "GenSigRoutingTimeoutValue_String" SG_ 857 L_Drv_Val_Wdw_Opened "0x7F";
BA_ "GenSigInactiveValue" SG_ 857 L_Drv_Val_Wdw_Opened 127;
BA_ "GenSigRoutingTimeoutValue" SG_ 857 L_Drv_Val_Wdw_Opened 127;
BA_ "DataCenterDataType" SG_ 857 L_Drv_Val_Wdw_Opened "Varchar(10)";
BA_ "GenSigInvalidValue" SG_ 857 L_Pas_Val_Wdw_Opened 127;
BA_ "GenSigStartValue" SG_ 857 L_Pas_Val_Wdw_Opened 127;
BA_ "GenSigRoutingTimeoutValue_String" SG_ 857 L_Pas_Val_Wdw_Opened "0x7F";
BA_ "GenSigInactiveValue" SG_ 857 L_Pas_Val_Wdw_Opened 127;
BA_ "GenSigRoutingTimeoutValue" SG_ 857 L_Pas_Val_Wdw_Opened 127;
BA_ "DataCenterDataType" SG_ 857 L_Pas_Val_Wdw_Opened "Varchar(10)";
BA_ "GenSigInvalidValue" SG_ 857 L_RLD_Val_Wdw_Opened 127;
BA_ "GenSigStartValue" SG_ 857 L_RLD_Val_Wdw_Opened 127;
BA_ "GenSigRoutingTimeoutValue_String" SG_ 857 L_RLD_Val_Wdw_Opened "0x7F";
BA_ "GenSigInactiveValue" SG_ 857 L_RLD_Val_Wdw_Opened 127;
BA_ "GenSigRoutingTimeoutValue" SG_ 857 L_RLD_Val_Wdw_Opened 127;
BA_ "DataCenterDataType" SG_ 857 L_RLD_Val_Wdw_Opened "Varchar(10)";
BA_ "GenSigInvalidValue" SG_ 857 L_RRD_Val_Wdw_Opened 127;
BA_ "GenSigStartValue" SG_ 857 L_RRD_Val_Wdw_Opened 127;
BA_ "GenSigRoutingTimeoutValue_String" SG_ 857 L_RRD_Val_Wdw_Opened "0x7F";
BA_ "GenSigInactiveValue" SG_ 857 L_RRD_Val_Wdw_Opened 127;
BA_ "GenSigRoutingTimeoutValue" SG_ 857 L_RRD_Val_Wdw_Opened 127;
BA_ "DataCenterDataType" SG_ 857 L_RRD_Val_Wdw_Opened "Varchar(10)";
BA_ "GenSigRoutingTimeoutValue_String" SG_ 857 FAPWL_01_LIN_Response_Error "0x1";
BA_ "GenSigRoutingTimeoutValue" SG_ 857 FAPWL_01_LIN_Response_Error 1;
BA_ "GenSigSendType" SG_ 857 FAPWL_01_LIN_Response_Error 3;
BA_ "GenSigSendType" SG_ 857 L_Drv_Motor_Relay_Error 3;
BA_ "GenSigSendType" SG_ 857 L_Drv_Motor_Ripple_Error 3;
BA_ "GenSigSendType" SG_ 857 L_Pas_Motor_Relay_Error 3;
BA_ "GenSigSendType" SG_ 857 L_Pas_Motor_Ripple_Error 3;
BA_ "GenSigSendType" SG_ 857 L_RLD_Motor_Relay_Error 3;
BA_ "GenSigSendType" SG_ 857 L_RLD_Motor_Ripple_Error 3;
BA_ "GenSigSendType" SG_ 857 L_RRD_Motor_Relay_Error 3;
BA_ "GenSigSendType" SG_ 857 L_RRD_Motor_Ripple_Error 3;
BA_ "GenSigRoutingTimeoutValue_String" SG_ 857 RAPWL_01_LIN_Response_Error "0x1";
BA_ "GenSigRoutingTimeoutValue" SG_ 857 RAPWL_01_LIN_Response_Error 1;
BA_ "GenSigSendType" SG_ 857 RAPWL_01_LIN_Response_Error 3;
BA_ "GenSigInvalidValue" SG_ 855 Rr_TMSpd 65535;
BA_ "GenSigStartValue" SG_ 855 Rr_TMSpd 18000;
BA_ "GenSigRoutingTimeoutValue_String" SG_ 855 Rr_TMSpd "0xFFFF";
BA_ "GenSigInactiveValue" SG_ 855 Rr_TMSpd 65535;
BA_ "GenSigRoutingTimeoutValue" SG_ 855 Rr_TMSpd 65535;
BA_ "DataCenterDataType" SG_ 855 Rr_TMSpd "INT(5)";
BA_ "GenSigInvalidValue" SG_ 855 Fr_TMSpd 65535;
BA_ "GenSigStartValue" SG_ 855 Fr_TMSpd 18000;
BA_ "GenSigRoutingTimeoutValue_String" SG_ 855 Fr_TMSpd "0xFFFF";
BA_ "GenSigInactiveValue" SG_ 855 Fr_TMSpd 65535;
BA_ "GenSigRoutingTimeoutValue" SG_ 855 Fr_TMSpd 65535;
BA_ "GenSigInvalidValue" SG_ 855 Fr_EDURealTMTq 65535;
BA_ "GenSigStartValue" SG_ 855 Fr_EDURealTMTq 10220;
BA_ "GenSigRoutingTimeoutValue_String" SG_ 855 Fr_EDURealTMTq "0xFFFF";
BA_ "GenSigInactiveValue" SG_ 855 Fr_EDURealTMTq 65535;
BA_ "GenSigRoutingTimeoutValue" SG_ 855 Fr_EDURealTMTq 65535;
BA_ "GenSigInvalidValue" SG_ 855 Fr_MotorAvailTq 4095;
BA_ "GenSigRoutingTimeoutValue_String" SG_ 855 Fr_MotorAvailTq "0xFFF";
BA_ "GenSigInactiveValue" SG_ 855 Fr_MotorAvailTq 4095;
BA_ "GenSigRoutingTimeoutValue" SG_ 855 Fr_MotorAvailTq 4095;
BA_ "GenSigInvalidValue" SG_ 855 Rr_EDURealTMTq 65535;
BA_ "GenSigStartValue" SG_ 855 Rr_EDURealTMTq 10220;
BA_ "GenSigRoutingTimeoutValue_String" SG_ 855 Rr_EDURealTMTq "0xFFFF";
BA_ "GenSigInactiveValue" SG_ 855 Rr_EDURealTMTq 65535;
BA_ "GenSigRoutingTimeoutValue" SG_ 855 Rr_EDURealTMTq 65535;
BA_ "DataCenterDataType" SG_ 855 Rr_EDURealTMTq "INT(4)";
BA_ "GenSigInvalidValue" SG_ 855 Rr_MotorAvailTq 4095;
BA_ "GenSigRoutingTimeoutValue_String" SG_ 855 Rr_MotorAvailTq "0xFFF";
BA_ "GenSigInactiveValue" SG_ 855 Rr_MotorAvailTq 4095;
BA_ "GenSigRoutingTimeoutValue" SG_ 855 Rr_MotorAvailTq 4095;
BA_ "GenSigInvalidValue" SG_ 855 Fr_MCUTemp 511;
BA_ "GenSigRoutingTimeoutValue_String" SG_ 855 Fr_MCUTemp "0x1FF";
BA_ "GenSigInactiveValue" SG_ 855 Fr_MCUTemp 511;
BA_ "GenSigRoutingTimeoutValue" SG_ 855 Fr_MCUTemp 511;
BA_ "GenSigInvalidValue" SG_ 855 Fr_TMTemp 511;
BA_ "GenSigRoutingTimeoutValue_String" SG_ 855 Fr_TMTemp "0x1FF";
BA_ "GenSigInactiveValue" SG_ 855 Fr_TMTemp 511;
BA_ "GenSigRoutingTimeoutValue" SG_ 855 Fr_TMTemp 511;
BA_ "GenSigInvalidValue" SG_ 855 Rr_MCUTemp 511;
BA_ "GenSigRoutingTimeoutValue_String" SG_ 855 Rr_MCUTemp "0x1FF";
BA_ "GenSigInactiveValue" SG_ 855 Rr_MCUTemp 511;
BA_ "GenSigRoutingTimeoutValue" SG_ 855 Rr_MCUTemp 511;
BA_ "GenSigInvalidValue" SG_ 855 Rr_TMTemp 511;
BA_ "GenSigRoutingTimeoutValue_String" SG_ 855 Rr_TMTemp "0x1FF";
BA_ "GenSigInactiveValue" SG_ 855 Rr_TMTemp 511;
BA_ "GenSigRoutingTimeoutValue" SG_ 855 Rr_TMTemp 511;
BA_ "GenSigSendType" SG_ 855 BD_DSEAT_Mode_Sta 3;
BA_ "GenSigSendType" SG_ 855 BD_DSEAT_Vent_Sta 3;
BA_ "GenSigSendType" SG_ 855 BP_PTG_Active_Sta 3;
BA_ "GenSigSendType" SG_ 855 BP_PSEAT_Mode_Sta 3;
BA_ "GenSigSendType" SG_ 855 BP_PSEAT_Vent_Sta 3;
BA_ "GenSigInvalidValue" SG_ 855 Fr_MCUTempWarn 3;
BA_ "GenSigStartValue" SG_ 855 Fr_MCUTempWarn 3;
BA_ "GenSigRoutingTimeoutValue_String" SG_ 855 Fr_MCUTempWarn "0x3";
BA_ "GenSigInactiveValue" SG_ 855 Fr_MCUTempWarn 3;
BA_ "GenSigRoutingTimeoutValue" SG_ 855 Fr_MCUTempWarn 3;
BA_ "GenSigInvalidValue" SG_ 855 Fr_TMTempWarn 3;
BA_ "GenSigStartValue" SG_ 855 Fr_TMTempWarn 3;
BA_ "GenSigRoutingTimeoutValue_String" SG_ 855 Fr_TMTempWarn "0x3";
BA_ "GenSigInactiveValue" SG_ 855 Fr_TMTempWarn 3;
BA_ "GenSigRoutingTimeoutValue" SG_ 855 Fr_TMTempWarn 3;
BA_ "GenSigInvalidValue" SG_ 855 Rr_MCUTempWarn 3;
BA_ "GenSigStartValue" SG_ 855 Rr_MCUTempWarn 3;
BA_ "GenSigRoutingTimeoutValue_String" SG_ 855 Rr_MCUTempWarn "0x3";
BA_ "GenSigInactiveValue" SG_ 855 Rr_MCUTempWarn 3;
BA_ "GenSigRoutingTimeoutValue" SG_ 855 Rr_MCUTempWarn 3;
BA_ "DataCenterDataType" SG_ 855 Rr_MCUTempWarn "Varchar(10)";
BA_ "GenSigInvalidValue" SG_ 855 Rr_TMTempWarn 3;
BA_ "GenSigStartValue" SG_ 855 Rr_TMTempWarn 3;
BA_ "GenSigRoutingTimeoutValue_String" SG_ 855 Rr_TMTempWarn "0x3";
BA_ "GenSigInactiveValue" SG_ 855 Rr_TMTempWarn 3;
BA_ "GenSigRoutingTimeoutValue" SG_ 855 Rr_TMTempWarn 3;
BA_ "DataCenterDataType" SG_ 855 Rr_TMTempWarn "Varchar(10)";
BA_ "GenSigInvalidValue" SG_ 855 BP_PTG_Sys_Sta 3;
BA_ "GenSigStartValue" SG_ 855 BP_PTG_Sys_Sta 3;
BA_ "GenSigRoutingTimeoutValue_String" SG_ 855 BP_PTG_Sys_Sta "0x3";
BA_ "GenSigRoutingTimeoutValue" SG_ 855 BP_PTG_Sys_Sta 3;
BA_ "GenSigSendType" SG_ 855 BP_PTG_Sys_Sta 3;
BA_ "GenSigSendType" SG_ 855 BD_DSEAT_Anti_Sta 3;
BA_ "GenSigSendType" SG_ 855 BD_DSEAT_EntryFun_Sta 3;
BA_ "GenSigSendType" SG_ 855 BD_DSEAT_Error_Sta 3;
BA_ "GenSigSendType" SG_ 855 BP_PTG_Exist_Sta 3;
BA_ "GenSigSendType" SG_ 855 BP_PTG_IsSetHeight_Sta 3;
BA_ "GenSigSendType" SG_ 855 BP_PSEAT_Error_Sta 3;
BA_ "GenSigSendType" SG_ 855 BD_DSEAT_heater_Sta 3;
BA_ "GenSigSendType" SG_ 855 BP_PSEAT_heater_Sta 3;
BA_ "GenSigInvalidValue" SG_ 855 MCU_B_R_LLCTempWarn_Sta 3;
BA_ "GenSigRoutingTimeoutValue_String" SG_ 855 MCU_B_R_LLCTempWarn_Sta "0x3";
BA_ "GenSigInactiveValue" SG_ 855 MCU_B_R_LLCTempWarn_Sta 3;
BA_ "GenSigRoutingTimeoutValue" SG_ 855 MCU_B_R_LLCTempWarn_Sta 3;
BA_ "GenSigSendType" SG_ 855 MCU_B_R_LLCTempWarn_Sta 3;
BA_ "GenSigInvalidValue" SG_ 855 MCU_B_F_LLCTempWarn_Sta 3;
BA_ "GenSigRoutingTimeoutValue_String" SG_ 855 MCU_B_F_LLCTempWarn_Sta "0x3";
BA_ "GenSigInactiveValue" SG_ 855 MCU_B_F_LLCTempWarn_Sta 3;
BA_ "GenSigRoutingTimeoutValue" SG_ 855 MCU_B_F_LLCTempWarn_Sta 3;
BA_ "GenSigSendType" SG_ 855 MCU_B_F_LLCTempWarn_Sta 3;
BA_ "GenSigSendType" SG_ 855 SWC2_L_DriveMode_Sta 3;
BA_ "GenSigSendType" SG_ 855 SWC2_L_Home_Sta 3;
BA_ "GenSigSendType" SG_ 855 SWC2_R_Customize_Sta 3;
BA_ "GenSigSendType" SG_ 855 SWC2_R_Left_Sta 3;
BA_ "GenSigSendType" SG_ 855 SWC2_R_PageSwitch_Sta 3;
BA_ "GenSigSendType" SG_ 855 SWC2_R_Right_Sta 3;
BA_ "GenSigSendType" SG_ 855 SWC2_R_ScrollDown_Sta 3;
BA_ "GenSigSendType" SG_ 855 SWC2_R_ScrollPress_Sta 3;
BA_ "GenSigSendType" SG_ 855 SWC2_R_ScrollUp_Sta 3;
BA_ "GenSigSendType" SG_ 855 SWC2_R_VR_Sta 3;
BA_ "GenSigSendType" SG_ 855 BP_SEAT_MLVent_Sta 3;
BA_ "GenSigSendType" SG_ 855 BP_SEAT_MRVent_Sta 3;
BA_ "GenSigSendType" SG_ 855 BP_SEAT_LVent_Sta 3;
BA_ "GenSigSendType" SG_ 855 BP_SEAT_RVent_Sta 3;
BA_ "GenSigRoutingTimeoutValue_String" SG_ 855 BD_DSEAT_MemSet_Sta "0x0";
BA_ "GenSigSendType" SG_ 855 BD_DSEAT_MemSet_Sta 3;
BA_ "GenSigRoutingTimeoutValue_String" SG_ 855 BD_DSEAT_StopKeepMove_Sta "0x3";
BA_ "GenSigRoutingTimeoutValue" SG_ 855 BD_DSEAT_StopKeepMove_Sta 3;
BA_ "GenSigSendType" SG_ 855 BD_DSEAT_StopKeepMove_Sta 3;
BA_ "GenSigInvalidValue" SG_ 855 FDC_BCM_WinLFOpened_Sta 127;
BA_ "GenSigStartValue" SG_ 855 FDC_BCM_WinLFOpened_Sta 127;
BA_ "GenSigRoutingTimeoutValue_String" SG_ 855 FDC_BCM_WinLFOpened_Sta "0x7F";
BA_ "GenSigInactiveValue" SG_ 855 FDC_BCM_WinLFOpened_Sta 127;
BA_ "GenSigRoutingTimeoutValue" SG_ 855 FDC_BCM_WinLFOpened_Sta 127;
BA_ "GenSigInvalidValue" SG_ 855 FDC_BCM_WinLROpened_Sta 127;
BA_ "GenSigStartValue" SG_ 855 FDC_BCM_WinLROpened_Sta 127;
BA_ "GenSigRoutingTimeoutValue_String" SG_ 855 FDC_BCM_WinLROpened_Sta "0x7F";
BA_ "GenSigInactiveValue" SG_ 855 FDC_BCM_WinLROpened_Sta 127;
BA_ "GenSigRoutingTimeoutValue" SG_ 855 FDC_BCM_WinLROpened_Sta 127;
BA_ "GenSigInvalidValue" SG_ 855 FDC_BCM_WinRFOpened_Sta 127;
BA_ "GenSigStartValue" SG_ 855 FDC_BCM_WinRFOpened_Sta 127;
BA_ "GenSigRoutingTimeoutValue_String" SG_ 855 FDC_BCM_WinRFOpened_Sta "0x7F";
BA_ "GenSigInactiveValue" SG_ 855 FDC_BCM_WinRFOpened_Sta 127;
BA_ "GenSigRoutingTimeoutValue" SG_ 855 FDC_BCM_WinRFOpened_Sta 127;
BA_ "GenSigInvalidValue" SG_ 855 FDC_BCM_WinRROpened_Sta 127;
BA_ "GenSigStartValue" SG_ 855 FDC_BCM_WinRROpened_Sta 127;
BA_ "GenSigRoutingTimeoutValue_String" SG_ 855 FDC_BCM_WinRROpened_Sta "0x7F";
BA_ "GenSigInactiveValue" SG_ 855 FDC_BCM_WinRROpened_Sta 127;
BA_ "GenSigRoutingTimeoutValue" SG_ 855 FDC_BCM_WinRROpened_Sta 127;
BA_ "GenSigRoutingTimeoutValue_String" SG_ 855 BD_Door_FHandleClose_Sta "0x0";
BA_ "GenSigSendType" SG_ 855 BD_Door_FHandleClose_Sta 3;
BA_ "GenSigRoutingTimeoutValue_String" SG_ 855 BD_Door_RHandleClose_Sta "0x0";
BA_ "GenSigSendType" SG_ 855 BD_Door_RHandleClose_Sta 3;
BA_ "GenSigRoutingTimeoutValue_String" SG_ 855 BP_Door_FHandleClose_Sta "0x0";
BA_ "GenSigSendType" SG_ 855 BP_Door_FHandleClose_Sta 3;
BA_ "GenSigRoutingTimeoutValue_String" SG_ 855 BP_Door_RHandleClose_Sta "0x0";
BA_ "GenSigSendType" SG_ 855 BP_Door_RHandleClose_Sta 3;
BA_ "GenSigInvalidValue" SG_ 552 AGS_Actual_Position 127;
BA_ "GenSigStartValue" SG_ 552 AGS_Actual_Position 127;
BA_ "GenSigRoutingTimeoutValue_String" SG_ 552 AGS_Actual_Position "0x7F";
BA_ "GenSigRoutingTimeoutValue" SG_ 552 AGS_Actual_Position 127;
BA_ "GenSigRoutingTimeoutValue_String" SG_ 552 AGS_LINResponse_Error "0x1";
BA_ "GenSigRoutingTimeoutValue" SG_ 552 AGS_LINResponse_Error 1;
BA_ "GenSigRoutingTimeoutValue_String" SG_ 552 ION_IONRespErr_Sta "0x1";
BA_ "GenSigRoutingTimeoutValue" SG_ 552 ION_IONRespErr_Sta 1;
BA_ "GenSigInvalidValue" SG_ 552 FGS_LifeHole3_Sta 511;
BA_ "GenSigRoutingTimeoutValue_String" SG_ 552 FGS_LifeHole3_Sta "0x1FF";
BA_ "GenSigRoutingTimeoutValue" SG_ 552 FGS_LifeHole3_Sta 511;
BA_ "GenSigInvalidValue" SG_ 552 FGS_LifeHole2_Sta 511;
BA_ "GenSigRoutingTimeoutValue_String" SG_ 552 FGS_LifeHole2_Sta "0x1FF";
BA_ "GenSigRoutingTimeoutValue" SG_ 552 FGS_LifeHole2_Sta 511;
BA_ "GenSigInvalidValue" SG_ 552 FGS_LifeHole1_Sta 511;
BA_ "GenSigRoutingTimeoutValue_String" SG_ 552 FGS_LifeHole1_Sta "0x1FF";
BA_ "GenSigRoutingTimeoutValue" SG_ 552 FGS_LifeHole1_Sta 511;
BA_ "GenSigInvalidValue" SG_ 552 FGS_Channel3TypeRsp_Sta 15;
BA_ "GenSigRoutingTimeoutValue_String" SG_ 552 FGS_Channel3TypeRsp_Sta "0xF";
BA_ "GenSigRoutingTimeoutValue" SG_ 552 FGS_Channel3TypeRsp_Sta 15;
BA_ "GenSigInvalidValue" SG_ 552 FGS_Channel2TypeRsp_Sta 15;
BA_ "GenSigRoutingTimeoutValue_String" SG_ 552 FGS_Channel2TypeRsp_Sta "0xF";
BA_ "GenSigRoutingTimeoutValue" SG_ 552 FGS_Channel2TypeRsp_Sta 15;
BA_ "GenSigInvalidValue" SG_ 552 FGS_Channel1TypeRsp_Sta 15;
BA_ "GenSigRoutingTimeoutValue_String" SG_ 552 FGS_Channel1TypeRsp_Sta "0xF";
BA_ "GenSigRoutingTimeoutValue" SG_ 552 FGS_Channel1TypeRsp_Sta 15;
BA_ "GenSigInvalidValue" SG_ 552 FGS_BlowerErr_Sta 1;
BA_ "GenSigRoutingTimeoutValue_String" SG_ 552 FGS_BlowerErr_Sta "0x1";
BA_ "GenSigRoutingTimeoutValue" SG_ 552 FGS_BlowerErr_Sta 1;
BA_ "GenSigInvalidValue" SG_ 552 FGS_IntenRsp_Sta 15;
BA_ "GenSigRoutingTimeoutValue_String" SG_ 552 FGS_IntenRsp_Sta "0xF";
BA_ "GenSigRoutingTimeoutValue" SG_ 552 FGS_IntenRsp_Sta 15;
BA_ "GenSigInvalidValue" SG_ 552 FGS_MotorErr_Sta 1;
BA_ "GenSigRoutingTimeoutValue_String" SG_ 552 FGS_MotorErr_Sta "0x1";
BA_ "GenSigRoutingTimeoutValue" SG_ 552 FGS_MotorErr_Sta 1;
BA_ "GenSigRoutingTimeoutValue_String" SG_ 552 FGS_TypRsp_Sta "0x0";
BA_ "GenSigInvalidValue" SG_ 552 FGS_LINResponseErr_Sta 1;
BA_ "GenSigRoutingTimeoutValue_String" SG_ 552 FGS_LINResponseErr_Sta "0x1";
BA_ "GenSigRoutingTimeoutValue" SG_ 552 FGS_LINResponseErr_Sta 1;
BA_ "GenSigRoutingTimeoutValue_String" SG_ 552 FGS_StsRsp_Sta "0x0";
BA_ "GenSigRoutingTimeoutValue_String" SG_ 552 FGS_Channel_Type_Sta "0x0";
BA_ "GenSigRoutingTimeoutValue_String" SG_ 552 FGS_Channel_Index_Sta "0x0";
BA_ "GenSigRoutingTimeoutValue_String" SG_ 1169 HMI_ACBtn_Cmd "0x0";
BA_ "GenSigSendType" SG_ 1169 HMI_ACBtn_Cmd 3;
BA_ "GenSigRoutingTimeoutValue_String" SG_ 1169 HMI_ACAutoBtn_Cmd "0x0";
BA_ "GenSigSendType" SG_ 1169 HMI_ACAutoBtn_Cmd 3;
BA_ "GenSigRoutingTimeoutValue_String" SG_ 1169 HMI_ACRecycleBtn_Cmd "0x0";
BA_ "GenSigSendType" SG_ 1169 HMI_ACRecycleBtn_Cmd 3;
BA_ "GenSigRoutingTimeoutValue_String" SG_ 1169 HMI_ACFrDefogBtn_Cmd "0x0";
BA_ "GenSigSendType" SG_ 1169 HMI_ACFrDefogBtn_Cmd 3;
BA_ "GenSigRoutingTimeoutValue_String" SG_ 1169 HMI_ZLSetTP_Cmd "0x0";
BA_ "GenSigSendType" SG_ 1169 HMI_ZLSetTP_Cmd 3;
BA_ "GenSigRoutingTimeoutValue_String" SG_ 1169 HMI_ZLSetTM_Cmd "0x0";
BA_ "GenSigSendType" SG_ 1169 HMI_ZLSetTM_Cmd 3;
BA_ "GenSigRoutingTimeoutValue_String" SG_ 1169 HMI_ZRSetTP_Cmd "0x0";
BA_ "GenSigSendType" SG_ 1169 HMI_ZRSetTP_Cmd 3;
BA_ "GenSigRoutingTimeoutValue_String" SG_ 1169 HMI_ZRSetTM_Cmd "0x0";
BA_ "GenSigSendType" SG_ 1169 HMI_ZRSetTM_Cmd 3;
BA_ "GenSigRoutingTimeoutValue_String" SG_ 1169 HMI_ACWindDirP_Cmd "0x0";
BA_ "GenSigSendType" SG_ 1169 HMI_ACWindDirP_Cmd 3;
BA_ "GenSigRoutingTimeoutValue_String" SG_ 1169 HMI_ACWindDirM_Cmd "0x0";
BA_ "GenSigSendType" SG_ 1169 HMI_ACWindDirM_Cmd 3;
BA_ "GenSigRoutingTimeoutValue_String" SG_ 1169 HMI_ACAirIntP_Cmd "0x0";
BA_ "GenSigSendType" SG_ 1169 HMI_ACAirIntP_Cmd 3;
BA_ "GenSigRoutingTimeoutValue_String" SG_ 1169 HMI_ACAirIntM_Cmd "0x0";
BA_ "GenSigSendType" SG_ 1169 HMI_ACAirIntM_Cmd 3;
BA_ "GenSigRoutingTimeoutValue_String" SG_ 1169 HMI_BCMPostDefogBtn_Cmd "0x0";
BA_ "GenSigSendType" SG_ 1169 HMI_BCMPostDefogBtn_Cmd 3;
BA_ "GenSigRoutingTimeoutValue_String" SG_ 1169 HMI_AutoInterLight_Cmd "0x0";
BA_ "GenSigSendType" SG_ 1169 HMI_AutoInterLight_Cmd 3;
BA_ "GenSigRoutingTimeoutValue_String" SG_ 1169 HMI_PSEAT_LevelDown_Cmd "0x0";
BA_ "GenSigSendType" SG_ 1169 HMI_PSEAT_LevelDown_Cmd 3;
BA_ "GenSigRoutingTimeoutValue_String" SG_ 1169 HMI_PSEAT_LevelUp_Cmd "0x0";
BA_ "GenSigSendType" SG_ 1169 HMI_PSEAT_LevelUp_Cmd 3;
BA_ "GenSigRoutingTimeoutValue_String" SG_ 1169 HMI_DSEAT_LevelDown_Cmd "0x0";
BA_ "GenSigSendType" SG_ 1169 HMI_DSEAT_LevelDown_Cmd 3;
BA_ "GenSigRoutingTimeoutValue_String" SG_ 1169 HMI_DSEAT_LevelUp_Cmd "0x0";
BA_ "GenSigSendType" SG_ 1169 HMI_DSEAT_LevelUp_Cmd 3;
BA_ "GenSigRoutingTimeoutValue_String" SG_ 1169 HMI_Function6_LevelDown_Cmd "0x0";
BA_ "GenSigSendType" SG_ 1169 HMI_Function6_LevelDown_Cmd 3;
BA_ "GenSigRoutingTimeoutValue_String" SG_ 1169 HMI_Function5_LevelDown_Cmd "0x0";
BA_ "GenSigSendType" SG_ 1169 HMI_Function5_LevelDown_Cmd 3;
BA_ "GenSigRoutingTimeoutValue_String" SG_ 1169 HMI_Function4_LevelDown_Cmd "0x0";
BA_ "GenSigSendType" SG_ 1169 HMI_Function4_LevelDown_Cmd 3;
BA_ "GenSigRoutingTimeoutValue_String" SG_ 1169 HMI_Function3_LevelDown_Cmd "0x0";
BA_ "GenSigSendType" SG_ 1169 HMI_Function3_LevelDown_Cmd 3;
BA_ "GenSigRoutingTimeoutValue_String" SG_ 1169 HMI_Function2_LevelDown_Cmd "0x0";
BA_ "GenSigSendType" SG_ 1169 HMI_Function2_LevelDown_Cmd 3;
BA_ "GenSigRoutingTimeoutValue_String" SG_ 1169 HMI_Function1_LevelDown_Cmd "0x0";
BA_ "GenSigSendType" SG_ 1169 HMI_Function1_LevelDown_Cmd 3;
BA_ "GenSigRoutingTimeoutValue_String" SG_ 1169 HMI_Function6_LevelUp_Cmd "0x0";
BA_ "GenSigSendType" SG_ 1169 HMI_Function6_LevelUp_Cmd 3;
BA_ "GenSigRoutingTimeoutValue_String" SG_ 1169 HMI_Function5_LevelUp_Cmd "0x0";
BA_ "GenSigSendType" SG_ 1169 HMI_Function5_LevelUp_Cmd 3;
BA_ "GenSigRoutingTimeoutValue_String" SG_ 1169 HMI_Function4_LevelUp_Cmd "0x0";
BA_ "GenSigSendType" SG_ 1169 HMI_Function4_LevelUp_Cmd 3;
BA_ "GenSigRoutingTimeoutValue_String" SG_ 1169 HMI_Function3_LevelUp_Cmd "0x0";
BA_ "GenSigSendType" SG_ 1169 HMI_Function3_LevelUp_Cmd 3;
BA_ "GenSigRoutingTimeoutValue_String" SG_ 1169 HMI_Function2_LevelUp_Cmd "0x0";
BA_ "GenSigSendType" SG_ 1169 HMI_Function2_LevelUp_Cmd 3;
BA_ "GenSigRoutingTimeoutValue_String" SG_ 1169 HMI_Function1_LevelUp_Cmd "0x0";
BA_ "GenSigSendType" SG_ 1169 HMI_Function1_LevelUp_Cmd 3;
BA_ "GenSigStartValue" SG_ 1175 IVI_CLBlower_Y_Sta 127;
BA_ "GenSigRoutingTimeoutValue_String" SG_ 1175 IVI_CLBlower_Y_Sta "0x7F";
BA_ "GenSigInactiveValue" SG_ 1175 IVI_CLBlower_Y_Sta 127;
BA_ "GenSigRoutingTimeoutValue" SG_ 1175 IVI_CLBlower_Y_Sta 127;
BA_ "GenSigStartValue" SG_ 1175 IVI_CLBlower_Z_Sta 127;
BA_ "GenSigRoutingTimeoutValue_String" SG_ 1175 IVI_CLBlower_Z_Sta "0x7F";
BA_ "GenSigInactiveValue" SG_ 1175 IVI_CLBlower_Z_Sta 127;
BA_ "GenSigRoutingTimeoutValue" SG_ 1175 IVI_CLBlower_Z_Sta 127;
BA_ "GenSigStartValue" SG_ 1175 IVI_CRBlower_Y_Sta 127;
BA_ "GenSigRoutingTimeoutValue_String" SG_ 1175 IVI_CRBlower_Y_Sta "0x7F";
BA_ "GenSigInactiveValue" SG_ 1175 IVI_CRBlower_Y_Sta 127;
BA_ "GenSigRoutingTimeoutValue" SG_ 1175 IVI_CRBlower_Y_Sta 127;
BA_ "GenSigStartValue" SG_ 1175 IVI_CRBlower_Z_Sta 127;
BA_ "GenSigRoutingTimeoutValue_String" SG_ 1175 IVI_CRBlower_Z_Sta "0x7F";
BA_ "GenSigInactiveValue" SG_ 1175 IVI_CRBlower_Z_Sta 127;
BA_ "GenSigRoutingTimeoutValue" SG_ 1175 IVI_CRBlower_Z_Sta 127;
BA_ "GenSigStartValue" SG_ 1175 IVI_LBlower_Y_Sta 127;
BA_ "GenSigRoutingTimeoutValue_String" SG_ 1175 IVI_LBlower_Y_Sta "0x7F";
BA_ "GenSigInactiveValue" SG_ 1175 IVI_LBlower_Y_Sta 127;
BA_ "GenSigRoutingTimeoutValue" SG_ 1175 IVI_LBlower_Y_Sta 127;
BA_ "GenSigStartValue" SG_ 1175 IVI_LBlower_Z_Sta 127;
BA_ "GenSigRoutingTimeoutValue_String" SG_ 1175 IVI_LBlower_Z_Sta "0x7F";
BA_ "GenSigInactiveValue" SG_ 1175 IVI_LBlower_Z_Sta 127;
BA_ "GenSigRoutingTimeoutValue" SG_ 1175 IVI_LBlower_Z_Sta 127;
BA_ "GenSigStartValue" SG_ 1175 IVI_RBlower_Y_Sta 127;
BA_ "GenSigRoutingTimeoutValue_String" SG_ 1175 IVI_RBlower_Y_Sta "0x7F";
BA_ "GenSigInactiveValue" SG_ 1175 IVI_RBlower_Y_Sta 127;
BA_ "GenSigRoutingTimeoutValue" SG_ 1175 IVI_RBlower_Y_Sta 127;
BA_ "GenSigStartValue" SG_ 1175 IVI_RBlower_Z_Sta 127;
BA_ "GenSigRoutingTimeoutValue_String" SG_ 1175 IVI_RBlower_Z_Sta "0x7F";
BA_ "GenSigInactiveValue" SG_ 1175 IVI_RBlower_Z_Sta 127;
BA_ "GenSigRoutingTimeoutValue" SG_ 1175 IVI_RBlower_Z_Sta 127;
BA_ "GenSigSendType" SG_ 1175 IVI_LSEATvent_Cmd 3;
BA_ "GenSigSendType" SG_ 1175 IVI_MLSEATvent_Cmd 3;
BA_ "GenSigSendType" SG_ 1175 IVI_MRSEATvent_Cmd 3;
BA_ "GenSigSendType" SG_ 1175 IVI_RSEATvent_Cmd 3;
BA_ "GenSigSendType" SG_ 1175 IVI_LBlower_Mode_Sta 3;
BA_ "GenSigSendType" SG_ 1175 IVI_MLFootLift_Cmd 3;
BA_ "GenSigSendType" SG_ 1175 IVI_MLRecliner_Cmd 3;
BA_ "GenSigSendType" SG_ 1175 IVI_MLSeatLift_Cmd 3;
BA_ "GenSigSendType" SG_ 1175 IVI_MLSlider_Cmd 3;
BA_ "GenSigSendType" SG_ 1175 IVI_MRFootLift_Cmd 3;
BA_ "GenSigSendType" SG_ 1175 IVI_MRRecliner_Cmd 3;
BA_ "GenSigSendType" SG_ 1175 IVI_MRSeatLift_Cmd 3;
BA_ "GenSigSendType" SG_ 1175 IVI_MRSlider_Cmd 3;
BA_ "GenSigSendType" SG_ 1175 IVI_RBlower_Mode_Sta 3;
BA_ "GenSigSendType" SG_ 1175 IVI_MLFMost_Cmd 3;
BA_ "GenSigSendType" SG_ 1175 IVI_MLNapMode_Cmd 3;
BA_ "GenSigSendType" SG_ 1175 IVI_MLRestore_Cmd 3;
BA_ "GenSigSendType" SG_ 1175 IVI_MLSldRestore_Cmd 3;
BA_ "GenSigSendType" SG_ 1175 IVI_MLZeroGravity_Cmd 3;
BA_ "GenSigSendType" SG_ 1175 IVI_MRFMost_Cmd 3;
BA_ "GenSigSendType" SG_ 1175 IVI_MRNapMode_Cmd 3;
BA_ "GenSigSendType" SG_ 1175 IVI_MRRestore_Cmd 3;
BA_ "GenSigSendType" SG_ 1175 IVI_MRSldRestore_Cmd 3;
BA_ "GenSigSendType" SG_ 1175 IVI_MRZeroGravity_Cmd 3;
BA_ "GenSigRoutingTimeoutValue_String" SG_ 1175 IVI_HMI_CustmiKEY_Sta "0x0";
BA_ "GenSigSendType" SG_ 1175 IVI_HMI_CustmiKEY_Sta 3;
BA_ "GenSigRoutingTimeoutValue_String" SG_ 1175 IVI_HMI_CustmiFun_Sta "0x0";
BA_ "GenSigSendType" SG_ 1175 IVI_HMI_CustmiFun_Sta 3;
BA_ "GenSigRoutingTimeoutValue_String" SG_ 1175 IVI_SOS_Call_Sta "0x0";
BA_ "GenSigSendType" SG_ 1175 IVI_SOS_Call_Sta 3;
BA_ "GenSigRoutingTimeoutValue_String" SG_ 1175 IVI_XWDMode_Cmd "0x0";
BA_ "GenSigSendType" SG_ 1175 IVI_XWDMode_Cmd 3;
BA_ "GenSigRoutingTimeoutValue_String" SG_ 1175 IVI_RollMod_atCarWash_Sta "0x0";
BA_ "GenSigSendType" SG_ 1175 IVI_RollMod_atCarWash_Sta 3;
BA_ "GenSigRoutingTimeoutValue_String" SG_ 1175 IVI_SnowMode_Cmd "0x0";
BA_ "GenSigSendType" SG_ 1175 IVI_SnowMode_Cmd 3;
BA_ "GenSigRoutingTimeoutValue_String" SG_ 1175 IVI_UserTakeOver_APS_Sta "0x0";
BA_ "GenSigSendType" SG_ 1175 IVI_UserTakeOver_APS_Sta 3;
BA_ "GenSigRoutingTimeoutValue_String" SG_ 1175 IVI_Zon1WindDirSWReq_Sta "0x0";
BA_ "GenSigSendType" SG_ 1175 IVI_Zon1WindDirSWReq_Sta 3;
BA_ "GenSigStartValue" SG_ 1175 IVI_PSDManualPower_Sta 1;
BA_ "GenSigRoutingTimeoutValue_String" SG_ 1175 IVI_PSDManualPower_Sta "0x1";
BA_ "GenSigRoutingTimeoutValue" SG_ 1175 IVI_PSDManualPower_Sta 1;
BA_ "GenSigSendType" SG_ 1175 IVI_PSDManualPower_Sta 3;
BA_ "GenSigRoutingTimeoutValue_String" SG_ 1175 IVI_RightPSDOpenClose_Cmd "0x0";
BA_ "GenSigSendType" SG_ 1175 IVI_RightPSDOpenClose_Cmd 3;
BA_ "GenSigRoutingTimeoutValue_String" SG_ 1175 IVI_LeftPSDOpenClose_Cmd "0x0";
BA_ "GenSigSendType" SG_ 1175 IVI_LeftPSDOpenClose_Cmd 3;
BA_ "GenSigSendType" SG_ 1687 DiagPhysReqToWCM 3;
BA_ "GenSigSendType" SG_ 1559 DiagRespFromWCM 3;
BA_ "GenSigSendType" SG_ 2015 DiagFuncReqOBD 3;
VAL_ 427 EPBSta 4 "Unknown" 3 "Releasing" 2 "Released" 1 "Applying" 0 "Applied";
VAL_ 427 EPBMsg 12 "Fasten driver seat belt" 11 "Press brake pedal to release Auto-Hold(Reserved)" 10 "Close driver side door(AVH)" 9 "EPB failed while AVH is activate" 8 "Please release park brake" 7 "Recalibration in progress" 6 "Depress Brake Pedal" 5 "Close driver-side door(DAR)" 4 "Rollerbench  Mode" 3 "Maintenance Mode" 2 "Slope Too Steep" 1 "Apply park brake" 0 "None";
VAL_ 427 EPBStaR 7 "Invalid" 6 "CompletelyReleased" 5 "Released" 4 "Releasing" 3 "Applying" 2 "HoldApplied" 1 "ParkApplied" 0 "Unknown";
VAL_ 427 EPBErrSta 2 "Diagnostic Mode" 1 "Failed" 0 "Normal";
VAL_ 427 EPBRLampSta 2 "Flash" 1 "Permanent" 0 "Off";
VAL_ 427 EPBExtReleaseAvail 1 "Available" 0 "Unavailable";
VAL_ 427 EPBExtApplyAvail 1 "Available" 0 "Unavailable";
VAL_ 427 EPBCarWashMode 1 "Car Wash mode" 0 "Not Car wash mode";
VAL_ 427 DOA_Sta 1 "Enabled" 0 "Disabled";
VAL_ 427 EPBStaL 7 "Invalid" 6 "CompletelyReleased" 5 "Released" 4 "Releasing" 3 "Applying" 2 "HoldApplied" 1 "ParkApplied" 0 "Unknown";
VAL_ 427 TakeOverReq 1 "On (Controlled by Backup EPB)" 0 "Off (Controlled by ESC)";
VAL_ 602 METER_KPH_Calcu 255 "Invalid";
VAL_ 602 METER_MPH_Calcu 255 "Invalid";
VAL_ 602 Spd_Crl_Mode 5 "invalid" 4 "ISA" 3 "LIM" 2 "CC" 1 "ACC" 0 "OFF";
VAL_ 602 Spd_Crl_Sta 1 "ON" 0 "OFF";
VAL_ 602 LEDlitWarnReq 1 "Warning request" 0 "No warning request";
VAL_ 602 Charge 1 "Disable (LED ON)" 0 "Enable (LED OFF)";
VAL_ 602 ParkBrake 1 "On" 0 "Off";
VAL_ 1168 VehACModReq 7 "Invalid" 6 "Signal not available" 5 "Reserved" 2 "Reserved" 1 "Economy mode" 0 "Standard";
VAL_ 1168 FCP_FrEvt_BtnACMaxReq 1 "Press" 0 "Release";
VAL_ 1168 FCP_FrEvt_BtnACReq 1 "Press" 0 "Release";
VAL_ 1168 FCP_FrEvt_BtnAutoReq 1 "Press" 0 "Release";
VAL_ 1168 FCP_MidEvt_BtnAutoReq 1 "Press" 0 "Release";
VAL_ 1168 FCP_FrEvt_BtnSyncReq 1 "Press" 0 "Release";
VAL_ 1168 OTA_DL_Req 1 "Press" 0 "Release";
VAL_ 1168 OTA_SuspendDL_Req 1 "Press" 0 "Release";
VAL_ 1168 OTA_UpdStart_Req 1 "Press" 0 "Release";
VAL_ 1168 IVI_OTA_Upd_Sta 3 "undefined" 2 "Completed" 1 "Uncompleted" 0 "No Update";
VAL_ 1168 OTA_CancelDL_Req 1 "Press" 0 "Release";
VAL_ 1168 SmartEco_Mode_SW 1 "ON" 0 "OFF";
VAL_ 1168 LINKtoDrive 1 "Press" 0 "Release";
VAL_ 1168 Upd_Countdown_Skip 1 "Press" 0 "Release";
VAL_ 1168 Upd_Countdown_Cancel 1 "Press" 0 "Release";
VAL_ 1168 AmbLightColorSet 65 "~0x7F undefined" 64 "No request" 63 "Red(255,0,0)" 62 "IndianRed(205,92,92)" 61 "LightCoral(240,128,128)" 60 "Tomato(255,99,71)" 59 "OrangeRed(255,69,0)" 58 "Coral(255,127,80)" 57 "LightSalmon(255,160,122)" 56 "DarkOrange(255,140,0)" 55 "Bisque(255,228,196)" 54 "NavajoWhite(255,222,173)" 53 "BlanchedAlmond(255,235,205)" 52 "Gold(255,215,0)" 51 "LemonChiffon(255,250,205)" 50 "Yellow(255,255,0)" 49 "LightYellow(255,255,224)" 48 "Ivory(255,255,240)" 47 "LightGoldenrodYellow(250,250,210)" 46 "Beige(245,245,220)" 45 "GreenYellow(73,255,47)" 44 "Chartreuse(127,255,0)" 43 "Lime(0,255,0)" 42 "LimeGreen(50,205,50)" 41 "PaleGreen(152,251,152)" 40 "LightGreen(144,238,144)" 39 "SeaGreen(46,139,87)" 38 "SpringGreen(60,179,113)" 37 "MediumSpringGreen(0,255,127)" 36 "MediumAquamarine(0,250,154)" 35 "Auqamarin(127,255,170)" 34 "MediumTurquoise(72,209,204)" 33 "DarkCyan(0,139,139)" 32 "DarkTurquoise(0,206,209)" 31 "Cyan(0,255,255)" 30 "PaleTurquoise(175,238,238)" 29 "DeepSkyBlue(0,191,255)" 28 "SkyBlue(135,206,235)" 27 "LightSkyBlue(135,206,250)" 26 "DoderBlue(30,144,255)" 25 "CornflowerBlue(100,149,237)" 24 "RoyalBlue(65,105,225)" 23 "Navy(0,0,128)" 22 "DarkBlue(0,0,139)" 21 "MidnightBlue(25,25,112)" 20 "MediumBlue(0,0,205)" 19 "Blue(0,0,255)" 18 "DarkSlateBlue(72,61,139)" 17 "SlateBlue(106,90,205)" 16 "MediumSlateBlue(123,104,238)" 15 "MediumPurple(147,112,219)" 14 "BlueViolet(138,43,226)" 13 "Indigo(75,0,130)" 12 "DarkOrchid(153,50,204)" 11 "DarkVoilet(148,0,211)" 10 "MediumOrchid(186,85,211)" 9 "DarkMagenta(139,0,139)" 8 "Magenta(255,0,255)" 7 "Violet(238,130,238)" 6 "Orchid(218,112,214)" 5 "MediumVioletRed(199,21,133)" 4 "DeepPink(255,20,147)" 3 "HotPink(255,105,180)" 2 "PaleVioletRed(219,112,147)" 1 "Crimson(220,20,60)" 0 "LightPink(255,182,193)";
VAL_ 1168 Sched_OTA_wake 1 "wake" 0 "standby";
VAL_ 1168 UserSet 7 "Rent" 6 "Guest" 5 "User5" 4 "User4" 3 "User3" 2 "User2" 1 "User1" 0 "No Request";
VAL_ 1168 AmbLightBrightnessSet 127 "Invalid" 102 "~0x7F undefined" 101 "No request" 100 "Max" 0 "Min";
VAL_ 1168 Sched_Chg_Day_Set 1 "Weekday" 0 "Everyday";
VAL_ 1168 Re_Radio_Sta 1 "ON" 0 "OFF";
VAL_ 1168 A2B_Node_sta 1 "Fail" 0 "Normal";
VAL_ 1168 IVI_Located_STA 3 "Not Used" 2 "3D fix" 1 "2D fix" 0 "No fix";
VAL_ 1168 OTA_CompNTFY_Pres 1 "Presented" 0 "Not presented";
VAL_ 1168 BrkAbn_GoReady_SW 1 "Press" 0 "Release";
VAL_ 1168 PW_CONTINUE_USE 1 "Press" 0 "Release";
VAL_ 1168 PW_CLOSE_IMD 1 "Press" 0 "Release";
VAL_ 1168 IVI_Time_Month 15 "Not Used" 14 "Not Used" 13 "Not Used" 0 "invalid";
VAL_ 1168 mFRD_link_Sta 1 "Fail" 0 "Normal";
VAL_ 1168 AmbLight_SW 1 "Press" 0 "Release";
VAL_ 1168 AmbLight_DimInDark_SW 1 "Press" 0 "Release";
VAL_ 1168 AmbLight_WlcmLight_SW 1 "Press" 0 "Release";
VAL_ 1168 AmbLigh_LowBatAlert_SW 1 "Press" 0 "Release";
VAL_ 1168 AmbLigh_SafetyAlert_SW 1 "Press" 0 "Release";
VAL_ 1168 OpenDrOpenWdo_SW 1 "Press" 0 "Release";
VAL_ 1168 IVI_LinkKey_Sta 15 "undefined" 14 "undefined" 13 "undefined" 12 "undefined" 11 "undefined" 10 "Link key 10" 9 "Link key 9" 8 "Link key 8" 7 "Link key 7" 6 "Link key 6" 5 "Link key 5" 4 "Link key 4" 3 "Link key 3" 2 "Link key 2" 1 "Link key 1" 0 "No Request";
VAL_ 1168 IVI_CreateAccReq_Sta 7 "undefined" 6 "undefined" 5 "Create User 5 account" 4 "Create User 4 account" 3 "Create User 3 account" 2 "Create User 2 account" 1 "Create User 1 account" 0 "No Request";
VAL_ 1168 IVI_DelAccReq_Sta 7 "undefined" 6 "undefined" 5 "Delete User 5 account" 4 "Delete User 4 account" 3 "Delete User 3 account" 2 "Delete User 2 account" 1 "Delete User 1 account" 0 "No Request";
VAL_ 1168 IVI_LinkAcc_Sta 7 "undefined" 6 "undefined" 5 "Link key to User 5" 4 "Link key to User 4" 3 "Link key to User 3" 2 "Link key to User 2" 1 "Link key to User 1" 0 "No Request";
VAL_ 1168 IVI_LinkAccReq_Sta 1 "Link account request" 0 "No Request";
VAL_ 1168 IVI_FrTrunk_UnlockReq_Sta 1 "Press" 0 "Release";
VAL_ 1168 IVI_CLWin_LockDoorSW_Sta 1 "Press" 0 "Release";
VAL_ 1168 IVI_Lock_SoundSW_Sta 1 "ON" 0 "OFF";
VAL_ 1168 IVI_SWC_VibMode_Sta 3 "High" 2 "Middle" 1 "Low" 0 "OFF";
VAL_ 1168 IVI_DMS_SW_Sta 1 "ON" 0 "OFF";
VAL_ 1168 IVI_AirRefresh_ByDMS_Sta 1 "Press" 0 "Release";
VAL_ 1168 IVI_QuickRefresh_Sta 1 "ON" 0 "OFF";
VAL_ 1168 IVI_HMI_Undefined_Sta 7 "Volume" 6 "FAN Level" 5 "Wind Direction" 4 "Auto Light/Dark Theme" 3 "NAVI" 2 "Interior Light" 1 "AVM/Rear View" 0 "A/C";
VAL_ 1168 IVI_AutoTheme_But_Sta 1 "ON" 0 "OFF";
VAL_ 1168 IVI_NAVI_Foreground_Sta 1 "Enable" 0 "Close";
VAL_ 1168 IVI_sigScreenReq_Sta 1 "Press" 0 "Release";
VAL_ 1168 IVI_DSEAT_anti_set_Sta 1 "Press" 0 "Release";
VAL_ 1168 IVI_MirrorFolded_SW_Sta 1 "Press" 0 "Release";
VAL_ 1168 IVI_WPTC_SW_Sta 1 "Press" 0 "Release";
VAL_ 1168 IVI_Driving_Lock_SW_Sta 1 "Press" 0 "Release";
VAL_ 1168 IVI_Stopping_Unlock_SW_Sta 1 "Press" 0 "Release";
VAL_ 1168 IVI_SilentChrg_Alert_Sta 1 "Show Pop up" 0 "None Pop up";
VAL_ 1168 IVI_WirelessCharge_Cmd 1 "ON" 0 "OFF";
VAL_ 1168 IVI_Theme_Sta 3 "Reserved" 2 "Reserved" 1 "Light" 0 "Dark";
VAL_ 1168 IVI_EPS_Force_Cmd 2 "High" 1 "Low" 0 "Standard";
VAL_ 1168 IVI_DSEAT_StopKeepMove_Sta 3 "Invalid" 2 "Keep Moving" 1 "Stop Moving" 0 "No Request";
VAL_ 1168 IVI_AutoWipHSpdSW_Cmd 1 "Press" 0 "Release";
VAL_ 1168 IVI_DSEAT_entryfun_set_Sta 1 "Press" 0 "Release";
VAL_ 1173 SOC_V2LLimit 15 "invalid" 14 "undefined" 13 "15%" 12 "80%" 11 "75%" 10 "70%" 9 "65%" 8 "60%" 7 "55%" 6 "50%" 5 "45%" 4 "40%" 3 "35%" 2 "30%" 1 "25%" 0 "20%";
VAL_ 1173 Perd_V2L 15 "8hr" 14 "7.5hr" 13 "7hr" 12 "6.5hr" 11 "6hr" 10 "5.5hr" 9 "5hr" 8 "4.5hr" 7 "4hr" 6 "3.5hr" 5 "3hr" 4 "2.5hr" 3 "2hr" 2 "1.5hr" 1 "1hr" 0 "0.5hr";
VAL_ 1173 IVI_Req_V2L 2 "Request Internal V2L" 1 "Request External V2L" 0 "No request";
VAL_ 1173 IVI_PTG_Open_Height 7 "Invalid" 6 "Invalid" 5 "No Request" 4 "Set by User" 3 "Lv3(80%)" 2 "Lv2(60%)" 1 "Lv1(40%)" 0 "Full Open";
VAL_ 1173 IVI_CreepSW_Req 1 "Press" 0 "Release";
VAL_ 1173 FalseNPrevent_SW 1 "ON" 0 "OFF";
VAL_ 1173 Approach_Unlock_SW 1 "Press" 0 "Release";
VAL_ 1173 Walkaway_Lock_SW 1 "Press" 0 "Release";
VAL_ 1173 Sched_Chg_limit 31 "invalid" 26 "~0x1E undefined" 0 "~0x19 50%~100%";
VAL_ 1173 Sched_Chg_Stop 1 "press" 0 "release";
VAL_ 1173 Sched_Chg_butt 1 "on" 0 "off";
VAL_ 1173 Sched_Chg_wake 1 "wake" 0 "standby";
VAL_ 1173 Sched_Chg_Start 1 "press" 0 "release";
VAL_ 1173 sigFaceReq 1 "press" 0 "relesase";
VAL_ 1173 sigFootReq 1 "press" 0 "relesase";
VAL_ 1173 METER_Malfunc_Sta 2 "Warning flash" 1 "Warning" 0 "Normal";
VAL_ 1173 IVI_Start_Chg_req 1 "press" 0 "relesase";
VAL_ 1173 L_RRD_ControlCommand 127 "No Request" 100 "Max" 0 "Min";
VAL_ 1173 IVI_Stop_Chg_req 1 "press" 0 "relesase";
VAL_ 1173 L_RLD_ControlCommand 127 "No Request" 100 "Max" 0 "Min";
VAL_ 1173 IVI_Unlock_Chg_req 1 "press" 0 "relesase";
VAL_ 1173 L_Pas_ControlCommand 127 "No Request" 100 "Max" 0 "Min";
VAL_ 1173 TPMS_Cali_Butt 1 "press" 0 "relesase";
VAL_ 1173 L_Drv_ControlCommand 127 "No Request" 100 "Max" 0 "Min";
VAL_ 1173 sigDfrstReq 1 "press" 0 "relesase";
VAL_ 1173 sigHvacFrontReq 1 "Press" 0 "Release";
VAL_ 1173 sigSetTempZon1Req 31 "Invalid";
VAL_ 1173 sigHvacReq 1 "ON" 0 "Off / Auto";
VAL_ 1173 sigRecircReq 1 "Press" 0 "Release";
VAL_ 1173 sigSetTempZon2Req 31 "Invalid";
VAL_ 1173 AEB_BUTT 2 "Invalid" 1 "Pressed" 0 "No request";
VAL_ 1173 sigAirIntenZon1Req 15 "Invalid" 14 "Reserved" 11 "Reserved" 10 "NOT set" 9 "Level 8" 8 "Level 7" 7 "Level 6" 6 "Level 5" 5 "Level 4" 4 "Level 3" 3 "Level 2" 2 "Level 1" 1 "OFF" 0 "NO display / No request";
VAL_ 1173 sigAirIntenZon3Req 15 "Invalid" 14 "Reserved" 11 "Reserved" 10 "NOT set" 9 "Level 8" 8 "Level 7" 7 "Level 6" 6 "Level 5" 5 "Level 4" 4 "Level 3" 3 "Level 2" 2 "Level 1" 1 "OFF" 0 "NO display / No request";
VAL_ 1173 sigWindDirZon3Req 7 "NOT Set / Reserved" 6 "All open" 5 "Face + Screen" 4 "DEFOG" 3 "Foot + Screen" 2 "Foot" 1 "Bilevel" 0 "FACE";
VAL_ 1173 BSDMute_BUTT 2 "Invalid" 1 "Pressed" 0 "No request";
VAL_ 1173 LDWMute_BUTT 2 "Invalid" 1 "Pressed" 0 "No request";
VAL_ 1173 ODAMute_BUTT 2 "Invalid" 1 "Pressed" 0 "No request";
VAL_ 1173 LKA_BUTT 2 "Invalid" 1 "Pressed" 0 "No request";
VAL_ 1173 FCWMute_BUTT 2 "Invalid" 1 "Pressed" 0 "No request";
VAL_ 1173 sigHvacRearReq 1 "Press" 0 "Release";
VAL_ 1173 IVI_Panel_Act 1 "PRESS" 0 "RELEASE";
VAL_ 1173 ESC_SW_Cmd 3 "Invaild" 2 "Undefined" 1 "Press" 0 "Release";
VAL_ 1173 Distance_unit 1 "mile" 0 "kilometer";
VAL_ 1173 Temperature_unit 1 "Fahrenheit" 0 "Celsius";
VAL_ 1173 NAVI_Speed_Limit_A 3 "invalid" 2 "Not Used" 1 "Applicable" 0 "Not Applicable";
VAL_ 1173 Time_system 1 "24h" 0 "12h";
VAL_ 1173 Pressure_unit 1 "BAR" 0 "PSI";
VAL_ 1173 TurnSwTimeSet 3 "No Request" 2 "7 times" 1 "5 times" 0 "3 times";
VAL_ 1173 IVI_Screen 63 "invalid" 62 "undefined" 29 "undefined" 28 "APS-all" 27 "AVM-all" 26 "Phone:incoming call popup:upper" 25 "Phone:dialer-upper" 24 "Phone:call history-upper" 23 "Phone:contacts-upper" 22 "System setting-Display-all" 21 "System setting-Sound-all" 20 "System setting-Cellular-all" 19 "System setting-Bluetooth-all" 18 "System setting-WiFi-all" 17 "System setting-account-all" 16 "Setting-About-all" 15 "Setting-Software-all" 14 "Setting-Service-all" 13 "Setting-Security-all" 12 "Setting-ADAS-all" 11 "Setting-Doors-all" 10 "Setting-Charging-all" 9 "Setting-Energy-all" 8 "Setting-Spotlight-all" 7 "Navi page-upper" 6 "3rd party app page-upper" 5 "Android auto-upper" 4 "Car play-upper" 3 "All app page-upper" 2 "DropDown menu-upper" 1 "DropDown menu-all" 0 "Home-up";
VAL_ 1173 Wifi_Reset 1 "reset VIG Wifi" 0 "No Request";
VAL_ 1173 CameraWrn 1 "Warnning enable" 0 "Off";
VAL_ 1173 User_p_upload 1 "upload" 0 "No Request";
VAL_ 1173 IVI_PW_Mode_Req 3 "No request" 2 "ECO" 1 "Sport" 0 "Normal";
VAL_ 1173 OFF_AC_MODE 7 "Invalid" 3 "CAMP" 2 "Pet" 1 "ON" 0 "OFF";
VAL_ 1173 NAVI_Cam_Dist_info 255 "Invalid" 150 "MAX" 0 "Min";
VAL_ 1173 Wifi_Sta_IVI_TBOX 9 "password error" 8 "Connection error" 6 "Internal Error" 5 "no signal" 4 "4 bar" 3 "3 bar" 2 "2 bar" 1 "1 bar" 0 "Invalid";
VAL_ 1173 NAVI_State 3 "NAVI error" 2 "NAVI good reception" 1 "NAVI no satellite" 0 "No NAVI";
VAL_ 1173 HeadLampSW 3 "OFF" 2 "Low beam" 1 "Postion lamp" 0 "AUTO";
VAL_ 1173 User_p_download 1 "download" 0 "No Request";
VAL_ 1173 MFRD_N_Bright_Req 127 "invalid" 100 "Max" 0 "Min";
VAL_ 1173 RFogLampSW 1 "ON" 0 "OFF";
VAL_ 1173 DSEAT_vent_req 7 "Not used" 6 "Not used" 5 "Not used" 4 "OFF" 3 "High" 2 "Middle" 1 "Low" 0 "No request";
VAL_ 1173 FFogLampSW 1 "ON" 0 "OFF";
VAL_ 1173 PSEAT_vent_req 4 "OFF" 3 "Vent3" 2 "Vent2" 1 "Vent1" 0 "No request";
VAL_ 1173 FS_Off_Sw 2 "invalid" 1 "ON" 0 "OFF";
VAL_ 1173 SLG_Sw 2 "invalid" 1 "ON" 0 "OFF";
VAL_ 1173 IVI_PTG_Sta_SW 2 "Invalid" 1 "Press" 0 "Release";
VAL_ 1173 IVI_PTG_Mode_SW 2 "Invalid" 1 "Press" 0 "No Request";
VAL_ 1173 SetUnlockSingle 1 "Press" 0 "Release";
VAL_ 1173 FollowMeSW 1 "Press" 0 "Release";
VAL_ 1173 TPMS_Res_Butt 1 "Press" 0 "Release";
VAL_ 1173 DSEAT_anti_set 1 "ON" 0 "OFF";
VAL_ 1173 DSEAT_entryfun_set 1 "ON" 0 "OFF";
VAL_ 1173 CAAS_Sw 2 "Invalid" 1 "Press" 0 "Release";
VAL_ 1173 LVDAMute_BUTT 2 "Invalid" 1 "Pressed" 0 "No request";
VAL_ 1173 IVI_Status 1 "Ready" 0 "Not ready";
VAL_ 1173 IVI_Night_Mode_Sta 1 "ON" 0 "OFF";
VAL_ 1173 IVI_RR_Def_Req 1 "Press" 0 "Release";
VAL_ 1173 IVI_WI_MAIN_SW 1 "ON" 0 "OFF";
VAL_ 1173 IVI_PTG_USSta_SW 1 "Press" 0 "Release";
VAL_ 1173 IVI_Mute_Sta 1 "Mute On" 0 "Mute Off";
VAL_ 1173 AVM_Err_STA 1 "Error" 0 "No Error";
VAL_ 1173 IVI_Trigger_req 1 "Request" 0 "No request";
VAL_ 1173 IVI_Pwroff_req 1 "Request" 0 "No request";
VAL_ 1173 RCTA_BUTT 2 "Invalid" 1 "Pressed" 0 "No request";
VAL_ 1173 Hood_Latch_SW 2 "invalid" 1 "Press" 0 "No Request";
VAL_ 1173 AVM_Parking_mode 8 "Forced to end" 7 "emergency stop" 6 "Left parking out" 5 "Right parking out" 4 "Left Perpendicular parking" 3 "Right Perpendicular parking" 2 "Left Parallel parking" 1 "Right Parallel parking" 0 "No message";
VAL_ 1173 SenstivityPosition 15 "not used" 14 "not used" 13 "not used" 12 "not used" 11 "not used" 10 "not used" 9 "not used" 8 "not used" 7 "not used" 6 "not used" 5 "not used" 4 "senstivity level-4" 3 "senstivity level-3" 2 "senstivity level-2" 1 "senstivity level-1" 0 "not used";
VAL_ 1173 NAVI_ForwardLinkLevel 15 "undefined" 14 "undefined" 13 "undefined" 12 "undefined" 11 "undefined" 10 "undefined" 9 "undefined" 8 "etc" 7 "shoulder" 6 "ramp" 5 "Freeway" 4 "Bus lane" 3 "Roundabout" 2 "City Lv2" 1 "City Lv1" 0 "NA";
VAL_ 1173 NAVI_LinkClass 15 "undefined" 14 "undefined" 13 "undefined" 12 "undefined" 11 "undefined" 10 "undefined" 9 "undefined" 8 "etc" 7 "shoulder" 6 "ramp" 5 "Freeway" 4 "Bus lane" 3 "Roundabout" 2 "City Lv2" 1 "City Lv1" 0 "NA";
VAL_ 1173 NAVI_RoadClass 7 "undefined" 6 "undefined" 5 "Freeway" 4 "School" 3 "Street" 2 "Interurban" 1 "City" 0 "NA";
VAL_ 1173 NAVI_SpeedLimit 31 "80mph" 30 "75mph" 29 "70mph" 28 "65mph" 27 "60mph" 26 "55mph" 25 "50mph" 24 "45mph" 23 "40mph" 22 "35mph" 21 "30mph" 20 "25mph" 19 "20mph" 18 "15mph" 17 "10mph" 16 "160 km/h" 15 "150 km/h" 14 "140 km/h" 13 "130 km/h" 12 "120 km/h" 11 "110 km/h" 10 "100 km/h" 9 "90 km/h" 8 "80 km/h" 7 "70 km/h" 6 "60 km/h" 5 "50 km/h" 4 "40 km/h" 3 "30 km/h" 2 "20 km/h" 1 "10 km/h" 0 "No request";
VAL_ 1173 RoomLampMode 1 "Press" 0 "Release";
VAL_ 1173 IVI_ISA_OffsetSpd 15 "Invalid" 14 "reserve" 13 "reserve" 12 "reserve" 11 "5 mph" 10 "0 mph" 9 "-5 mph" 8 "reserve" 7 "reserve" 6 "reserve" 5 "+10 km/h" 4 "+5 km/h" 3 "0 km/h" 2 "-5 km/h" 1 "-10 km/h" 0 "Off";
VAL_ 1173 SOC_ADJ_BUTT 1 "Press" 0 "Release";
VAL_ 1173 CDL_Unlock_Butt 1 "Press" 0 "Release";
VAL_ 1173 CDL_Lock_Butt 1 "Press" 0 "Release";
VAL_ 1173 SOC_Limit_Set 31 "invalid" 26 "~0x1E undefined" 0 "~0x19 50%~100%";
VAL_ 1173 Roll_Eng_Mode 1 "on" 0 "off";
VAL_ 1173 SLIF_BUTT 2 "Invalid" 1 "Pressed" 0 "No request";
VAL_ 1173 TCS_SW_Cmd 3 "Invaild" 2 "Undefined" 1 "Press" 0 "Release";
VAL_ 1173 Roll_Mode_SW_Cmd 3 "Invaild" 2 "Undefined" 1 "Press" 0 "Release";
VAL_ 1173 IVI_ActvDmpDisabSW 3 "Undefined" 2 "Invalid" 1 "Press (>0.5s)" 0 "Release";
VAL_ 1173 IVI_CoastDwSW 3 "Undefined" 2 "Invalid" 1 "Press (>0.5s)" 0 "Release";
VAL_ 1173 IVI_PwrLockSW 3 "Undefined" 2 "Invalid" 1 "Press (>0.5s)" 0 "Release";
VAL_ 1173 IVI_LVChrgFuncSW 3 "Undefined" 2 "Invalid" 1 "Press (>0.5s)" 0 "Release";
VAL_ 1173 IVI_AGSCloseSW 3 "Undefined" 2 "Invalid" 1 "Press (>0.5s)" 0 "Release";
VAL_ 1173 AVM_OFF_Rec_Butt 1 "ON" 0 "OFF";
VAL_ 1173 AVM_parking_excute 3 "remote request" 2 "invalid" 1 "press" 0 "release";
VAL_ 1173 AVM_parking_cancel 2 "invalid" 1 "press" 0 "release";
VAL_ 1173 IVI_DSEATHeater_Cmd 7 "Not used" 6 "Not used" 5 "Not used" 4 "OFF" 3 "High" 2 "Middle" 1 "Low" 0 "No request";
VAL_ 1173 IVI_PSEATHeater_Cmd 7 "Not used" 6 "Not used" 5 "Not used" 4 "OFF" 3 "High" 2 "Middle" 1 "Low" 0 "No request";
VAL_ 1173 WlcmLight_Mode 2 "Mode3" 1 "Mode2" 0 "Mode1";
VAL_ 1173 IVI_CfmTo_Rdy 1 "Press" 0 "Release";
VAL_ 1173 Light_ShowStart_Req 1 "Press" 0 "Release";
VAL_ 1173 Light_ShowStop_Req 1 "Press" 0 "Release";
VAL_ 1173 IVI_TrailerCheckReq_Sta 1 "Press" 0 "Release";
VAL_ 1173 IVI_TrailerModeSW_Sta 1 "ON" 0 "OFF";
VAL_ 1173 IVI_FGSAirInt_Cmd 7 "No Command" 3 "LV3" 2 "LV2" 1 "LV1" 0 "Inactive";
VAL_ 1173 IVI_FGSCh_Cmd 3 "Channel 3" 2 "Channel 2" 1 "Channel 1" 0 "No Command";
VAL_ 1173 IVI_IONSW_Cmd 1 "Press" 0 "Release";
VAL_ 1173 IVI_SWC_ACCMode_Sta 1 "ACC+LFC" 0 "ACC";
VAL_ 1173 IVI_SWC_LUndefined_Sta 15 "Undefined" 14 "Undefined" 13 "Undefined" 12 "Undefined" 11 "Undefined" 10 "LDW Sound" 9 "SWC Heat" 8 "Fan Set" 7 "Temp Set" 6 "Wiper Sensitivity" 5 "Night Mode" 4 "LKA" 3 "NAVI" 2 "Interior Light" 1 "AVM/Rear View" 0 "Drive Mode";
VAL_ 1173 IVI_SWC_RUndefined_Sta 15 "Undefined" 14 "Undefined" 13 "Undefined" 12 "Undefined" 11 "Undefined" 10 "LDW Sound" 9 "SWC Heat" 8 "Fan Set" 7 "Temp Set" 6 "Wiper Sensitivity" 5 "Night Mode" 4 "LKA" 3 "NAVI" 2 "Interior Light" 1 "AVM/Rear View" 0 "Drive Mode";
VAL_ 1173 IVI_ACC_Adaptive_Sta 1 "Adaptive" 0 "Non Adaptive";
VAL_ 1173 IVI_SLIF_Warning_Sta 3 "Reserve" 2 "OFF" 1 "Visual + Sound" 0 "Visual";
VAL_ 1173 IVI_SetTempZon1_Sta 31 "No request" 30 "32 DegC" 29 "31.5 DegC" 28 "31 DegC" 27 "30.5 DegC" 26 "30 DegC" 25 "29.5 DegC" 24 "29 DegC" 23 "28.5 DegC" 22 "28 DegC" 21 "27.5 DegC" 20 "27 DegC" 19 "26.5 DegC" 18 "26 DegC" 17 "25.5 DegC" 16 "25 DegC" 15 "24.5 DegC" 14 "24 DegC" 13 "23.5 DegC" 12 "23 DegC" 11 "22.5 DegC" 10 "22 DegC" 9 "21.5 DegC" 8 "21 DegC" 7 "20.5 DegC" 6 "20 DegC" 5 "19.5 DegC" 4 "19 DegC" 3 "18.5 DegC" 2 "18 DegC" 1 "17.5 DegC" 0 "17 DegC";
VAL_ 1173 IVI_SetTempZon2_Sta 31 "No request" 30 "32 DegC" 29 "31.5 DegC" 28 "31 DegC" 27 "30.5 DegC" 26 "30 DegC" 25 "29.5 DegC" 24 "29 DegC" 23 "28.5 DegC" 22 "28 DegC" 21 "27.5 DegC" 20 "27 DegC" 19 "26.5 DegC" 18 "26 DegC" 17 "25.5 DegC" 16 "25 DegC" 15 "24.5 DegC" 14 "24 DegC" 13 "23.5 DegC" 12 "23 DegC" 11 "22.5 DegC" 10 "22 DegC" 9 "21.5 DegC" 8 "21 DegC" 7 "20.5 DegC" 6 "20 DegC" 5 "19.5 DegC" 4 "19 DegC" 3 "18.5 DegC" 2 "18 DegC" 1 "17.5 DegC" 0 "17 DegC";
VAL_ 1173 IVI_AirIntZ3_Cmd 4 "Level 3" 3 "Level 2" 2 "Level 1" 1 "OFF" 0 "No Request";
VAL_ 1173 IVI_DSEAT_Slide_Cmd 3 "Invalid" 2 "Backward" 1 "Forward" 0 "No Request";
VAL_ 1173 IVI_DSEAT_Recline_Cmd 3 "Invalid" 2 "Backward" 1 "Forward" 0 "No Request";
VAL_ 1173 IVI_DSEAT_Height_Cmd 3 "Invalid" 2 "Down" 1 "Up" 0 "No Request";
VAL_ 1173 IVI_DSEAT_FroEdge_Height_Cmd 3 "Invalid" 2 "Down" 1 "Up" 0 "No Request";
VAL_ 1173 IVI_PSEAT_Slide_Cmd 3 "Invalid" 2 "Backward" 1 "Forward" 0 "No Request";
VAL_ 1173 IVI_PSEAT_Recline_Cmd 3 "Invalid" 2 "Backward" 1 "Forward" 0 "No Request";
VAL_ 1173 IVI_ChargePortSW_Sta 1 "Press" 0 "Release";
VAL_ 1173 IVI_DSEAT_Memory1_Sta 1 "Press" 0 "Release";
VAL_ 1173 IVI_DSEAT_Memory2_Sta 1 "Press" 0 "Release";
VAL_ 1173 IVI_DSEAT_Memory_OPTCLS_Sta 1 "Press" 0 "Release";
VAL_ 1173 DMS_Status 3 "Disable" 2 "Error" 1 "Active" 0 "Off";
VAL_ 1173 DMS_Warning_Distraction 3 "Phone Use" 2 "Short Distraction" 1 "Long Distraction" 0 "No Warning";
VAL_ 1173 DMS_Warning_Fatigue 3 "Sleep" 2 "Microsleep" 1 "Drowsiness" 0 "No Warning";
VAL_ 1173 DMS_Warning_Unresponsive 1 "Unresponsive" 0 "Responsive";
VAL_ 1173 IVI_FWipIntTSet_Cmd 7 "Level5_Max5" 6 "Level4_Max5" 5 "Level3_Max5" 4 "Level2_Max5" 3 "Level3_Max3" 2 "Level2_Max3" 1 "Level1" 0 "No Request";
VAL_ 1173 IVI_CarWash_Mode_Cmd 1 "ON" 0 "OFF";
VAL_ 1173 IVI_Backlight_Sta 1 "ON" 0 "OFF";
VAL_ 1173 IVI_GPS_Long_Dir_Sta 3 "Invalid" 2 "Reserve" 1 "Negative" 0 "Postive";
VAL_ 1173 IVI_GPS_Lat_Dir_Sta 3 "Invalid" 2 "Reserve" 1 "Negative" 0 "Postive";
VAL_ 1173 IVI_IC_Brightness_Sta 127 "Invalid" 100 "Max" 0 "Min";
VAL_ 1173 IVI_Off_Road_Mode_Sta 1 "Press" 0 "Release";
VAL_ 1173 IVI_DMS_NoDriverDetected_Sta 1 "NoDriverDetected" 0 "No Warning";
VAL_ 1173 IVI_DMS_Faceblocked_Sta 1 "Faceblocked" 0 "No Warning";
VAL_ 1282 NM_Meter_PNI 1 "NM PDU contains Partial Network request information" 0 "NM PDU contains no Partial Network request information";
VAL_ 1282 NM_Meter_Active_WU 1 "Node has woken up the network (active Wakeup)" 0 "Node has not woken up the network (passive wakeup)";
VAL_ 1282 NM_Meter_CSB 1 "Start of synchronized shutdown is requested by main coordinator" 0 "Start of synchronized shutdown is not requested by main coordinator";
VAL_ 1282 NM_Meter_Rpt_Msg_Req 1 "Repeat Message State requested" 0 "Repeat Message State not requested";
VAL_ 1282 NM_Meter_ERROR_State 8 "BUS OFF_L2" 4 "BUS OFF_L1" 2 "ERROR PASSIVE" 1 "ERROR ACTIVE" 0 "Inactive";
VAL_ 1312 NM_IVI_PNI 1 "NM PDU contains Partial Network request information" 0 "NM PDU contains no Partial Network request information";
VAL_ 1312 NM_IVI_Active_WU 1 "Node has woken up the network (active Wakeup)" 0 "Node has not woken up the network (passive wakeup)";
VAL_ 1312 NM_IVI_CSB 1 "Start of synchronized shutdown is requested by main coordinator" 0 "Start of synchronized shutdown is not requested by main coordinator";
VAL_ 1312 NM_IVI_Rpt_Msg_Req 1 "Repeat Message State requested" 0 "Repeat Message State not requested";
VAL_ 1312 NM_IVI_ERROR_State 8 "BUS OFF_L2" 4 "BUS OFF_L1" 2 "ERROR PASSIVE" 1 "ERROR ACTIVE" 0 "Inactive";
VAL_ 1330 NM_HMI_PNI 1 "NM PDU contains Partial Network request information" 0 "NM PDU contains no Partial Network request information";
VAL_ 1330 NM_HMI_Active_WU 1 "Node has woken up the network (active Wakeup)" 0 "Node has not woken up the network (passive wakeup)";
VAL_ 1330 NM_HMI_CSB 1 "Start of synchronized shutdown is requested by main coordinator" 0 "Start of synchronized shutdown is not requested by main coordinator";
VAL_ 1330 NM_HMI_Rpt_Msg_Req 1 "Repeat Message State requested" 0 "Repeat Message State not requested";
VAL_ 1330 NM_HMI_ERROR_State 8 "BUS OFF_L2" 4 "BUS OFF_L1" 2 "ERROR PASSIVE" 1 "ERROR ACTIVE" 0 "Inactive";
VAL_ 1184 Telltale_ABSWarning 2 "flash" 1 "on" 0 "Off";
VAL_ 1184 Telltale_BatteryChargeWarning 2 "flash" 1 "on" 0 "Off";
VAL_ 1184 Telltale_EDriveSystem 2 "flash" 1 "on" 0 "Off";
VAL_ 1184 Telltale_EPBError 2 "flash" 1 "on" 0 "Off";
VAL_ 1184 Telltale_HVBatteryFault 2 "flash" 1 "on" 0 "Off";
VAL_ 1184 Telltale_ParkBrakeWarning 2 "flash" 1 "on" 0 "Off";
VAL_ 1184 Telltale_Powerlimitation 2 "flash" 1 "on" 0 "Off";
VAL_ 1184 Telltale_SteeringWarning 2 "flash" 1 "on" 0 "Off";
VAL_ 1184 Telltale_TCSIndicator 2 "flash" 1 "on" 0 "Off";
VAL_ 1184 Telltale_EBMErrSta 2 "Flash" 1 "On" 0 "Off";
VAL_ 857 DSEAT_heater_sta 4 "OFF" 3 "High" 2 "Middle" 1 "Low" 0 "No request";
VAL_ 857 DSEAT_Mode 7 "manual & heater & ventilate" 6 "manual & ventilate" 5 "manual & heater" 4 "power & heater & ventilate" 3 "power & ventilate" 2 "power & heater" 1 "power" 0 "manual";
VAL_ 857 DSEAT_Vent_Sta 4 "OFF" 3 "3(High)" 2 "2(Middle)" 1 "1(Low)" 0 "No Request";
VAL_ 857 PSEAT_heater_sta 4 "OFF" 3 "High" 2 "Middle" 1 "Low" 0 "No request";
VAL_ 857 PSEAT_Mode 7 "manual & heater & ventilate" 6 "manual & ventilate" 5 "manual & heater" 4 "power & heater & ventilate" 3 "power & ventilate" 2 "power & heater" 1 "power" 0 "manual";
VAL_ 857 PSEAT_Vent_Sta 4 "OFF" 3 "3(High)" 2 "2(Middle)" 1 "1(Low)" 0 "No Request";
VAL_ 857 DSEAT_Anti_Sta 1 "on" 0 "off";
VAL_ 857 DSEAT_EntryFun_Sta 1 "on" 0 "off";
VAL_ 857 DSEAT_Error_Sta 1 "Warning Request(IVI POP UP)" 0 "Normal";
VAL_ 857 PSEAT_Error_Sta 1 "Warning Request (IVI POP UP)" 0 "Normal";
VAL_ 857 PTG_Active_Sta 7 "Pinch Reverse" 6 "Stoped Halfway" 5 "Ready to Act" 4 "Power Closing" 3 "Power Opening" 2 "Fully Opened" 1 "Fully Closed" 0 "Signal Not Available";
VAL_ 857 PTG_Sys_Sta 3 "Signal Not Available" 2 "Abnormal" 1 "Normal" 0 "Uninitialized";
VAL_ 857 PTG_AutoStaus 1 "Auto mode" 0 "Manual mode";
VAL_ 857 PTG_Exist 1 "Exist" 0 "Not Exist";
VAL_ 857 PTG_Is_Set_Height 1 "On" 0 "Off";
VAL_ 857 Rr_TMSpd_Nidec 65535 "Invalid";
VAL_ 857 Fr_TMSpd_Nidec 65535 "Invalid";
VAL_ 857 Fr_EDURealTMTq_Nidec 4095 "Invalid";
VAL_ 857 Fr_MotorAvailTq_Nidec 4095 "Invalid";
VAL_ 857 Rr_EDURealTMTq_Nidec 4095 "Invalid";
VAL_ 857 Rr_MotorAvailTq_Nidec 4095 "Invalid";
VAL_ 857 Fr_MCUTemp_Nidec 511 "Invalid";
VAL_ 857 Fr_TMTemp_Nidec 511 "Invalid";
VAL_ 857 Rr_MCUTemp_Nidec 511 "Invalid";
VAL_ 857 Rr_TMTemp_Nidec 511 "Invalid";
VAL_ 857 Fr_MCUTempWarn_Nidec 3 "Invalid" 2 "Reserve" 1 "Warning" 0 "Normal";
VAL_ 857 Fr_TMTempWarn_Nidec 3 "Invalid" 2 "Reserve" 1 "Warning" 0 "Normal";
VAL_ 857 Rr_MCUTempWarn_Nidec 3 "Invalid" 2 "Reserve" 1 "Warning" 0 "Normal";
VAL_ 857 Rr_TMTempWarn_Nidec 3 "Invalid" 2 "Reserve" 1 "Warning" 0 "Normal";
VAL_ 857 Fr_EDUDrtSta_Nidec 1 "Torque Derating" 0 "Normal operation";
VAL_ 857 Rr_EDUDrtSta_Nidec 1 "Torque Derating" 0 "Normal operation";
VAL_ 857 L_Drv_Val_Wdw_Opened 127 "Invalid";
VAL_ 857 L_Pas_Val_Wdw_Opened 127 "Invalid";
VAL_ 857 L_RLD_Val_Wdw_Opened 127 "Invalid";
VAL_ 857 L_RRD_Val_Wdw_Opened 127 "Invalid";
VAL_ 857 FAPWL_01_LIN_Response_Error 1 "Error" 0 "Normal";
VAL_ 857 L_Drv_Motor_Relay_Error 1 "Error" 0 "Normal";
VAL_ 857 L_Drv_Motor_Ripple_Error 1 "Error" 0 "Normal";
VAL_ 857 L_Pas_Motor_Relay_Error 1 "Error" 0 "Normal";
VAL_ 857 L_Pas_Motor_Ripple_Error 1 "Error" 0 "Normal";
VAL_ 857 L_RLD_Motor_Relay_Error 1 "Error" 0 "Normal";
VAL_ 857 L_RLD_Motor_Ripple_Error 1 "Error" 0 "Normal";
VAL_ 857 L_RRD_Motor_Relay_Error 1 "Error" 0 "Normal";
VAL_ 857 L_RRD_Motor_Ripple_Error 1 "Error" 0 "Normal";
VAL_ 857 RAPWL_01_LIN_Response_Error 1 "Error" 0 "Normal";
VAL_ 855 Rr_TMSpd 65535 "Invalid";
VAL_ 855 Fr_TMSpd 65535 "Invalid";
VAL_ 855 Fr_EDURealTMTq 65535 "Invalid";
VAL_ 855 Fr_MotorAvailTq 4095 "Invalid";
VAL_ 855 Rr_EDURealTMTq 65535 "Invalid";
VAL_ 855 Rr_MotorAvailTq 4095 "Invalid";
VAL_ 855 Fr_MCUTemp 511 "Invalid";
VAL_ 855 Fr_TMTemp 511 "Invalid";
VAL_ 855 Rr_MCUTemp 511 "Invalid";
VAL_ 855 Rr_TMTemp 511 "Invalid";
VAL_ 855 BD_DSEAT_Mode_Sta 7 "manual & heater & ventilate" 6 "manual & ventilate" 5 "manual & heater" 4 "power & heater & ventilate" 3 "power & ventilate" 2 "power & heater" 1 "power" 0 "manual";
VAL_ 855 BD_DSEAT_Vent_Sta 3 "3(High)" 2 "2(Middle)" 1 "1(Low)" 0 "OFF";
VAL_ 855 BP_PTG_Active_Sta 7 "Pinch Reverse" 6 "Stoped Halfway" 5 "Ready to Act" 4 "Power Closing" 3 "Power Opening" 2 "Fully Opened" 1 "Fully Closed" 0 "Signal Not Available";
VAL_ 855 BP_PSEAT_Mode_Sta 7 "manual & heater & ventilate" 6 "manual & ventilate" 5 "manual & heater" 4 "power & heater & ventilate" 3 "power & ventilate" 2 "power & heater" 1 "power" 0 "manual";
VAL_ 855 BP_PSEAT_Vent_Sta 3 "3(High)" 2 "2(Middle)" 1 "1(Low)" 0 "OFF";
VAL_ 855 Fr_MCUTempWarn 3 "Invalid" 2 "Reserve" 1 "Warning" 0 "Normal";
VAL_ 855 Fr_TMTempWarn 3 "Invalid" 2 "Reserve" 1 "Warning" 0 "Normal";
VAL_ 855 Rr_MCUTempWarn 3 "Invalid" 2 "Reserve" 1 "Warning" 0 "Normal";
VAL_ 855 Rr_TMTempWarn 3 "Invalid" 2 "Reserve" 1 "Warning" 0 "Normal";
VAL_ 855 BP_PTG_Sys_Sta 3 "Signal Not Available" 2 "Abnormal" 1 "Normal" 0 "Uninitialized";
VAL_ 855 Fr_EDUDrtSta 1 "Torque Derating" 0 "Normal operation";
VAL_ 855 Rr_EDUDrtSta 1 "Torque Derating" 0 "Normal operation";
VAL_ 855 BD_DSEAT_Anti_Sta 1 "on" 0 "off";
VAL_ 855 BD_DSEAT_EntryFun_Sta 1 "on" 0 "off";
VAL_ 855 BD_DSEAT_Error_Sta 1 "Warning Request(IVI POP UP)" 0 "Normal";
VAL_ 855 BP_PTG_Exist_Sta 1 "Exist" 0 "Not Exist";
VAL_ 855 BP_PTG_IsSetHeight_Sta 1 "On" 0 "Off";
VAL_ 855 BP_PSEAT_Error_Sta 1 "Warning Request (IVI POP UP)" 0 "Normal";
VAL_ 855 BD_DSEAT_heater_Sta 3 "3(High)" 2 "2(Middle)" 1 "1(Low)" 0 "OFF";
VAL_ 855 BP_PSEAT_heater_Sta 3 "3(High)" 2 "2(Middle)" 1 "1(Low)" 0 "OFF";
VAL_ 855 MCU_B_R_LLCTempWarn_Sta 3 "Invalid" 2 "Reserve" 1 "Warning" 0 "Normal";
VAL_ 855 MCU_B_F_LLCTempWarn_Sta 3 "Invalid" 2 "Reserve" 1 "Warning" 0 "Normal";
VAL_ 855 SWC2_L_DriveMode_Sta 1 "Press" 0 "Release";
VAL_ 855 SWC2_L_Home_Sta 1 "Press" 0 "Release";
VAL_ 855 SWC2_R_Customize_Sta 1 "Press" 0 "Release";
VAL_ 855 SWC2_R_Left_Sta 1 "Press" 0 "Release";
VAL_ 855 SWC2_R_PageSwitch_Sta 1 "Press" 0 "Release";
VAL_ 855 SWC2_R_Right_Sta 1 "Press" 0 "Release";
VAL_ 855 SWC2_R_ScrollDown_Sta 1 "Press" 0 "Release";
VAL_ 855 SWC2_R_ScrollPress_Sta 1 "Press" 0 "Release";
VAL_ 855 SWC2_R_ScrollUp_Sta 1 "Press" 0 "Release";
VAL_ 855 SWC2_R_VR_Sta 1 "Press" 0 "Release";
VAL_ 855 BP_SEAT_MLVent_Sta 4 "OFF" 3 "3(High)" 2 "2(Middle)" 1 "1(Low)" 0 "NoRequest";
VAL_ 855 BP_SEAT_MRVent_Sta 4 "OFF" 3 "3(High)" 2 "2(Middle)" 1 "1(Low)" 0 "NoRequest";
VAL_ 855 BP_SEAT_LVent_Sta 4 "OFF" 3 "3(High)" 2 "2(Middle)" 1 "1(Low)" 0 "NoRequest";
VAL_ 855 BP_SEAT_RVent_Sta 4 "OFF" 3 "3(High)" 2 "2(Middle)" 1 "1(Low)" 0 "NoRequest";
VAL_ 855 BD_DSEAT_MemSet_Sta 3 "Wait For Set" 2 "Mem2 Set" 1 "Mem1 Set" 0 "Stand By";
VAL_ 855 BD_DSEAT_StopKeepMove_Sta 3 "No Request" 2 "Stop" 1 "Moving" 0 "In position";
VAL_ 855 FDC_BCM_WinLFOpened_Sta 127 "Invalid" 102 "~0x7E undefined";
VAL_ 855 FDC_BCM_WinLROpened_Sta 127 "Invalid" 102 "~0x7E undefined";
VAL_ 855 FDC_BCM_WinRFOpened_Sta 127 "Invalid" 102 "-0x7E undefined";
VAL_ 855 FDC_BCM_WinRROpened_Sta 127 "Invalid" 102 "-0x7E undefined";
VAL_ 855 BD_Door_FHandleClose_Sta 1 "Close" 0 "Not Close";
VAL_ 855 BD_Door_RHandleClose_Sta 1 "Close" 0 "Not Close";
VAL_ 855 BP_Door_FHandleClose_Sta 1 "Close" 0 "Not Close";
VAL_ 855 BP_Door_RHandleClose_Sta 1 "Close" 0 "Not Close";
VAL_ 552 AGS_Actual_Position 240 "90^Deg" 208 "78^Deg" 176 "66^Deg" 144 "54^Deg" 112 "42^Deg" 80 "30^Deg" 48 "18^Deg" 16 "6^Deg" 224 "84^Deg" 192 "72^Deg" 160 "60^Deg" 128 "48^Deg" 96 "36^Deg" 64 "24^Deg" 32 "12^Deg" 0 "0^Deg";
VAL_ 552 AGS_Low_Voltage_Error 1 "ERROR" 0 "NO_Voltage_ERROR";
VAL_ 552 AGS_Temperature_Error 1 "ERROR" 0 "NO_ERROR";
VAL_ 552 AGS_Sensor_Error 1 "ERROR" 0 "NO_ERROR";
VAL_ 552 AGS_Electrical_Error 1 "ERROR" 0 "NO_ERROR";
VAL_ 552 AGS_Calibration_Indicated 1 "CALIBRATION_REQ" 0 "NO_CALIBRATION";
VAL_ 552 AGS_Calibration_Active 1 "Caliberation_Process_active" 0 "Caliberation_process_inactive";
VAL_ 552 AGS_Actuator_Fault 1 "ERROR" 0 "NO_ERROR";
VAL_ 552 AGS_Actuator_Blocked 1 "ERROR" 0 "NO_ERROR";
VAL_ 552 AGS_LINResponse_Error 1 "ERROR" 0 "NO_ERROR";
VAL_ 552 ION_IONErr_Sta 3 "AirClngErrSts_OpenCircuit" 2 "AirClngErrSts_ShortCircuit" 1 "AirClngErrSts_Err" 0 "AirClngErrSts_NoErr";
VAL_ 552 ION_IONRespErr_Sta 1 "Error" 0 "Normal";
VAL_ 552 ION_ION_Sta 1 "ON" 0 "OFF";
VAL_ 552 FGS_LifeHole3_Sta 511 "Invalid" 361 "~0x1FE Reserved";
VAL_ 552 FGS_LifeHole2_Sta 511 "Invalid" 361 "~0x1FE Reserved";
VAL_ 552 FGS_LifeHole1_Sta 511 "Invalid" 361 "~0x1FE Reserved";
VAL_ 552 FGS_Channel3TypeRsp_Sta 15 "Invalid" 14 "Reserved" 13 "Reserved" 12 "Reserved" 11 "Reserved" 10 "Reserved" 9 "Reserved" 8 "Reserved" 7 "Type 7" 6 "Type 6" 5 "Type 5" 4 "Type 4" 3 "Type 3" 2 "Type 2" 1 "Type 1" 0 "Inactive";
VAL_ 552 FGS_Channel2TypeRsp_Sta 15 "Invalid" 14 "Reserved" 13 "Reserved" 12 "Reserved" 11 "Reserved" 10 "Reserved" 9 "Reserved" 8 "Reserved" 7 "Type 7" 6 "Type 6" 5 "Type 5" 4 "Type 4" 3 "Type 3" 2 "Type 2" 1 "Type 1" 0 "Inactive";
VAL_ 552 FGS_Channel1TypeRsp_Sta 15 "Invalid" 14 "Reserved" 13 "Reserved" 12 "Reserved" 11 "Reserved" 10 "Reserved" 9 "Reserved" 8 "Reserved" 7 "Type 7" 6 "Type 6" 5 "Type 5" 4 "Type 4" 3 "Type 3" 2 "Type 2" 1 "Type 1" 0 "Inactive";
VAL_ 552 FGS_BlowerErr_Sta 1 "Error" 0 "No Error";
VAL_ 552 FGS_IntenRsp_Sta 15 "Invalid" 14 "Reserved" 13 "Reserved" 12 "Reserved" 11 "Reserved" 10 "Reserved" 9 "Reserved" 8 "Reserved" 7 "Reserved" 6 "Reserved" 5 "Reserved" 4 "Level 4" 3 "Level 3" 2 "Level 2" 1 "Level 1" 0 "Inactive";
VAL_ 552 FGS_MotorErr_Sta 1 "Error" 0 "No Error";
VAL_ 552 FGS_TypRsp_Sta 7 "Reserved" 6 "Reserved" 5 "Reserved" 4 "Reserved" 3 "Channel 3" 2 "Channel 2" 1 "Channel 1" 0 "Inactive";
VAL_ 552 FGS_LINResponseErr_Sta 1 "Error" 0 "No Error";
VAL_ 552 FGS_StsRsp_Sta 1 "ON" 0 "OFF";
VAL_ 552 FGS_Channel_Index_Sta 3 "Channel 3" 2 "Channel 2" 1 "Channel 1" 0 "Inactive";
VAL_ 1169 HMI_ACBtn_Cmd 1 "Press" 0 "Release";
VAL_ 1169 HMI_ACAutoBtn_Cmd 1 "Press" 0 "Release";
VAL_ 1169 HMI_ACRecycleBtn_Cmd 1 "Press" 0 "Release";
VAL_ 1169 HMI_ACFrDefogBtn_Cmd 1 "Press" 0 "Release";
VAL_ 1169 HMI_ZLSetTP_Cmd 1 "Press" 0 "Release";
VAL_ 1169 HMI_ZLSetTM_Cmd 1 "Press" 0 "Release";
VAL_ 1169 HMI_ZRSetTP_Cmd 1 "Press" 0 "Release";
VAL_ 1169 HMI_ZRSetTM_Cmd 1 "Press" 0 "Release";
VAL_ 1169 HMI_ACWindDirP_Cmd 1 "Press" 0 "Release";
VAL_ 1169 HMI_ACWindDirM_Cmd 1 "Press" 0 "Release";
VAL_ 1169 HMI_ACAirIntP_Cmd 1 "Press" 0 "Release";
VAL_ 1169 HMI_ACAirIntM_Cmd 1 "Press" 0 "Release";
VAL_ 1169 HMI_BCMPostDefogBtn_Cmd 1 "Press" 0 "Release";
VAL_ 1169 HMI_AutoInterLight_Cmd 1 "Press" 0 "Release";
VAL_ 1169 HMI_PSEAT_LevelDown_Cmd 1 "Press" 0 "Release";
VAL_ 1169 HMI_PSEAT_LevelUp_Cmd 1 "Press" 0 "Release";
VAL_ 1169 HMI_DSEAT_LevelDown_Cmd 1 "Press" 0 "Release";
VAL_ 1169 HMI_DSEAT_LevelUp_Cmd 1 "Press" 0 "Release";
VAL_ 1169 HMI_Function6_LevelDown_Cmd 1 "Press" 0 "Release";
VAL_ 1169 HMI_Function5_LevelDown_Cmd 1 "Press" 0 "Release";
VAL_ 1169 HMI_Function4_LevelDown_Cmd 1 "Press" 0 "Release";
VAL_ 1169 HMI_Function3_LevelDown_Cmd 1 "Press" 0 "Release";
VAL_ 1169 HMI_Function2_LevelDown_Cmd 1 "Press" 0 "Release";
VAL_ 1169 HMI_Function1_LevelDown_Cmd 1 "Press" 0 "Release";
VAL_ 1169 HMI_Function6_LevelUp_Cmd 1 "Press" 0 "Release";
VAL_ 1169 HMI_Function5_LevelUp_Cmd 1 "Press" 0 "Release";
VAL_ 1169 HMI_Function4_LevelUp_Cmd 1 "Press" 0 "Release";
VAL_ 1169 HMI_Function3_LevelUp_Cmd 1 "Press" 0 "Release";
VAL_ 1169 HMI_Function2_LevelUp_Cmd 1 "Press" 0 "Release";
VAL_ 1169 HMI_Function1_LevelUp_Cmd 1 "Press" 0 "Release";
VAL_ 1175 IVI_CLBlower_Y_Sta 127 "No Request" 126 "OFF";
VAL_ 1175 IVI_CLBlower_Z_Sta 127 "No Request";
VAL_ 1175 IVI_CRBlower_Y_Sta 127 "No Request" 126 "OFF";
VAL_ 1175 IVI_CRBlower_Z_Sta 127 "No Request";
VAL_ 1175 IVI_LBlower_Y_Sta 127 "No Request" 126 "OFF";
VAL_ 1175 IVI_LBlower_Z_Sta 127 "No Request";
VAL_ 1175 IVI_RBlower_Y_Sta 127 "No Request" 126 "OFF";
VAL_ 1175 IVI_RBlower_Z_Sta 127 "No Request";
VAL_ 1175 IVI_LSEATvent_Cmd 4 "OFF" 3 "3(High)" 2 "2(Middle)" 1 "1(Low)" 0 "NoRequest";
VAL_ 1175 IVI_MLSEATvent_Cmd 4 "OFF" 3 "3(High)" 2 "2(Middle)" 1 "1(Low)" 0 "NoRequest";
VAL_ 1175 IVI_MRSEATvent_Cmd 4 "OFF" 3 "3(High)" 2 "2(Middle)" 1 "1(Low)" 0 "NoRequest";
VAL_ 1175 IVI_RSEATvent_Cmd 4 "OFF" 3 "3(High)" 2 "2(Middle)" 1 "1(Low)" 0 "NoRequest";
VAL_ 1175 IVI_LBlower_Mode_Sta 3 "Balanced" 2 "Sweep" 1 "Manual" 0 "No Request";
VAL_ 1175 IVI_MLFootLift_Cmd 2 "Down" 1 "Up" 0 "StandBy";
VAL_ 1175 IVI_MLRecliner_Cmd 2 "Backward" 1 "Forward" 0 "StandBy";
VAL_ 1175 IVI_MLSeatLift_Cmd 2 "Down" 1 "Up" 0 "StandBy";
VAL_ 1175 IVI_MLSlider_Cmd 2 "Backward" 1 "Forward" 0 "StandBy";
VAL_ 1175 IVI_MRFootLift_Cmd 2 "Down" 1 "Up" 0 "StandBy";
VAL_ 1175 IVI_MRRecliner_Cmd 2 "Backward" 1 "Forward" 0 "StandBy";
VAL_ 1175 IVI_MRSeatLift_Cmd 2 "Down" 1 "Up" 0 "StandBy";
VAL_ 1175 IVI_MRSlider_Cmd 2 "Backward" 1 "Forward" 0 "StandBy";
VAL_ 1175 IVI_RBlower_Mode_Sta 3 "Balanced" 2 "Sweep" 1 "Manual" 0 "No Request";
VAL_ 1175 IVI_MLFMost_Cmd 1 "Press" 0 "Release";
VAL_ 1175 IVI_MLNapMode_Cmd 1 "Press" 0 "Release";
VAL_ 1175 IVI_MLRestore_Cmd 1 "Press" 0 "Release";
VAL_ 1175 IVI_MLSldRestore_Cmd 1 "Press" 0 "Release";
VAL_ 1175 IVI_MLZeroGravity_Cmd 1 "Press" 0 "Release";
VAL_ 1175 IVI_MRFMost_Cmd 1 "Press" 0 "Release";
VAL_ 1175 IVI_MRNapMode_Cmd 1 "Press" 0 "Release";
VAL_ 1175 IVI_MRRestore_Cmd 1 "Press" 0 "Release";
VAL_ 1175 IVI_MRSldRestore_Cmd 1 "Press" 0 "Release";
VAL_ 1175 IVI_MRZeroGravity_Cmd 1 "Press" 0 "Release";
VAL_ 1175 IVI_HMI_CustmiKEY_Sta 8 "Key8" 7 "Key7" 6 "Key6" 5 "Key5" 4 "Key4" 3 "Key3" 2 "Key2" 1 "Key1" 0 "No Request";
VAL_ 1175 IVI_HMI_CustmiFun_Sta 15 "Reserved" 14 "Reserved" 13 "Reserved" 12 "Reserved" 11 "Reserved" 10 "Reserved" 9 "Star Button" 8 "Passenger Ventilated and/or heated seats" 7 "Driver Ventilated and/or heated seats" 6 "Rear Defrost" 5 "HVAC Defrost" 4 "IVI Volume" 3 "HVAC Fan Level" 2 "Passenger Seat Temp Set" 1 "Driver Seat Temp Set" 0 "No Request";
VAL_ 1175 IVI_SOS_Call_Sta 3 "End Calling or Hung Up" 2 "In Calling" 1 "In Dialing" 0 "No Request";
VAL_ 1175 IVI_XWDMode_Cmd 3 "AWD" 2 "RWD" 1 "FWD" 0 "Auto";
VAL_ 1175 IVI_RollMod_atCarWash_Sta 1 "Press" 0 "Release";
VAL_ 1175 IVI_SnowMode_Cmd 1 "ON" 0 "OFF";
VAL_ 1175 IVI_UserTakeOver_APS_Sta 1 "Press" 0 "Release";
VAL_ 1175 IVI_Zon1WindDirSWReq_Sta 1 "Press" 0 "Release";
VAL_ 1175 IVI_PSDManualPower_Sta 1 "Power Mode" 0 "Manual Mode";
VAL_ 1175 IVI_RightPSDOpenClose_Cmd 1 "Request" 0 "No Request";
VAL_ 1175 IVI_LeftPSDOpenClose_Cmd 1 "Request" 0 "No Request";
